// *************************************************************************** *
// *                                                                           *
// * Description:         CANDB File                                           *
// * Generated at:        2023-04-23 21:52                                     *
// * System:              SDB22400                                             *
// * Variant:             KX11_A2_ADCU2_VCU2_PCM                               *
// * Network:             ChassisCAN1                                          *
// *                                                                           *
// *************************************************************************** *
VERSION "ChassisCAN1"

NS_ :

BS_ :

BU_ :  ASDM BBM ECM ETC PSCM1 SAS TCM VDDM

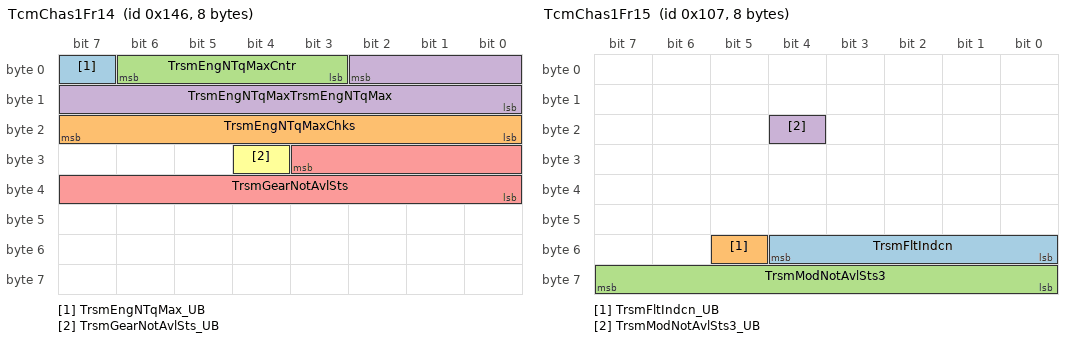
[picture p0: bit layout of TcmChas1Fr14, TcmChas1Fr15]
BO_ 326 TcmChas1Fr14 : 8 TCM
 SG_ TrsmEngNTqMax_UB : 7|1@0+ (1,0) [0|1] "" ECM
 SG_ TrsmEngNTqMaxChks : 23|8@0+ (1.0,0.0) [0.0|255.0] "Unitless" ECM
 SG_ TrsmEngNTqMaxCntr : 6|4@0+ (1.0,0.0) [0.0|15.0] "Unitless" ECM
 SG_ TrsmEngNTqMaxTrsmEngNTqMax : 2|11@0+ (1.0,-1024.0) [-1024.0|1023.0] "NewtonMeter" ECM
 SG_ TrsmGearNotAvlSts : 27|12@0+ (1.0,0.0) [0.0|4095.0] "Unitless" ECM
 SG_ TrsmGearNotAvlSts_UB : 28|1@0+ (1,0) [0|1] "" ECM

BO_ 263 TcmChas1Fr15 : 8 TCM
 SG_ TrsmFltIndcn : 52|5@0+ (1,0) [0|31] "" ECM,VDDM
 SG_ TrsmFltIndcn_UB : 53|1@0+ (1,0) [0|1] "" ECM,VDDM
 SG_ TrsmModNotAvlSts3 : 63|8@0+ (1.0,0.0) [0.0|255.0] "Unitless" ECM
 SG_ TrsmModNotAvlSts3_UB : 20|1@0+ (1,0) [0|1] "" ECM

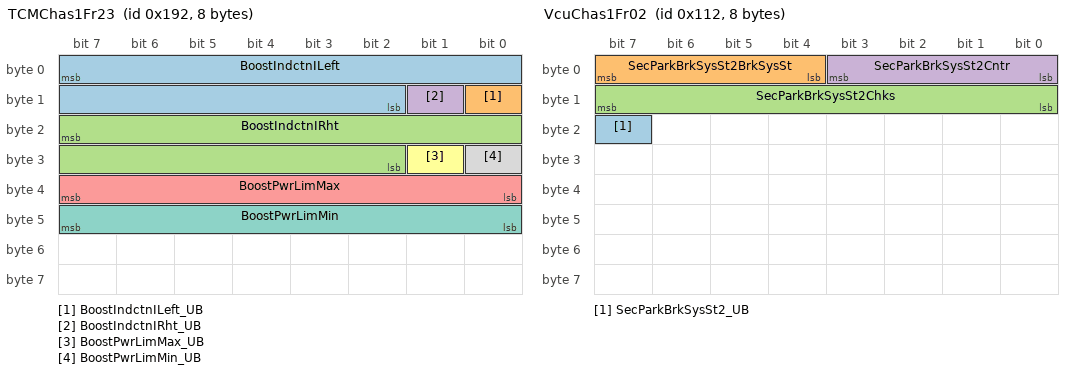
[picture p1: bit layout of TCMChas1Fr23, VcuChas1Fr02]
BO_ 402 TCMChas1Fr23 : 8 TCM
 SG_ BoostIndctnILeft : 7|14@0+ (0.1,-818.8) [-818.8|819.2] "A" ECM
 SG_ BoostIndctnILeft_UB : 8|1@0+ (1,0) [0|1] "" ECM
 SG_ BoostIndctnIRht : 23|14@0+ (0.1,-818.8) [-818.8|819.2] "A" ECM
 SG_ BoostIndctnIRht_UB : 9|1@0+ (1,0) [0|1] "" ECM
 SG_ BoostPwrLimMax : 39|8@0+ (1.0,0.0) [0.0|255.0] "kW" ECM
 SG_ BoostPwrLimMax_UB : 25|1@0+ (1,0) [0|1] "" ECM
 SG_ BoostPwrLimMin : 47|8@0+ (1.0,-255.0) [-255.0|0.0] "kW" ECM
 SG_ BoostPwrLimMin_UB : 24|1@0+ (1,0) [0|1] "" ECM

BO_ 1328 TcmChas1NMFr : 8 TCM
 SG_ PNC16_TCM : 16|1@0+ (1,0) [0|0] "" SAS
 SG_ PNC17_TCM : 17|1@0+ (1,0) [0|0] "" SAS
 SG_ PNC18_TCM : 18|1@0+ (1,0) [0|0] "" SAS
 SG_ PNC19_TCM : 19|1@0+ (1,0) [0|0] "" SAS
 SG_ PNC20_TCM : 20|1@0+ (1,0) [0|0] "" SAS
 SG_ PNC21_TCM : 21|1@0+ (1,0) [0|0] "" SAS
 SG_ PNC22_TCM : 22|1@0+ (1,0) [0|0] "" SAS
 SG_ PNC23_TCM : 23|1@0+ (1,0) [0|0] "" SAS
 SG_ PNC24_TCM : 24|1@0+ (1,0) [0|0] "" SAS
 SG_ PNC25_TCM : 25|1@0+ (1,0) [0|0] "" SAS
 SG_ PNC26_TCM : 26|1@0+ (1,0) [0|0] "" SAS
 SG_ PNC27_TCM : 27|1@0+ (1,0) [0|0] "" SAS
 SG_ PNC28_TCM : 28|1@0+ (1,0) [0|0] "" SAS
 SG_ PNC29_TCM : 29|1@0+ (1,0) [0|0] "" SAS
 SG_ PNC30_TCM : 30|1@0+ (1,0) [0|0] "" SAS
 SG_ PNC31_TCM : 31|1@0+ (1,0) [0|0] "" SAS
 SG_ PNC32_TCM : 32|1@0+ (1,0) [0|0] "" SAS
 SG_ PNC33_TCM : 33|1@0+ (1,0) [0|0] "" SAS
 SG_ PNC34_TCM : 34|1@0+ (1,0) [0|0] "" SAS
 SG_ PNC35_TCM : 35|1@0+ (1,0) [0|0] "" SAS
 SG_ PNC36_TCM : 36|1@0+ (1,0) [0|0] "" SAS
 SG_ PNC37_TCM : 37|1@0+ (1,0) [0|0] "" SAS
 SG_ PNC38_TCM : 38|1@0+ (1,0) [0|0] "" SAS
 SG_ PNC39_TCM : 39|1@0+ (1,0) [0|0] "" SAS
 SG_ PNC40_TCM : 40|1@0+ (1,0) [0|0] "" SAS
 SG_ PNC41_TCM : 41|1@0+ (1,0) [0|0] "" SAS
 SG_ PNC42_TCM : 42|1@0+ (1,0) [0|0] "" SAS
 SG_ NM_PNI_TCM : 14|1@0+ (1,0) [0|0] "" SAS
 SG_ NM_AW_TCM : 12|1@0+ (1,0) [0|0] "" SAS
 SG_ NM_CS_TCM : 11|1@0+ (1,0) [0|0] "" SAS
 SG_ NM_RMR_TCM : 8|1@0+ (1,0) [0|0] "" SAS
 SG_ NM_NodeID_TCM : 7|8@0+ (1,0) [0|0] "" SAS

BO_ 756 TCMChas1VfcFr19 : 8 TCM
 SG_ VFCVectorPCMBlockID : 1|2@0+ (1.0,0.0) [0.0|3.0] "Unitless" ETC
 SG_ VFCVectorPCMVFCid0 : 2|1@0+ (1,0) [0|1] "" ETC
 SG_ VFCVectorPCMVFCid1 : 3|1@0+ (1,0) [0|1] "" ETC
 SG_ VFCVectorPCMVFCid10 : 12|1@0+ (1,0) [0|1] "" ETC
 SG_ VFCVectorPCMVFCid11 : 13|1@0+ (1,0) [0|1] "" ETC
 SG_ VFCVectorPCMVFCid12 : 14|1@0+ (1,0) [0|1] "" ETC
 SG_ VFCVectorPCMVFCid13 : 15|1@0+ (1,0) [0|1] "" ETC
 SG_ VFCVectorPCMVFCid14 : 16|1@0+ (1,0) [0|1] "" ETC
 SG_ VFCVectorPCMVFCid15 : 17|1@0+ (1,0) [0|1] "" ETC
 SG_ VFCVectorPCMVFCid16 : 18|1@0+ (1,0) [0|1] "" ETC
 SG_ VFCVectorPCMVFCid17 : 19|1@0+ (1,0) [0|1] "" ETC
 SG_ VFCVectorPCMVFCid18 : 20|1@0+ (1,0) [0|1] "" ETC
 SG_ VFCVectorPCMVFCid19 : 21|1@0+ (1,0) [0|1] "" ETC
 SG_ VFCVectorPCMVFCid2 : 4|1@0+ (1,0) [0|1] "" ETC
 SG_ VFCVectorPCMVFCid20 : 22|1@0+ (1,0) [0|1] "" ETC
 SG_ VFCVectorPCMVFCid21 : 23|1@0+ (1,0) [0|1] "" ETC
 SG_ VFCVectorPCMVFCid22 : 24|1@0+ (1,0) [0|1] "" ETC
 SG_ VFCVectorPCMVFCid23 : 25|1@0+ (1,0) [0|1] "" ETC
 SG_ VFCVectorPCMVFCid24 : 26|1@0+ (1,0) [0|1] "" ETC
 SG_ VFCVectorPCMVFCid25 : 27|1@0+ (1,0) [0|1] "" ETC
 SG_ VFCVectorPCMVFCid26 : 28|1@0+ (1,0) [0|1] "" ETC
 SG_ VFCVectorPCMVFCid27 : 29|1@0+ (1,0) [0|1] "" ETC
 SG_ VFCVectorPCMVFCid28 : 30|1@0+ (1,0) [0|1] "" ETC
 SG_ VFCVectorPCMVFCid29 : 31|1@0+ (1,0) [0|1] "" ETC
 SG_ VFCVectorPCMVFCid3 : 5|1@0+ (1,0) [0|1] "" ETC
 SG_ VFCVectorPCMVFCid30 : 32|1@0+ (1,0) [0|1] "" ETC
 SG_ VFCVectorPCMVFCid31 : 33|1@0+ (1,0) [0|1] "" ETC
 SG_ VFCVectorPCMVFCid32 : 34|1@0+ (1,0) [0|1] "" ETC
 SG_ VFCVectorPCMVFCid33 : 35|1@0+ (1,0) [0|1] "" ETC
 SG_ VFCVectorPCMVFCid34 : 36|1@0+ (1,0) [0|1] "" ETC
 SG_ VFCVectorPCMVFCid35 : 37|1@0+ (1,0) [0|1] "" ETC
 SG_ VFCVectorPCMVFCid36 : 38|1@0+ (1,0) [0|1] "" ETC
 SG_ VFCVectorPCMVFCid37 : 39|1@0+ (1,0) [0|1] "" ETC
 SG_ VFCVectorPCMVFCid38 : 40|1@0+ (1,0) [0|1] "" ETC
 SG_ VFCVectorPCMVFCid39 : 41|1@0+ (1,0) [0|1] "" ETC
 SG_ VFCVectorPCMVFCid4 : 6|1@0+ (1,0) [0|1] "" ETC
 SG_ VFCVectorPCMVFCid40 : 42|1@0+ (1,0) [0|1] "" ETC
 SG_ VFCVectorPCMVFCid41 : 43|1@0+ (1,0) [0|1] "" ETC
 SG_ VFCVectorPCMVFCid42 : 44|1@0+ (1,0) [0|1] "" ETC
 SG_ VFCVectorPCMVFCid43 : 45|1@0+ (1,0) [0|1] "" ETC
 SG_ VFCVectorPCMVFCid44 : 46|1@0+ (1,0) [0|1] "" ETC
 SG_ VFCVectorPCMVFCid45 : 47|1@0+ (1,0) [0|1] "" ETC
 SG_ VFCVectorPCMVFCid46 : 48|1@0+ (1,0) [0|1] "" ETC
 SG_ VFCVectorPCMVFCid47 : 49|1@0+ (1,0) [0|1] "" ETC
 SG_ VFCVectorPCMVFCid48 : 50|1@0+ (1,0) [0|1] "" ETC
 SG_ VFCVectorPCMVFCid49 : 51|1@0+ (1,0) [0|1] "" ETC
 SG_ VFCVectorPCMVFCid5 : 7|1@0+ (1,0) [0|1] "" ETC
 SG_ VFCVectorPCMVFCid50 : 52|1@0+ (1,0) [0|1] "" ETC
 SG_ VFCVectorPCMVFCid51 : 53|1@0+ (1,0) [0|1] "" ETC
 SG_ VFCVectorPCMVFCid52 : 54|1@0+ (1,0) [0|1] "" ETC
 SG_ VFCVectorPCMVFCid53 : 55|1@0+ (1,0) [0|1] "" ETC
 SG_ VFCVectorPCMVFCid54 : 56|1@0+ (1,0) [0|1] "" ETC
 SG_ VFCVectorPCMVFCid55 : 57|1@0+ (1,0) [0|1] "" ETC
 SG_ VFCVectorPCMVFCid56 : 58|1@0+ (1,0) [0|1] "" ETC
 SG_ VFCVectorPCMVFCid57 : 59|1@0+ (1,0) [0|1] "" ETC
 SG_ VFCVectorPCMVFCid58 : 60|1@0+ (1,0) [0|1] "" ETC
 SG_ VFCVectorPCMVFCid59 : 61|1@0+ (1,0) [0|1] "" ETC
 SG_ VFCVectorPCMVFCid6 : 8|1@0+ (1,0) [0|1] "" ETC
 SG_ VFCVectorPCMVFCid60 : 62|1@0+ (1,0) [0|1] "" ETC
 SG_ VFCVectorPCMVFCid61 : 63|1@0+ (1,0) [0|1] "" ETC
 SG_ VFCVectorPCMVFCid7 : 9|1@0+ (1,0) [0|1] "" ETC
 SG_ VFCVectorPCMVFCid8 : 10|1@0+ (1,0) [0|1] "" ETC
 SG_ VFCVectorPCMVFCid9 : 11|1@0+ (1,0) [0|1] "" ETC

BO_ 274 VcuChas1Fr02 : 8 VDDM
 SG_ SecParkBrkSysSt2_UB : 23|1@0+ (1,0) [0|1] "" BBM
 SG_ SecParkBrkSysSt2BrkSysSt : 7|4@0+ (1,0) [0|15] "" BBM
 SG_ SecParkBrkSysSt2Chks : 15|8@0+ (1.0,0.0) [0.0|255.0] "Unitless" BBM
 SG_ SecParkBrkSysSt2Cntr : 3|4@0+ (1.0,0.0) [0.0|15.0] "Unitless" BBM

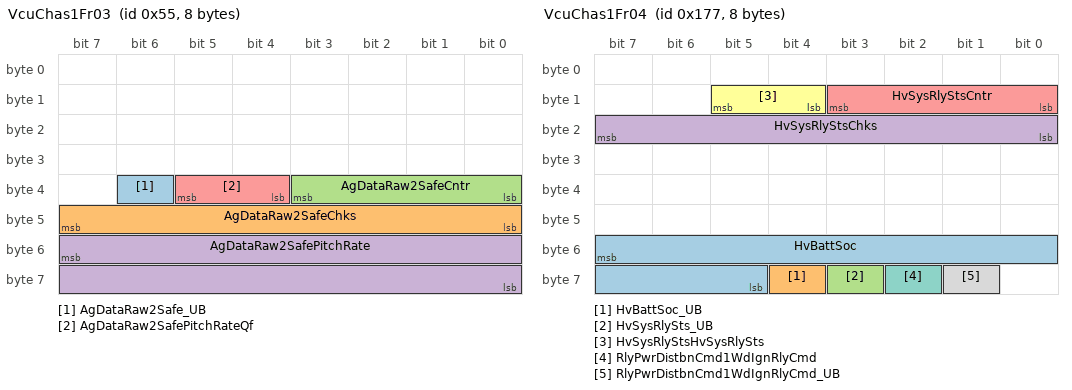
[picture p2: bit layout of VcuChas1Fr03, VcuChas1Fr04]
BO_ 85 VcuChas1Fr03 : 8 VDDM
 SG_ AgDataRaw2Safe_UB : 38|1@0+ (1,0) [0|1] "" Vector__XXX
 SG_ AgDataRaw2SafeChks : 47|8@0+ (1.0,0.0) [0.0|255.0] "Unitless" Vector__XXX
 SG_ AgDataRaw2SafeCntr : 35|4@0+ (1.0,0.0) [0.0|15.0] "Unitless" Vector__XXX
 SG_ AgDataRaw2SafePitchRate : 55|16@0- (0.000244140625,0.0) [-6.0|6.0] "rad/s" Vector__XXX
 SG_ AgDataRaw2SafePitchRateQf : 37|2@0+ (1,0) [0|3] "" Vector__XXX

BO_ 375 VcuChas1Fr04 : 8 VDDM
 SG_ HvBattSoc : 55|11@0+ (0.05,0.0) [0.0|100.0] "%" Vector__XXX
 SG_ HvBattSoc_UB : 60|1@0+ (1,0) [0|1] "" Vector__XXX
 SG_ HvSysRlySts_UB : 59|1@0+ (1,0) [0|1] "" Vector__XXX
 SG_ HvSysRlyStsChks : 23|8@0+ (1.0,0.0) [0.0|255.0] "Unitless" Vector__XXX
 SG_ HvSysRlyStsCntr : 11|4@0+ (1.0,0.0) [0.0|15.0] "Unitless" Vector__XXX
 SG_ HvSysRlyStsHvSysRlySts : 13|2@0+ (1,0) [0|3] "" Vector__XXX
 SG_ RlyPwrDistbnCmd1WdIgnRlyCmd : 58|1@0+ (1,0) [0|1] "" Vector__XXX
 SG_ RlyPwrDistbnCmd1WdIgnRlyCmd_UB : 57|1@0+ (1,0) [0|1] "" Vector__XXX

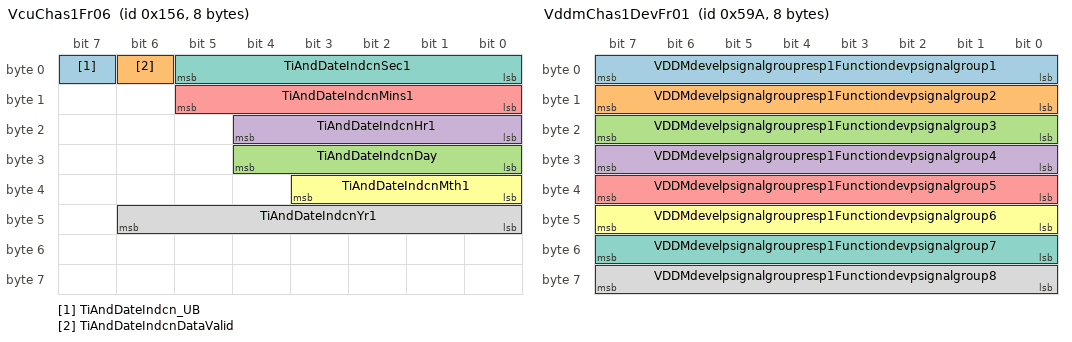
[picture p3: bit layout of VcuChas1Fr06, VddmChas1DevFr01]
BO_ 342 VcuChas1Fr06 : 8 VDDM
 SG_ TiAndDateIndcn_UB : 7|1@0+ (1,0) [0|1] "" Vector__XXX
 SG_ TiAndDateIndcnDataValid : 6|1@0+ (1,0) [0|1] "" Vector__XXX
 SG_ TiAndDateIndcnDay : 28|5@0+ (1.0,0.0) [1.0|31.0] "Days" Vector__XXX
 SG_ TiAndDateIndcnHr1 : 20|5@0+ (1.0,0.0) [0.0|23.0] "hours" Vector__XXX
 SG_ TiAndDateIndcnMins1 : 13|6@0+ (1.0,0.0) [0.0|59.0] "Mins" Vector__XXX
 SG_ TiAndDateIndcnMth1 : 35|4@0+ (1.0,0.0) [1.0|12.0] "Month" Vector__XXX
 SG_ TiAndDateIndcnSec1 : 5|6@0+ (1.0,0.0) [0.0|59.0] "s" Vector__XXX
 SG_ TiAndDateIndcnYr1 : 46|7@0+ (1.0,0.0) [0.0|99.0] "Year" Vector__XXX

BO_ 1365 VcuChas1VFCVectorFr : 8 VDDM
 SG_ VFCVectorVCUBlockID : 1|2@0+ (1.0,0.0) [0.0|3.0] "Unitless" ETC
 SG_ VFCVectorVCUVFCid0 : 2|1@0+ (1,0) [0|1] "" ETC
 SG_ VFCVectorVCUVFCid1 : 3|1@0+ (1,0) [0|1] "" ETC
 SG_ VFCVectorVCUVFCid10 : 12|1@0+ (1,0) [0|1] "" ETC
 SG_ VFCVectorVCUVFCid11 : 13|1@0+ (1,0) [0|1] "" ETC
 SG_ VFCVectorVCUVFCid12 : 14|1@0+ (1,0) [0|1] "" ETC
 SG_ VFCVectorVCUVFCid13 : 15|1@0+ (1,0) [0|1] "" ETC
 SG_ VFCVectorVCUVFCid14 : 16|1@0+ (1,0) [0|1] "" ETC
 SG_ VFCVectorVCUVFCid15 : 17|1@0+ (1,0) [0|1] "" ETC
 SG_ VFCVectorVCUVFCid16 : 18|1@0+ (1,0) [0|1] "" ETC
 SG_ VFCVectorVCUVFCid17 : 19|1@0+ (1,0) [0|1] "" ETC
 SG_ VFCVectorVCUVFCid18 : 20|1@0+ (1,0) [0|1] "" ETC
 SG_ VFCVectorVCUVFCid19 : 21|1@0+ (1,0) [0|1] "" ETC
 SG_ VFCVectorVCUVFCid2 : 4|1@0+ (1,0) [0|1] "" ETC
 SG_ VFCVectorVCUVFCid20 : 22|1@0+ (1,0) [0|1] "" ETC
 SG_ VFCVectorVCUVFCid21 : 23|1@0+ (1,0) [0|1] "" ETC
 SG_ VFCVectorVCUVFCid22 : 24|1@0+ (1,0) [0|1] "" ETC
 SG_ VFCVectorVCUVFCid23 : 25|1@0+ (1,0) [0|1] "" ETC
 SG_ VFCVectorVCUVFCid24 : 26|1@0+ (1,0) [0|1] "" ETC
 SG_ VFCVectorVCUVFCid25 : 27|1@0+ (1,0) [0|1] "" ETC
 SG_ VFCVectorVCUVFCid26 : 28|1@0+ (1,0) [0|1] "" ETC
 SG_ VFCVectorVCUVFCid27 : 29|1@0+ (1,0) [0|1] "" ETC
 SG_ VFCVectorVCUVFCid28 : 30|1@0+ (1,0) [0|1] "" ETC
 SG_ VFCVectorVCUVFCid29 : 31|1@0+ (1,0) [0|1] "" ETC
 SG_ VFCVectorVCUVFCid3 : 5|1@0+ (1,0) [0|1] "" ETC
 SG_ VFCVectorVCUVFCid30 : 32|1@0+ (1,0) [0|1] "" ETC
 SG_ VFCVectorVCUVFCid31 : 33|1@0+ (1,0) [0|1] "" ETC
 SG_ VFCVectorVCUVFCid32 : 34|1@0+ (1,0) [0|1] "" ETC
 SG_ VFCVectorVCUVFCid33 : 35|1@0+ (1,0) [0|1] "" ETC
 SG_ VFCVectorVCUVFCid34 : 36|1@0+ (1,0) [0|1] "" ETC
 SG_ VFCVectorVCUVFCid35 : 37|1@0+ (1,0) [0|1] "" ETC
 SG_ VFCVectorVCUVFCid36 : 38|1@0+ (1,0) [0|1] "" ETC
 SG_ VFCVectorVCUVFCid37 : 39|1@0+ (1,0) [0|1] "" ETC
 SG_ VFCVectorVCUVFCid38 : 40|1@0+ (1,0) [0|1] "" ETC
 SG_ VFCVectorVCUVFCid39 : 41|1@0+ (1,0) [0|1] "" ETC
 SG_ VFCVectorVCUVFCid4 : 6|1@0+ (1,0) [0|1] "" ETC
 SG_ VFCVectorVCUVFCid40 : 42|1@0+ (1,0) [0|1] "" ETC
 SG_ VFCVectorVCUVFCid41 : 43|1@0+ (1,0) [0|1] "" ETC
 SG_ VFCVectorVCUVFCid42 : 44|1@0+ (1,0) [0|1] "" ETC
 SG_ VFCVectorVCUVFCid43 : 45|1@0+ (1,0) [0|1] "" ETC
 SG_ VFCVectorVCUVFCid44 : 46|1@0+ (1,0) [0|1] "" ETC
 SG_ VFCVectorVCUVFCid45 : 47|1@0+ (1,0) [0|1] "" ETC
 SG_ VFCVectorVCUVFCid46 : 48|1@0+ (1,0) [0|1] "" ETC
 SG_ VFCVectorVCUVFCid47 : 49|1@0+ (1,0) [0|1] "" ETC
 SG_ VFCVectorVCUVFCid48 : 50|1@0+ (1,0) [0|1] "" ETC
 SG_ VFCVectorVCUVFCid49 : 51|1@0+ (1,0) [0|1] "" ETC
 SG_ VFCVectorVCUVFCid5 : 7|1@0+ (1,0) [0|1] "" ETC
 SG_ VFCVectorVCUVFCid50 : 52|1@0+ (1,0) [0|1] "" ETC
 SG_ VFCVectorVCUVFCid51 : 53|1@0+ (1,0) [0|1] "" ETC
 SG_ VFCVectorVCUVFCid52 : 54|1@0+ (1,0) [0|1] "" ETC
 SG_ VFCVectorVCUVFCid53 : 55|1@0+ (1,0) [0|1] "" ETC
 SG_ VFCVectorVCUVFCid54 : 56|1@0+ (1,0) [0|1] "" ETC
 SG_ VFCVectorVCUVFCid55 : 57|1@0+ (1,0) [0|1] "" ETC
 SG_ VFCVectorVCUVFCid56 : 58|1@0+ (1,0) [0|1] "" ETC
 SG_ VFCVectorVCUVFCid57 : 59|1@0+ (1,0) [0|1] "" ETC
 SG_ VFCVectorVCUVFCid58 : 60|1@0+ (1,0) [0|1] "" ETC
 SG_ VFCVectorVCUVFCid59 : 61|1@0+ (1,0) [0|1] "" ETC
 SG_ VFCVectorVCUVFCid6 : 8|1@0+ (1,0) [0|1] "" ETC
 SG_ VFCVectorVCUVFCid60 : 62|1@0+ (1,0) [0|1] "" ETC
 SG_ VFCVectorVCUVFCid61 : 63|1@0+ (1,0) [0|1] "" ETC
 SG_ VFCVectorVCUVFCid7 : 9|1@0+ (1,0) [0|1] "" ETC
 SG_ VFCVectorVCUVFCid8 : 10|1@0+ (1,0) [0|1] "" ETC
 SG_ VFCVectorVCUVFCid9 : 11|1@0+ (1,0) [0|1] "" ETC

BO_ 1434 VddmChas1DevFr01 : 8 BBM
 SG_ VDDMdevelpsignalgroupresp1Functiondevpsignalgroup1 : 7|8@0+ (1.0,0.0) [0.0|255.0] "Unitless" ETC
 SG_ VDDMdevelpsignalgroupresp1Functiondevpsignalgroup2 : 15|8@0+ (1.0,0.0) [0.0|255.0] "Unitless" ETC
 SG_ VDDMdevelpsignalgroupresp1Functiondevpsignalgroup3 : 23|8@0+ (1.0,0.0) [0.0|255.0] "Unitless" ETC
 SG_ VDDMdevelpsignalgroupresp1Functiondevpsignalgroup4 : 31|8@0+ (1.0,0.0) [0.0|255.0] "Unitless" ETC
 SG_ VDDMdevelpsignalgroupresp1Functiondevpsignalgroup5 : 39|8@0+ (1.0,0.0) [0.0|255.0] "Unitless" ETC
 SG_ VDDMdevelpsignalgroupresp1Functiondevpsignalgroup6 : 47|8@0+ (1.0,0.0) [0.0|255.0] "Unitless" ETC
 SG_ VDDMdevelpsignalgroupresp1Functiondevpsignalgroup7 : 55|8@0+ (1.0,0.0) [0.0|255.0] "Unitless" ETC
 SG_ VDDMdevelpsignalgroupresp1Functiondevpsignalgroup8 : 63|8@0+ (1.0,0.0) [0.0|255.0] "Unitless" ETC

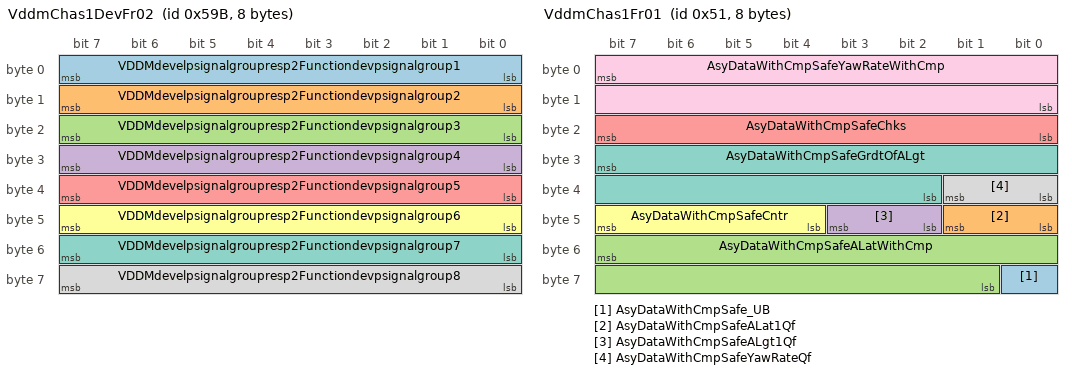
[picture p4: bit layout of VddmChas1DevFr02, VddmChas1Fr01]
BO_ 1435 VddmChas1DevFr02 : 8 BBM
 SG_ VDDMdevelpsignalgroupresp2Functiondevpsignalgroup1 : 7|8@0+ (1.0,0.0) [0.0|255.0] "Unitless" ETC
 SG_ VDDMdevelpsignalgroupresp2Functiondevpsignalgroup2 : 15|8@0+ (1.0,0.0) [0.0|255.0] "Unitless" ETC
 SG_ VDDMdevelpsignalgroupresp2Functiondevpsignalgroup3 : 23|8@0+ (1.0,0.0) [0.0|255.0] "Unitless" ETC
 SG_ VDDMdevelpsignalgroupresp2Functiondevpsignalgroup4 : 31|8@0+ (1.0,0.0) [0.0|255.0] "Unitless" ETC
 SG_ VDDMdevelpsignalgroupresp2Functiondevpsignalgroup5 : 39|8@0+ (1.0,0.0) [0.0|255.0] "Unitless" ETC
 SG_ VDDMdevelpsignalgroupresp2Functiondevpsignalgroup6 : 47|8@0+ (1.0,0.0) [0.0|255.0] "Unitless" ETC
 SG_ VDDMdevelpsignalgroupresp2Functiondevpsignalgroup7 : 55|8@0+ (1.0,0.0) [0.0|255.0] "Unitless" ETC
 SG_ VDDMdevelpsignalgroupresp2Functiondevpsignalgroup8 : 63|8@0+ (1.0,0.0) [0.0|255.0] "Unitless" ETC

BO_ 81 VddmChas1Fr01 : 8 VDDM
 SG_ AsyDataWithCmpSafe_UB : 56|1@0+ (1,0) [0|1] "" PSCM1
 SG_ AsyDataWithCmpSafeALat1Qf : 41|2@0+ (1,0) [0|3] "" PSCM1
 SG_ AsyDataWithCmpSafeALatWithCmp : 55|15@0- (0.0085,0.0) [-138.99200000000002|139.00050000000002] "m/s^2" PSCM1
 SG_ AsyDataWithCmpSafeALgt1Qf : 43|2@0+ (1,0) [0|3] "" PSCM1
 SG_ AsyDataWithCmpSafeChks : 23|8@0+ (1.0,0.0) [0.0|255.0] "Unitless" PSCM1
 SG_ AsyDataWithCmpSafeCntr : 47|4@0+ (1.0,0.0) [0.0|15.0] "Unitless" PSCM1
 SG_ AsyDataWithCmpSafeGrdtOfALgt : 31|14@0- (0.00390625,0.0) [-30.0|30.0] "m/s^3" PSCM1
 SG_ AsyDataWithCmpSafeYawRateQf : 33|2@0+ (1,0) [0|3] "" PSCM1
 SG_ AsyDataWithCmpSafeYawRateWithCmp : 7|16@0- (0.000244140625,0.0) [-6.0|6.0] "rad/s" PSCM1

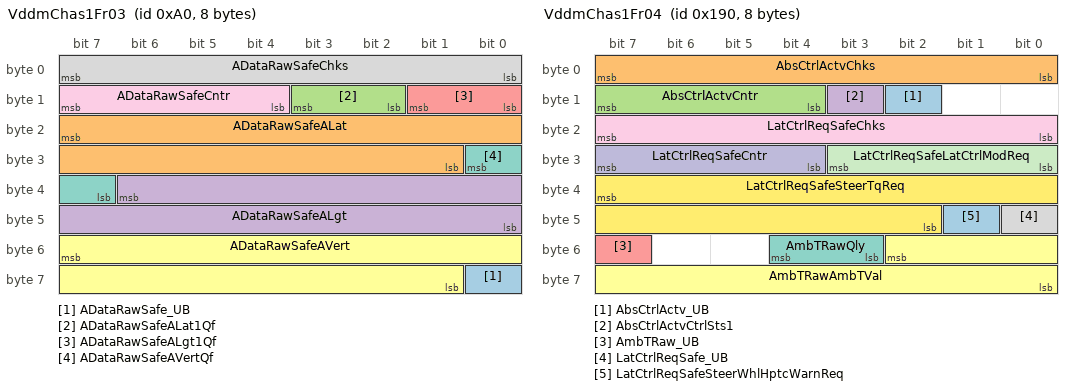
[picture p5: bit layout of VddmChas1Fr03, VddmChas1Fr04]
BO_ 160 VddmChas1Fr03 : 8 VDDM
 SG_ ADataRawSafe_UB : 56|1@0+ (1,0) [0|1] "" PSCM1
 SG_ ADataRawSafeALat : 23|15@0- (0.0085,0.0) [-138.99200000000002|139.00050000000002] "m/s^2" PSCM1
 SG_ ADataRawSafeALat1Qf : 11|2@0+ (1,0) [0|3] "" PSCM1
 SG_ ADataRawSafeALgt : 38|15@0- (0.0085,0.0) [-138.99200000000002|139.00050000000002] "m/s^2" PSCM1
 SG_ ADataRawSafeALgt1Qf : 9|2@0+ (1,0) [0|3] "" PSCM1
 SG_ ADataRawSafeAVert : 55|15@0- (0.0085,0.0) [-138.99200000000002|139.00050000000002] "m/s^2" PSCM1
 SG_ ADataRawSafeAVertQf : 24|2@0+ (1,0) [0|3] "" PSCM1
 SG_ ADataRawSafeChks : 7|8@0+ (1.0,0.0) [0.0|255.0] "Unitless" PSCM1
 SG_ ADataRawSafeCntr : 15|4@0+ (1.0,0.0) [0.0|15.0] "Unitless" PSCM1

BO_ 400 VddmChas1Fr04 : 8 BBM
 SG_ AbsCtrlActv_UB : 10|1@0+ (1,0) [0|1] "" ECM,PSCM1
 SG_ AbsCtrlActvChks : 7|8@0+ (1.0,0.0) [0.0|255.0] "Unitless" ECM,PSCM1
 SG_ AbsCtrlActvCntr : 15|4@0+ (1.0,0.0) [0.0|15.0] "Unitless" ECM,PSCM1
 SG_ AbsCtrlActvCtrlSts1 : 11|1@0+ (1,0) [0|1] "" ECM,PSCM1
 SG_ AmbTRaw_UB : 55|1@0+ (1,0) [0|1] "" PSCM1
 SG_ AmbTRawAmbTVal : 50|11@0+ (0.1,-70.0) [-70.0|134.70000000000002] "degC" PSCM1
 SG_ AmbTRawQly : 52|2@0+ (1,0) [0|3] "" PSCM1
 SG_ LatCtrlReqSafe_UB : 40|1@0+ (1,0) [0|1] "" PSCM1
 SG_ LatCtrlReqSafeChks : 23|8@0+ (1.0,0.0) [0.0|255.0] "Unitless" PSCM1
 SG_ LatCtrlReqSafeCntr : 31|4@0+ (1.0,0.0) [0.0|15.0] "Unitless" PSCM1
 SG_ LatCtrlReqSafeLatCtrlModReq : 27|4@0+ (1,0) [0|15] "" PSCM1
 SG_ LatCtrlReqSafeSteerTqReq : 39|14@0- (0.00390625,0.0) [-30.0|30.0] "NewtonMeter" PSCM1
 SG_ LatCtrlReqSafeSteerWhlHptcWarnReq : 41|1@0+ (1,0) [0|1] "" PSCM1

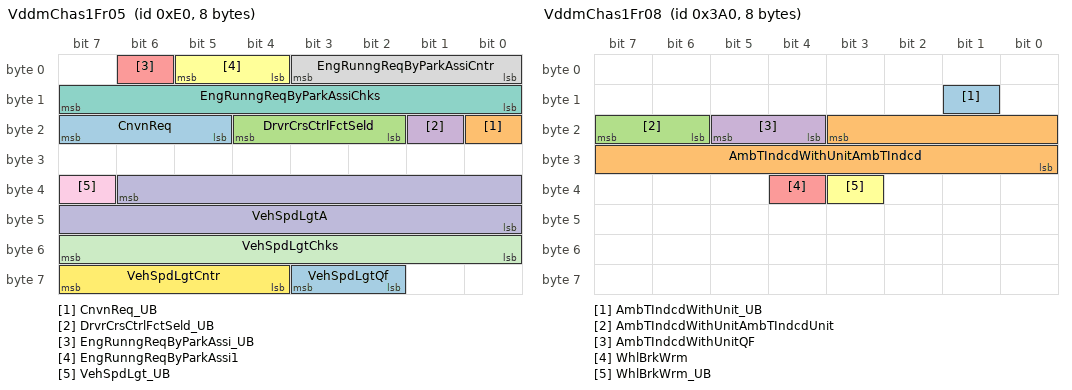
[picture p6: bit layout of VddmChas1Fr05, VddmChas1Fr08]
BO_ 224 VddmChas1Fr05 : 8 BBM
 SG_ CnvnReq : 23|3@0+ (1,0) [0|7] "" ECM
 SG_ CnvnReq_UB : 16|1@0+ (1,0) [0|1] "" ECM
 SG_ DrvrCrsCtrlFctSeld : 20|3@0+ (1,0) [0|7] "" ECM
 SG_ DrvrCrsCtrlFctSeld_UB : 17|1@0+ (1,0) [0|1] "" ECM
 SG_ EngRunngReqByParkAssi_UB : 6|1@0+ (1,0) [0|1] "" ECM
 SG_ EngRunngReqByParkAssi1 : 5|2@0+ (1,0) [0|3] "" ECM
 SG_ EngRunngReqByParkAssiChks : 15|8@0+ (1.0,0.0) [0.0|255.0] "Unitless" ECM
 SG_ EngRunngReqByParkAssiCntr : 3|4@0+ (1.0,0.0) [0.0|15.0] "Unitless" ECM
 SG_ VehSpdLgt_UB : 39|1@0+ (1,0) [0|1] "" PSCM1,SAS
 SG_ VehSpdLgtA : 38|15@0+ (0.00391,0.0) [0.0|125.0027] "m/s" PSCM1,SAS
 SG_ VehSpdLgtChks : 55|8@0+ (1.0,0.0) [0.0|255.0] "Unitless" PSCM1,SAS
 SG_ VehSpdLgtCntr : 63|4@0+ (1.0,0.0) [0.0|15.0] "Unitless" PSCM1,SAS
 SG_ VehSpdLgtQf : 59|2@0+ (1,0) [0|3] "" PSCM1,SAS

BO_ 928 VddmChas1Fr08 : 8 BBM
 SG_ AmbTIndcdWithUnit_UB : 9|1@0+ (1,0) [0|1] "" SAS
 SG_ AmbTIndcdWithUnitAmbTIndcd : 19|12@0+ (0.1,-100.0) [-100.0|309.5] "Unitless" SAS
 SG_ AmbTIndcdWithUnitAmbTIndcdUnit : 23|2@0+ (1,0) [0|3] "" SAS
 SG_ AmbTIndcdWithUnitQF : 21|2@0+ (1,0) [0|3] "" SAS
 SG_ WhlBrkWrm : 36|1@0+ (1,0) [0|1] "" Vector__XXX
 SG_ WhlBrkWrm_UB : 35|1@0+ (1,0) [0|1] "" Vector__XXX

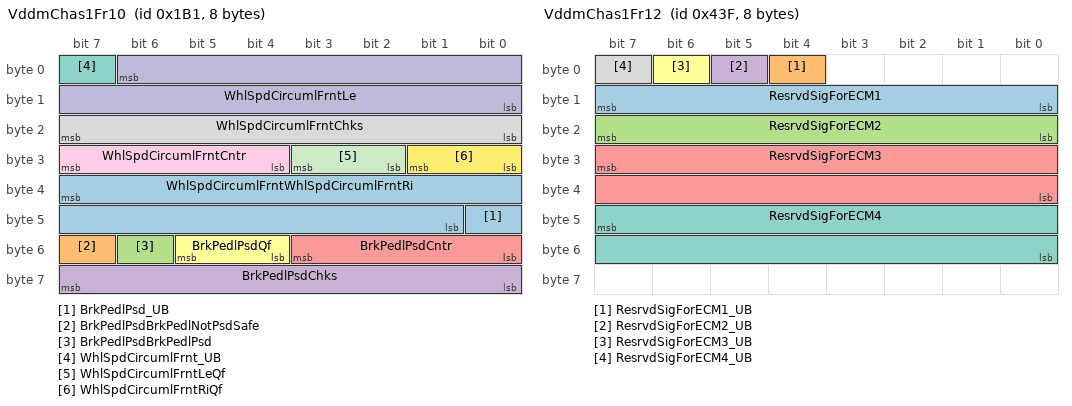
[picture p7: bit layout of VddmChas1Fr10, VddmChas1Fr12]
BO_ 433 VddmChas1Fr10 : 8 BBM
 SG_ BrkPedlPsd_UB : 40|1@0+ (1,0) [0|1] "" PSCM1
 SG_ BrkPedlPsdBrkPedlNotPsdSafe : 55|1@0+ (1,0) [0|1] "" PSCM1
 SG_ BrkPedlPsdBrkPedlPsd : 54|1@0+ (1,0) [0|1] "" PSCM1
 SG_ BrkPedlPsdChks : 63|8@0+ (1.0,0.0) [0.0|255.0] "Unitless" PSCM1
 SG_ BrkPedlPsdCntr : 51|4@0+ (1.0,0.0) [0.0|15.0] "Unitless" PSCM1
 SG_ BrkPedlPsdQf : 53|2@0+ (1,0) [0|3] "" PSCM1
 SG_ WhlSpdCircumlFrnt_UB : 7|1@0+ (1,0) [0|1] "" ECM,PSCM1
 SG_ WhlSpdCircumlFrntChks : 23|8@0+ (1.0,0.0) [0.0|255.0] "Unitless" ECM,PSCM1
 SG_ WhlSpdCircumlFrntCntr : 31|4@0+ (1.0,0.0) [0.0|15.0] "Unitless" ECM,PSCM1
 SG_ WhlSpdCircumlFrntLe : 6|15@0+ (0.00391,0.0) [0.0|125.0027] "m/s" ECM,PSCM1
 SG_ WhlSpdCircumlFrntLeQf : 27|2@0+ (1,0) [0|3] "" ECM,PSCM1
 SG_ WhlSpdCircumlFrntRiQf : 25|2@0+ (1,0) [0|3] "" ECM,PSCM1
 SG_ WhlSpdCircumlFrntWhlSpdCircumlFrntRi : 39|15@0+ (0.00391,0.0) [0.0|125.0027] "m/s" ECM,PSCM1

BO_ 1087 VddmChas1Fr12 : 8 VDDM
 SG_ ResrvdSigForECM1 : 15|8@0+ (1.0,0.0) [0.0|255.0] "Unitless" Vector__XXX
 SG_ ResrvdSigForECM1_UB : 4|1@0+ (1,0) [0|1] "" Vector__XXX
 SG_ ResrvdSigForECM2 : 23|8@0+ (1.0,0.0) [0.0|255.0] "Unitless" Vector__XXX
 SG_ ResrvdSigForECM2_UB : 5|1@0+ (1,0) [0|1] "" Vector__XXX
 SG_ ResrvdSigForECM3 : 31|16@0+ (1.0,0.0) [0.0|65535.0] "Unitless" Vector__XXX
 SG_ ResrvdSigForECM3_UB : 6|1@0+ (1,0) [0|1] "" Vector__XXX
 SG_ ResrvdSigForECM4 : 47|16@0+ (1.0,0.0) [0.0|65535.0] "Unitless" Vector__XXX
 SG_ ResrvdSigForECM4_UB : 7|1@0+ (1,0) [0|1] "" Vector__XXX

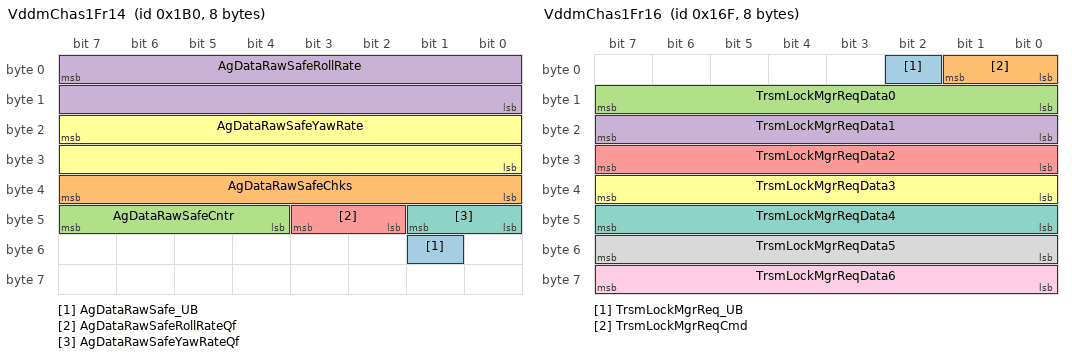
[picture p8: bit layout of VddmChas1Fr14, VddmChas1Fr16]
BO_ 432 VddmChas1Fr14 : 8 VDDM
 SG_ AgDataRawSafe_UB : 49|1@0+ (1,0) [0|1] "" PSCM1
 SG_ AgDataRawSafeChks : 39|8@0+ (1.0,0.0) [0.0|255.0] "Unitless" PSCM1
 SG_ AgDataRawSafeCntr : 47|4@0+ (1.0,0.0) [0.0|15.0] "Unitless" PSCM1
 SG_ AgDataRawSafeRollRate : 7|16@0- (0.000244140625,0.0) [-6.0|6.0] "rad/s" PSCM1
 SG_ AgDataRawSafeRollRateQf : 43|2@0+ (1,0) [0|3] "" PSCM1
 SG_ AgDataRawSafeYawRate : 23|16@0- (0.000244140625,0.0) [-6.0|6.0] "rad/s" PSCM1
 SG_ AgDataRawSafeYawRateQf : 41|2@0+ (1,0) [0|3] "" PSCM1

BO_ 367 VddmChas1Fr16 : 8 VDDM
 SG_ TrsmLockMgrReq_UB : 2|1@0+ (1,0) [0|1] "" Vector__XXX
 SG_ TrsmLockMgrReqCmd : 1|2@0+ (1,0) [0|3] "" Vector__XXX
 SG_ TrsmLockMgrReqData0 : 15|8@0+ (1.0,0.0) [0.0|255.0] "Unitless" Vector__XXX
 SG_ TrsmLockMgrReqData1 : 23|8@0+ (1.0,0.0) [0.0|255.0] "Unitless" Vector__XXX
 SG_ TrsmLockMgrReqData2 : 31|8@0+ (1.0,0.0) [0.0|255.0] "Unitless" Vector__XXX
 SG_ TrsmLockMgrReqData3 : 39|8@0+ (1.0,0.0) [0.0|255.0] "Unitless" Vector__XXX
 SG_ TrsmLockMgrReqData4 : 47|8@0+ (1.0,0.0) [0.0|255.0] "Unitless" Vector__XXX
 SG_ TrsmLockMgrReqData5 : 55|8@0+ (1.0,0.0) [0.0|255.0] "Unitless" Vector__XXX
 SG_ TrsmLockMgrReqData6 : 63|8@0+ (1.0,0.0) [0.0|255.0] "Unitless" Vector__XXX

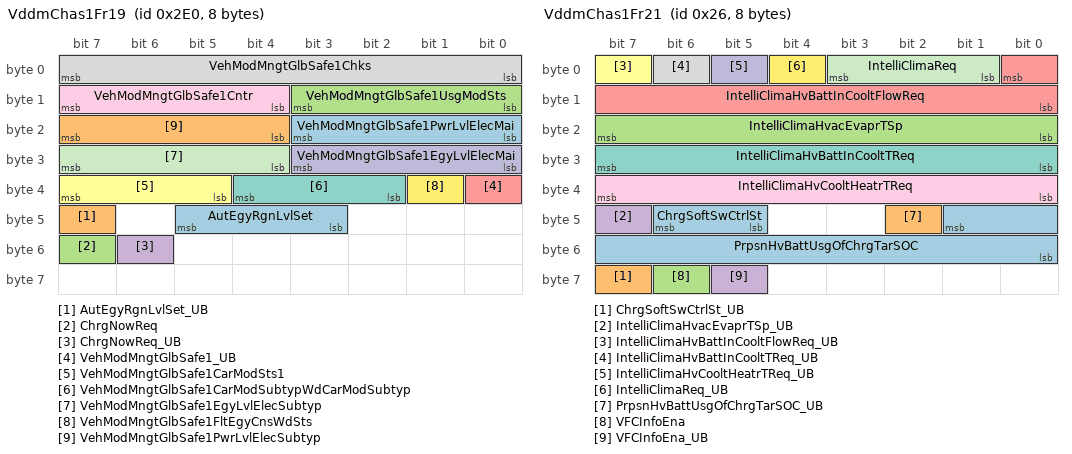
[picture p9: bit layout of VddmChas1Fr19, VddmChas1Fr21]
BO_ 736 VddmChas1Fr19 : 8 VDDM
 SG_ AutEgyRgnLvlSet : 45|3@0+ (1,0) [0|7] "" ECM
 SG_ AutEgyRgnLvlSet_UB : 47|1@0+ (1,0) [0|1] "" ECM
 SG_ ChrgNowReq : 55|1@0+ (1,0) [0|1] "" ECM
 SG_ ChrgNowReq_UB : 54|1@0+ (1,0) [0|1] "" ECM
 SG_ VehModMngtGlbSafe1_UB : 32|1@0+ (1,0) [0|1] "" PSCM1,SAS
 SG_ VehModMngtGlbSafe1CarModSts1 : 39|3@0+ (1,0) [0|7] "" PSCM1,SAS
 SG_ VehModMngtGlbSafe1CarModSubtypWdCarModSubtyp : 36|3@0+ (1.0,0.0) [0.0|7.0] "Unitless" PSCM1,SAS
 SG_ VehModMngtGlbSafe1Chks : 7|8@0+ (1.0,0.0) [0.0|255.0] "Unitless" PSCM1,SAS
 SG_ VehModMngtGlbSafe1Cntr : 15|4@0+ (1.0,0.0) [0.0|15.0] "Unitless" PSCM1,SAS
 SG_ VehModMngtGlbSafe1EgyLvlElecMai : 27|4@0+ (1.0,0.0) [0.0|15.0] "Unitless" PSCM1,SAS
 SG_ VehModMngtGlbSafe1EgyLvlElecSubtyp : 31|4@0+ (1.0,0.0) [0.0|15.0] "Unitless" PSCM1,SAS
 SG_ VehModMngtGlbSafe1FltEgyCnsWdSts : 33|1@0+ (1,0) [0|1] "" PSCM1,SAS
 SG_ VehModMngtGlbSafe1PwrLvlElecMai : 19|4@0+ (1.0,0.0) [0.0|15.0] "Unitless" PSCM1,SAS
 SG_ VehModMngtGlbSafe1PwrLvlElecSubtyp : 23|4@0+ (1.0,0.0) [0.0|15.0] "Unitless" PSCM1,SAS
 SG_ VehModMngtGlbSafe1UsgModSts : 11|4@0+ (1,0) [0|15] "" PSCM1,SAS

BO_ 38 VddmChas1Fr21 : 8 VDDM
 SG_ ChrgSoftSwCtrlSt : 46|2@0+ (1,0) [0|3] "" ECM
 SG_ ChrgSoftSwCtrlSt_UB : 63|1@0+ (1,0) [0|1] "" ECM
 SG_ IntelliClimaHvacEvaprTSp : 23|8@0+ (0.1,-5.0) [-5.0|20.0] "Unitless" Vector__XXX
 SG_ IntelliClimaHvacEvaprTSp_UB : 47|1@0+ (1,0) [0|1] "" Vector__XXX
 SG_ IntelliClimaHvBattInCooltFlowReq : 0|9@0+ (0.1,0.0) [0.0|51.1] "L / min" Vector__XXX
 SG_ IntelliClimaHvBattInCooltFlowReq_UB : 7|1@0+ (1,0) [0|1] "" Vector__XXX
 SG_ IntelliClimaHvBattInCooltTReq : 31|8@0+ (1.0,-50.0) [-50.0|200.0] "degC" Vector__XXX
 SG_ IntelliClimaHvBattInCooltTReq_UB : 6|1@0+ (1,0) [0|1] "" Vector__XXX
 SG_ IntelliClimaHvCooltHeatrTReq : 39|8@0+ (1.0,-40.0) [-40.0|215.0] "degC" Vector__XXX
 SG_ IntelliClimaHvCooltHeatrTReq_UB : 5|1@0+ (1,0) [0|1] "" Vector__XXX
 SG_ IntelliClimaReq : 3|3@0+ (1,0) [0|7] "" Vector__XXX
 SG_ IntelliClimaReq_UB : 4|1@0+ (1,0) [0|1] "" Vector__XXX
 SG_ PrpsnHvBattUsgOfChrgTarSOC : 41|10@0+ (0.1,0.0) [0.0|100.0] "%" ECM
 SG_ PrpsnHvBattUsgOfChrgTarSOC_UB : 42|1@0+ (1,0) [0|1] "" ECM
 SG_ VFCInfoEna : 62|1@0+ (1,0) [0|1] "" ECM,TCM
 SG_ VFCInfoEna_UB : 61|1@0+ (1,0) [0|1] "" ECM,TCM

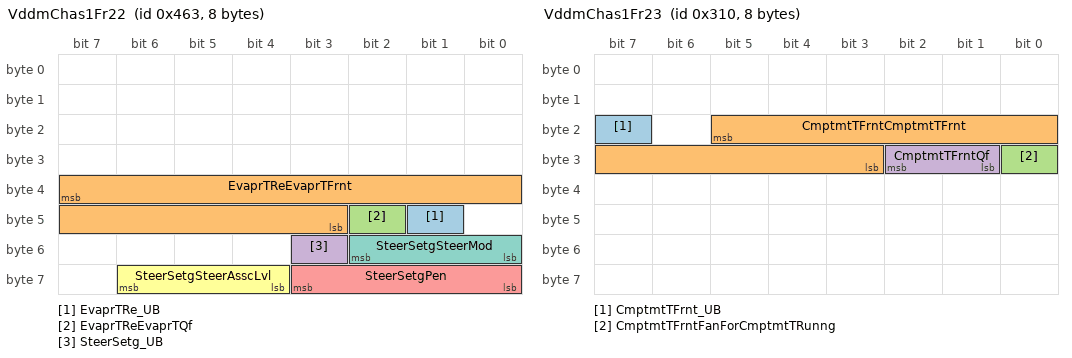
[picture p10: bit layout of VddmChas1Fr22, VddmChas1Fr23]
BO_ 1123 VddmChas1Fr22 : 8 VDDM
 SG_ EvaprTRe_UB : 41|1@0+ (1,0) [0|1] "" ECM
 SG_ EvaprTReEvaprTFrnt : 39|13@0- (0.1,0.0) [-256.0|255.9] "degC" ECM
 SG_ EvaprTReEvaprTQf : 42|1@0+ (1,0) [0|1] "" ECM
 SG_ SteerSetg_UB : 51|1@0+ (1,0) [0|1] "" PSCM1
 SG_ SteerSetgPen : 59|4@0+ (1,0) [0|15] "" PSCM1
 SG_ SteerSetgSteerAsscLvl : 62|3@0+ (1,0) [0|7] "" PSCM1
 SG_ SteerSetgSteerMod : 50|3@0+ (1,0) [0|7] "" PSCM1

BO_ 784 VddmChas1Fr23 : 8 VDDM
 SG_ CmptmtTFrnt_UB : 23|1@0+ (1,0) [0|1] "" SAS
 SG_ CmptmtTFrntCmptmtTFrnt : 21|11@0+ (0.1,-60.0) [-60.0|125.0] "degC" SAS
 SG_ CmptmtTFrntFanForCmptmtTRunng : 24|1@0+ (1,0) [0|1] "" SAS
 SG_ CmptmtTFrntQf : 26|2@0+ (1,0) [0|3] "" SAS

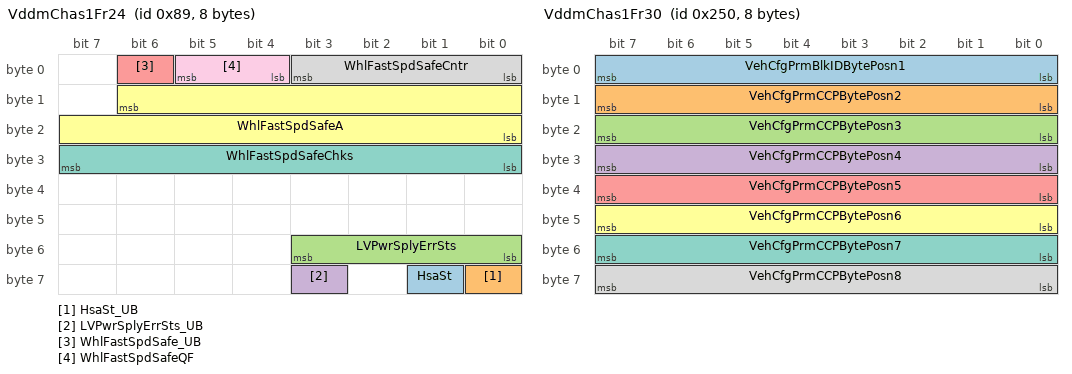
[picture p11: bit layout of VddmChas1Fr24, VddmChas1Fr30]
BO_ 137 VddmChas1Fr24 : 8 BBM
 SG_ HsaSt : 57|1@0+ (1,0) [0|1] "" TCM
 SG_ HsaSt_UB : 56|1@0+ (1,0) [0|1] "" TCM
 SG_ LVPwrSplyErrSts : 51|4@0+ (1,0) [0|15] "" ECM
 SG_ LVPwrSplyErrSts_UB : 59|1@0+ (1,0) [0|1] "" ECM
 SG_ WhlFastSpdSafe_UB : 6|1@0+ (1,0) [0|1] "" PSCM1
 SG_ WhlFastSpdSafeA : 14|15@0+ (0.00391,0.0) [0.0|125.0027] "m/s" PSCM1
 SG_ WhlFastSpdSafeChks : 31|8@0+ (1.0,0.0) [0.0|255.0] "Unitless" PSCM1
 SG_ WhlFastSpdSafeCntr : 3|4@0+ (1.0,0.0) [0.0|15.0] "Unitless" PSCM1
 SG_ WhlFastSpdSafeQF : 5|2@0+ (1,0) [0|3] "" PSCM1

BO_ 592 VddmChas1Fr30 : 8 VDDM
 SG_ VehCfgPrmBlkIDBytePosn1 : 7|8@0+ (1.0,0.0) [0.0|255.0] "Unitless" PSCM1,SAS
 SG_ VehCfgPrmCCPBytePosn2 : 15|8@0+ (1.0,0.0) [0.0|255.0] "Unitless" PSCM1,SAS
 SG_ VehCfgPrmCCPBytePosn3 : 23|8@0+ (1.0,0.0) [0.0|255.0] "Unitless" PSCM1,SAS
 SG_ VehCfgPrmCCPBytePosn4 : 31|8@0+ (1.0,0.0) [0.0|255.0] "Unitless" PSCM1,SAS
 SG_ VehCfgPrmCCPBytePosn5 : 39|8@0+ (1.0,0.0) [0.0|255.0] "Unitless" PSCM1,SAS
 SG_ VehCfgPrmCCPBytePosn6 : 47|8@0+ (1.0,0.0) [0.0|255.0] "Unitless" PSCM1,SAS
 SG_ VehCfgPrmCCPBytePosn7 : 55|8@0+ (1.0,0.0) [0.0|255.0] "Unitless" PSCM1,SAS
 SG_ VehCfgPrmCCPBytePosn8 : 63|8@0+ (1.0,0.0) [0.0|255.0] "Unitless" PSCM1,SAS

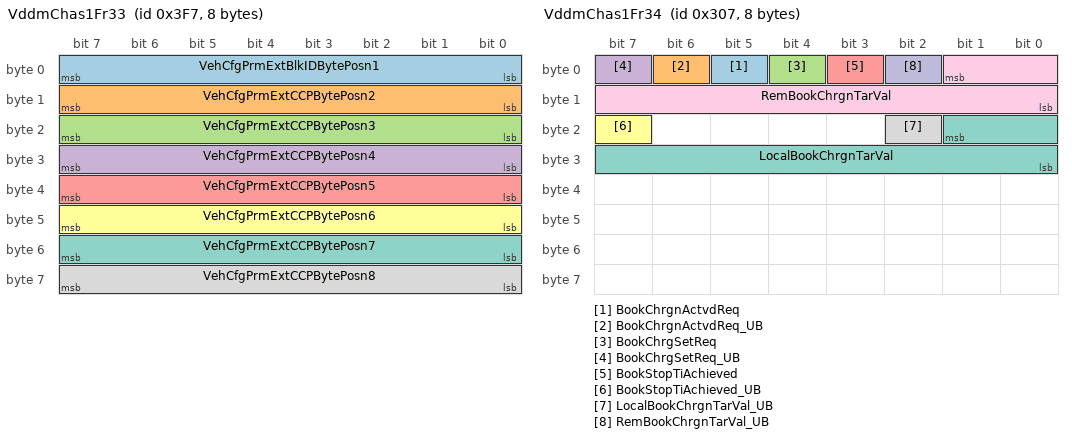
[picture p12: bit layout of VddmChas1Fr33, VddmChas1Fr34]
BO_ 1015 VddmChas1Fr33 : 8 VDDM
 SG_ VehCfgPrmExtBlkIDBytePosn1 : 7|8@0+ (1.0,0.0) [0.0|255.0] "Unitless" ECM,PSCM1
 SG_ VehCfgPrmExtCCPBytePosn2 : 15|8@0+ (1.0,0.0) [0.0|255.0] "Unitless" ECM,PSCM1
 SG_ VehCfgPrmExtCCPBytePosn3 : 23|8@0+ (1.0,0.0) [0.0|255.0] "Unitless" ECM,PSCM1
 SG_ VehCfgPrmExtCCPBytePosn4 : 31|8@0+ (1.0,0.0) [0.0|255.0] "Unitless" ECM,PSCM1
 SG_ VehCfgPrmExtCCPBytePosn5 : 39|8@0+ (1.0,0.0) [0.0|255.0] "Unitless" ECM,PSCM1
 SG_ VehCfgPrmExtCCPBytePosn6 : 47|8@0+ (1.0,0.0) [0.0|255.0] "Unitless" ECM,PSCM1
 SG_ VehCfgPrmExtCCPBytePosn7 : 55|8@0+ (1.0,0.0) [0.0|255.0] "Unitless" ECM,PSCM1
 SG_ VehCfgPrmExtCCPBytePosn8 : 63|8@0+ (1.0,0.0) [0.0|255.0] "Unitless" ECM,PSCM1

BO_ 775 VddmChas1Fr34 : 8 VDDM
 SG_ BookChrgnActvdReq : 5|1@0+ (1,0) [0|1] "" ECM
 SG_ BookChrgnActvdReq_UB : 6|1@0+ (1,0) [0|1] "" ECM
 SG_ BookChrgSetReq : 4|1@0+ (1,0) [0|1] "" ECM
 SG_ BookChrgSetReq_UB : 7|1@0+ (1,0) [0|1] "" ECM
 SG_ BookStopTiAchieved : 3|1@0+ (1,0) [0|1] "" ECM
 SG_ BookStopTiAchieved_UB : 23|1@0+ (1,0) [0|1] "" ECM
 SG_ LocalBookChrgnTarVal : 17|10@0+ (0.1,0.0) [0.0|100.0] "%" ECM
 SG_ LocalBookChrgnTarVal_UB : 18|1@0+ (1,0) [0|1] "" ECM
 SG_ RemBookChrgnTarVal : 1|10@0+ (0.1,0.0) [0.0|100.0] "%" ECM
 SG_ RemBookChrgnTarVal_UB : 2|1@0+ (1,0) [0|1] "" ECM

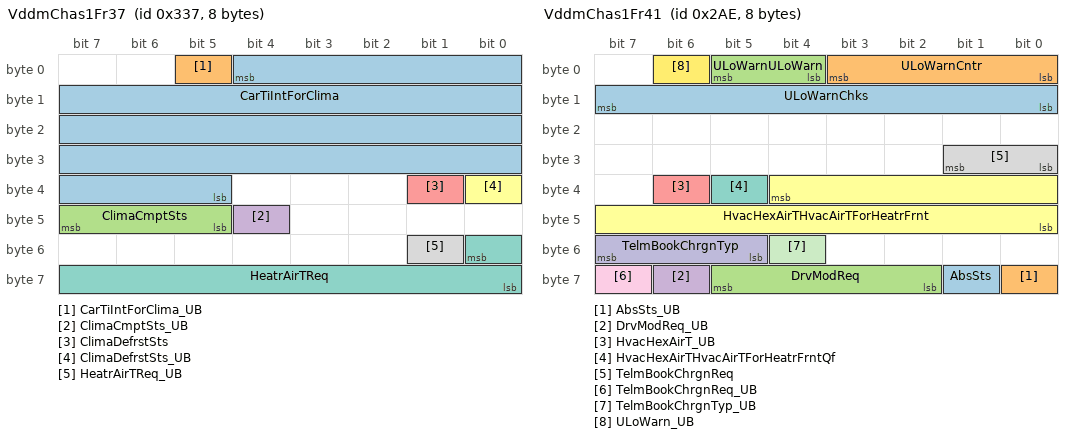
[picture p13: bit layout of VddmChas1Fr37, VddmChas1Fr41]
BO_ 823 VddmChas1Fr37 : 8 VDDM
 SG_ CarTiIntForClima : 4|32@0+ (0.1,0.0) [0.0|429496729.5] "s" ECM
 SG_ CarTiIntForClima_UB : 5|1@0+ (1,0) [0|1] "" ECM
 SG_ ClimaCmptSts : 47|3@0+ (1,0) [0|7] "" ECM
 SG_ ClimaCmptSts_UB : 44|1@0+ (1,0) [0|1] "" ECM
 SG_ ClimaDefrstSts : 33|1@0+ (1,0) [0|1] "" ECM
 SG_ ClimaDefrstSts_UB : 32|1@0+ (1,0) [0|1] "" ECM
 SG_ HeatrAirTReq : 48|9@0+ (0.5,-60.0) [-60.0|195.5] "Unitless" ECM
 SG_ HeatrAirTReq_UB : 49|1@0+ (1,0) [0|1] "" ECM

BO_ 686 VddmChas1Fr41 : 8 BBM
 SG_ AbsSts : 57|1@0+ (1,0) [0|1] "" TCM
 SG_ AbsSts_UB : 56|1@0+ (1,0) [0|1] "" TCM
 SG_ DrvModReq : 61|4@0+ (1,0) [0|15] "" PSCM1
 SG_ DrvModReq_UB : 62|1@0+ (1,0) [0|1] "" PSCM1
 SG_ HvacHexAirT_UB : 38|1@0+ (1,0) [0|1] "" ECM
 SG_ HvacHexAirTHvacAirTForHeatrFrnt : 36|13@0- (0.1,0.0) [-256.0|255.9] "degC" ECM
 SG_ HvacHexAirTHvacAirTForHeatrFrntQf : 37|1@0+ (1,0) [0|1] "" ECM
 SG_ TelmBookChrgnReq : 25|2@0+ (1,0) [0|3] "" ECM
 SG_ TelmBookChrgnReq_UB : 63|1@0+ (1,0) [0|1] "" ECM
 SG_ TelmBookChrgnTyp : 55|3@0+ (1,0) [0|7] "" ECM
 SG_ TelmBookChrgnTyp_UB : 52|1@0+ (1,0) [0|1] "" ECM
 SG_ ULoWarn_UB : 6|1@0+ (1,0) [0|1] "" PSCM1
 SG_ ULoWarnChks : 15|8@0+ (1.0,0.0) [0.0|255.0] "Unitless" PSCM1
 SG_ ULoWarnCntr : 3|4@0+ (1.0,0.0) [0.0|15.0] "Unitless" PSCM1
 SG_ ULoWarnULoWarn : 5|2@0+ (1,0) [0|3] "" PSCM1

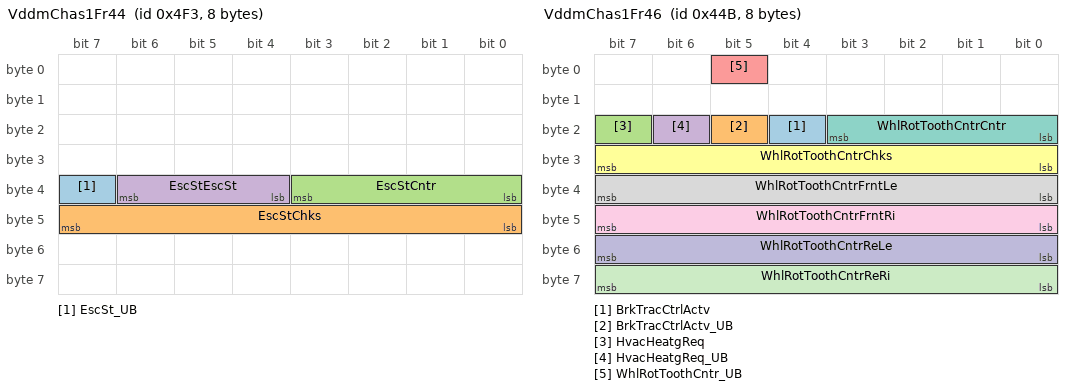
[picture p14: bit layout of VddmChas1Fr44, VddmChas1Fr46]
BO_ 1267 VddmChas1Fr44 : 8 BBM
 SG_ EscSt_UB : 39|1@0+ (1,0) [0|1] "" PSCM1,TCM
 SG_ EscStChks : 47|8@0+ (1.0,0.0) [0.0|255.0] "Unitless" PSCM1,TCM
 SG_ EscStCntr : 35|4@0+ (1.0,0.0) [0.0|15.0] "Unitless" PSCM1,TCM
 SG_ EscStEscSt : 38|3@0+ (1,0) [0|7] "" PSCM1,TCM

BO_ 1099 VddmChas1Fr46 : 8 BBM
 SG_ BrkTracCtrlActv : 20|1@0+ (1,0) [0|1] "" PSCM1
 SG_ BrkTracCtrlActv_UB : 21|1@0+ (1,0) [0|1] "" PSCM1
 SG_ HvacHeatgReq : 23|1@0+ (1,0) [0|1] "" ECM
 SG_ HvacHeatgReq_UB : 22|1@0+ (1,0) [0|1] "" ECM
 SG_ WhlRotToothCntr_UB : 5|1@0+ (1,0) [0|1] "" PSCM1
 SG_ WhlRotToothCntrChks : 31|8@0+ (1.0,0.0) [0.0|255.0] "Unitless" PSCM1
 SG_ WhlRotToothCntrCntr : 19|4@0+ (1.0,0.0) [0.0|15.0] "Unitless" PSCM1
 SG_ WhlRotToothCntrFrntLe : 39|8@0+ (1.0,0.0) [0.0|255.0] "Unitless" PSCM1
 SG_ WhlRotToothCntrFrntRi : 47|8@0+ (1.0,0.0) [0.0|255.0] "Unitless" PSCM1
 SG_ WhlRotToothCntrReLe : 55|8@0+ (1.0,0.0) [0.0|255.0] "Unitless" PSCM1
 SG_ WhlRotToothCntrReRi : 63|8@0+ (1.0,0.0) [0.0|255.0] "Unitless" PSCM1

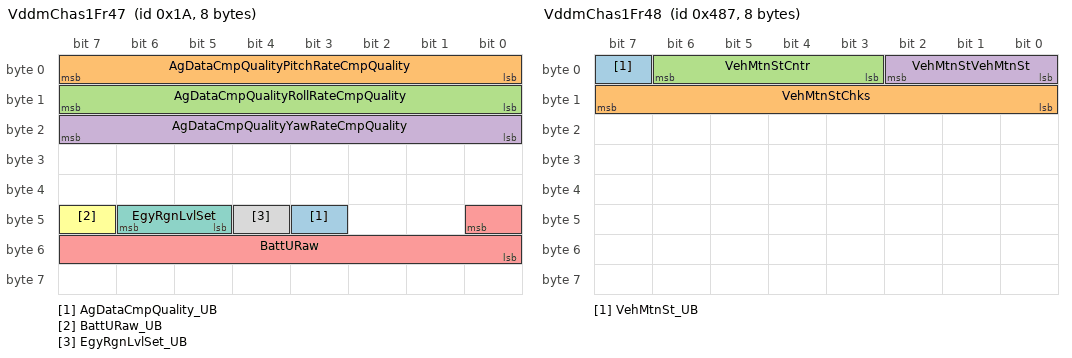
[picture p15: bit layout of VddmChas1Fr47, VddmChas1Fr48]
BO_ 26 VddmChas1Fr47 : 8 VDDM
 SG_ AgDataCmpQuality_UB : 43|1@0+ (1,0) [0|1] "" PSCM1
 SG_ AgDataCmpQualityPitchRateCmpQuality : 7|8@0+ (1.0,0.0) [0.0|255.0] "Unitless" PSCM1
 SG_ AgDataCmpQualityRollRateCmpQuality : 15|8@0+ (1.0,0.0) [0.0|255.0] "Unitless" PSCM1
 SG_ AgDataCmpQualityYawRateCmpQuality : 23|8@0+ (1.0,0.0) [0.0|255.0] "Unitless" PSCM1
 SG_ BattURaw : 40|9@0+ (0.025,5.0) [5.0|17.775] "Volt" ECM
 SG_ BattURaw_UB : 47|1@0+ (1,0) [0|1] "" ECM
 SG_ EgyRgnLvlSet : 46|2@0+ (1,0) [0|3] "" ECM
 SG_ EgyRgnLvlSet_UB : 44|1@0+ (1,0) [0|1] "" ECM

BO_ 1159 VddmChas1Fr48 : 8 BBM
 SG_ VehMtnSt_UB : 7|1@0+ (1,0) [0|1] "" PSCM1
 SG_ VehMtnStChks : 15|8@0+ (1.0,0.0) [0.0|255.0] "Unitless" PSCM1
 SG_ VehMtnStCntr : 6|4@0+ (1.0,0.0) [0.0|15.0] "Unitless" PSCM1
 SG_ VehMtnStVehMtnSt : 2|3@0+ (1,0) [0|7] "" PSCM1

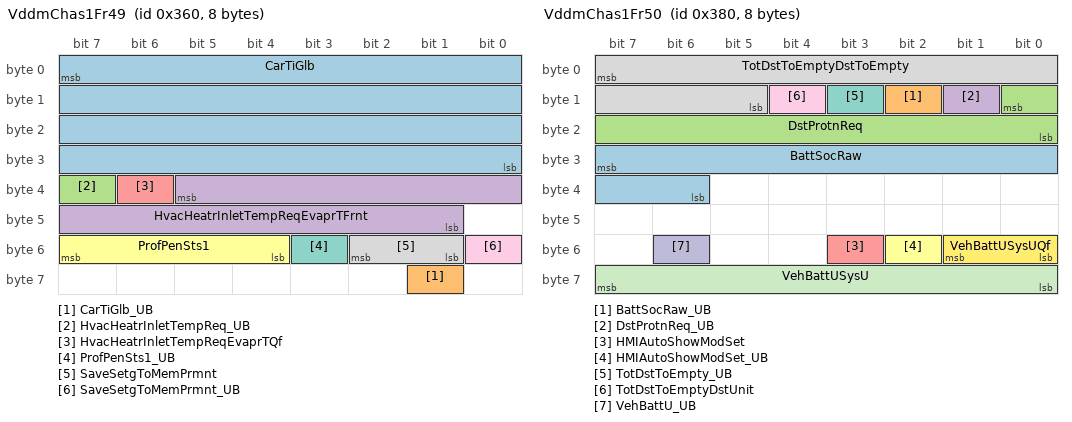
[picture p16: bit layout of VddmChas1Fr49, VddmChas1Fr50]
BO_ 864 VddmChas1Fr49 : 8 VDDM
 SG_ CarTiGlb : 7|32@0+ (0.1,0.0) [0.0|429496729.5] "s" PSCM1,SAS
 SG_ CarTiGlb_UB : 57|1@0+ (1,0) [0|1] "" PSCM1,SAS
 SG_ HvacHeatrInletTempReq_UB : 39|1@0+ (1,0) [0|1] "" ECM
 SG_ HvacHeatrInletTempReqEvaprTFrnt : 37|13@0- (0.1,0.0) [-256.0|255.9] "degC" ECM
 SG_ HvacHeatrInletTempReqEvaprTQf : 38|1@0+ (1,0) [0|1] "" ECM
 SG_ ProfPenSts1 : 55|4@0+ (1,0) [0|15] "" PSCM1
 SG_ ProfPenSts1_UB : 51|1@0+ (1,0) [0|1] "" PSCM1
 SG_ SaveSetgToMemPrmnt : 50|2@0+ (1,0) [0|3] "" PSCM1
 SG_ SaveSetgToMemPrmnt_UB : 48|1@0+ (1,0) [0|1] "" PSCM1

BO_ 896 VddmChas1Fr50 : 8 VDDM
 SG_ BattSocRaw : 31|10@0+ (0.1,0.0) [0.0|100.0] "%" Vector__XXX
 SG_ BattSocRaw_UB : 10|1@0+ (1,0) [0|1] "" Vector__XXX
 SG_ DstProtnReq : 8|9@0+ (1.0,0.0) [0.0|511.0] "Unitless" ECM
 SG_ DstProtnReq_UB : 9|1@0+ (1,0) [0|1] "" ECM
 SG_ HMIAutoShowModSet : 51|1@0+ (1,0) [0|1] "" ECM
 SG_ HMIAutoShowModSet_UB : 50|1@0+ (1,0) [0|1] "" ECM
 SG_ TotDstToEmpty_UB : 11|1@0+ (1,0) [0|1] "" ECM
 SG_ TotDstToEmptyDstToEmpty : 7|11@0+ (1.0,0.0) [0.0|2000.0] "Unitless" ECM
 SG_ TotDstToEmptyDstUnit : 12|1@0+ (1,0) [0|1] "" ECM
 SG_ VehBattU_UB : 54|1@0+ (1,0) [0|1] "" PSCM1,SAS
 SG_ VehBattUSysU : 63|8@0+ (0.1,0.0) [0.0|25.0] "Volt" PSCM1,SAS
 SG_ VehBattUSysUQf : 49|2@0+ (1,0) [0|3] "" PSCM1,SAS

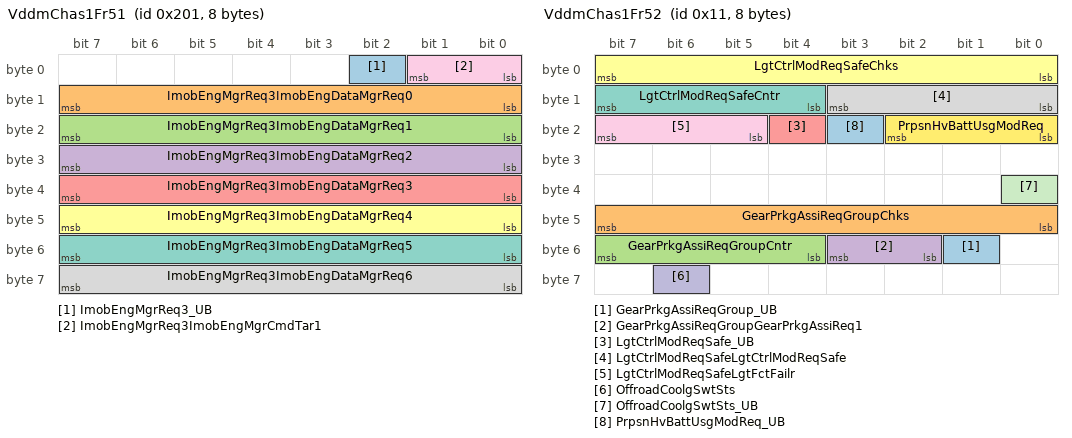
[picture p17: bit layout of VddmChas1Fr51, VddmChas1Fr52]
BO_ 513 VddmChas1Fr51 : 8 VDDM
 SG_ ImobEngMgrReq3_UB : 2|1@0+ (1,0) [0|1] "" TCM
 SG_ ImobEngMgrReq3ImobEngDataMgrReq0 : 15|8@0+ (1.0,0.0) [0.0|255.0] "Unitless" TCM
 SG_ ImobEngMgrReq3ImobEngDataMgrReq1 : 23|8@0+ (1.0,0.0) [0.0|255.0] "Unitless" TCM
 SG_ ImobEngMgrReq3ImobEngDataMgrReq2 : 31|8@0+ (1.0,0.0) [0.0|255.0] "Unitless" TCM
 SG_ ImobEngMgrReq3ImobEngDataMgrReq3 : 39|8@0+ (1.0,0.0) [0.0|255.0] "Unitless" TCM
 SG_ ImobEngMgrReq3ImobEngDataMgrReq4 : 47|8@0+ (1.0,0.0) [0.0|255.0] "Unitless" TCM
 SG_ ImobEngMgrReq3ImobEngDataMgrReq5 : 55|8@0+ (1.0,0.0) [0.0|255.0] "Unitless" TCM
 SG_ ImobEngMgrReq3ImobEngDataMgrReq6 : 63|8@0+ (1.0,0.0) [0.0|255.0] "Unitless" TCM
 SG_ ImobEngMgrReq3ImobEngMgrCmdTar1 : 1|2@0+ (1,0) [0|3] "" TCM

BO_ 17 VddmChas1Fr52 : 8 VDDM
 SG_ GearPrkgAssiReqGroup_UB : 49|1@0+ (1,0) [0|1] "" ECM
 SG_ GearPrkgAssiReqGroupChks : 47|8@0+ (1.0,0.0) [0.0|255.0] "Unitless" ECM
 SG_ GearPrkgAssiReqGroupCntr : 55|4@0+ (1.0,0.0) [0.0|15.0] "Unitless" ECM
 SG_ GearPrkgAssiReqGroupGearPrkgAssiReq1 : 51|2@0+ (1,0) [0|3] "" ECM
 SG_ LgtCtrlModReqSafe_UB : 20|1@0+ (1,0) [0|1] "" ECM
 SG_ LgtCtrlModReqSafeChks : 7|8@0+ (1.0,0.0) [0.0|255.0] "Unitless" ECM
 SG_ LgtCtrlModReqSafeCntr : 15|4@0+ (1.0,0.0) [0.0|15.0] "Unitless" ECM
 SG_ LgtCtrlModReqSafeLgtCtrlModReqSafe : 11|4@0+ (1,0) [0|15] "" ECM
 SG_ LgtCtrlModReqSafeLgtFctFailr : 23|3@0+ (1,0) [0|7] "" ECM
 SG_ OffroadCoolgSwtSts : 62|1@0+ (1,0) [0|1] "" Vector__XXX
 SG_ OffroadCoolgSwtSts_UB : 32|1@0+ (1,0) [0|1] "" Vector__XXX
 SG_ PrpsnHvBattUsgModReq : 18|3@0+ (1,0) [0|7] "" ECM
 SG_ PrpsnHvBattUsgModReq_UB : 19|1@0+ (1,0) [0|1] "" ECM

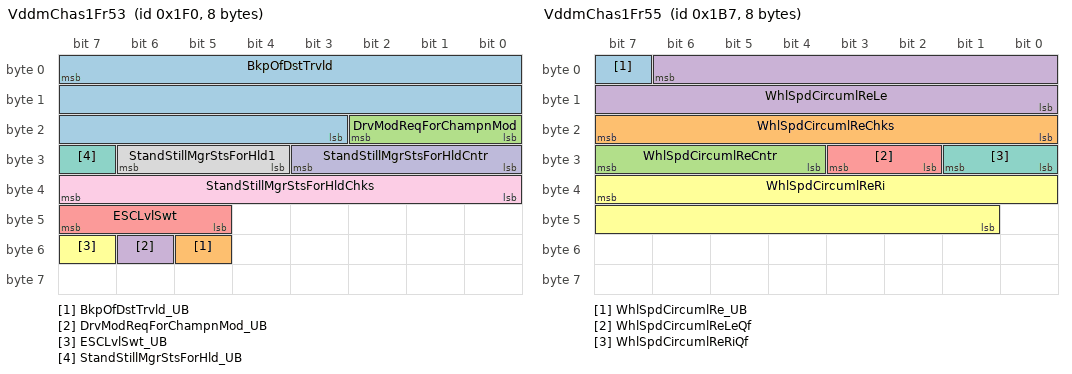
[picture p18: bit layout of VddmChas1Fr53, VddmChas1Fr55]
BO_ 496 VddmChas1Fr53 : 8 VDDM
 SG_ BkpOfDstTrvld : 7|21@0+ (1.0,0.0) [0.0|2000000.0] "km" PSCM1,SAS
 SG_ BkpOfDstTrvld_UB : 53|1@0+ (1,0) [0|1] "" PSCM1,SAS
 SG_ DrvModReqForChampnMod : 18|3@0+ (1,0) [0|7] "" PSCM1
 SG_ DrvModReqForChampnMod_UB : 54|1@0+ (1,0) [0|1] "" PSCM1
 SG_ ESCLvlSwt : 47|3@0+ (1,0) [0|7] "" Vector__XXX
 SG_ ESCLvlSwt_UB : 55|1@0+ (1,0) [0|1] "" Vector__XXX
 SG_ StandStillMgrStsForHld_UB : 31|1@0+ (1,0) [0|1] "" ECM
 SG_ StandStillMgrStsForHld1 : 30|3@0+ (1,0) [0|7] "" ECM
 SG_ StandStillMgrStsForHldChks : 39|8@0+ (1.0,0.0) [0.0|255.0] "Unitless" ECM
 SG_ StandStillMgrStsForHldCntr : 27|4@0+ (1.0,0.0) [0.0|15.0] "Unitless" ECM

BO_ 580 VddmChas1Fr54 : 8 VDDM
 SG_ IDcDcActLoSide_UB : 4|1@0+ (1,0) [0|1] "" PSCM1
 SG_ IDcDcActLoSideChks : 15|8@0+ (1.0,0.0) [0.0|255.0] "Unitless" PSCM1
 SG_ IDcDcActLoSideCntr : 3|4@0+ (1.0,0.0) [0.0|15.0] "Unitless" PSCM1
 SG_ IDcDcActLoSideIDcDcActLoSide : 23|12@0+ (0.1,0.0) [0.0|409.5] "A" PSCM1

BO_ 439 VddmChas1Fr55 : 8 BBM
 SG_ WhlSpdCircumlRe_UB : 7|1@0+ (1,0) [0|1] "" ECM,PSCM1
 SG_ WhlSpdCircumlReChks : 23|8@0+ (1.0,0.0) [0.0|255.0] "Unitless" ECM,PSCM1
 SG_ WhlSpdCircumlReCntr : 31|4@0+ (1.0,0.0) [0.0|15.0] "Unitless" ECM,PSCM1
 SG_ WhlSpdCircumlReLe : 6|15@0+ (0.00391,0.0) [0.0|125.0027] "m/s" ECM,PSCM1
 SG_ WhlSpdCircumlReLeQf : 27|2@0+ (1,0) [0|3] "" ECM,PSCM1
 SG_ WhlSpdCircumlReRi : 39|15@0+ (0.00391,0.0) [0.0|125.0027] "m/s" ECM,PSCM1
 SG_ WhlSpdCircumlReRiQf : 25|2@0+ (1,0) [0|3] "" ECM,PSCM1

BO_ 52 VddmChas1Fr56 : 8 VDDM
 SG_ CrashStsSafe_UB : 5|1@0+ (1,0) [0|1] "" Vector__XXX
 SG_ CrashStsSafeChks : 15|8@0+ (1.0,0.0) [0.0|255.0] "Unitless" Vector__XXX
 SG_ CrashStsSafeCntr : 3|4@0+ (1.0,0.0) [0.0|15.0] "Unitless" Vector__XXX
 SG_ CrashStsSafeSts : 4|1@0+ (1,0) [0|1] "" Vector__XXX

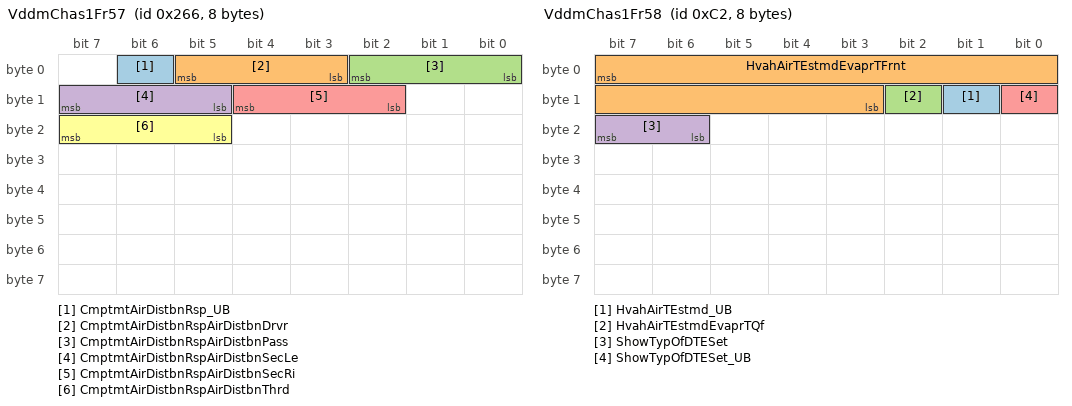
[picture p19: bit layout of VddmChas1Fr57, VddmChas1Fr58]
BO_ 614 VddmChas1Fr57 : 8 VDDM
 SG_ CmptmtAirDistbnRsp_UB : 6|1@0+ (1,0) [0|1] "" Vector__XXX
 SG_ CmptmtAirDistbnRspAirDistbnDrvr : 5|3@0+ (1,0) [0|7] "" Vector__XXX
 SG_ CmptmtAirDistbnRspAirDistbnPass : 2|3@0+ (1,0) [0|7] "" Vector__XXX
 SG_ CmptmtAirDistbnRspAirDistbnSecLe : 15|3@0+ (1,0) [0|7] "" Vector__XXX
 SG_ CmptmtAirDistbnRspAirDistbnSecRi : 12|3@0+ (1,0) [0|7] "" Vector__XXX
 SG_ CmptmtAirDistbnRspAirDistbnThrd : 23|3@0+ (1,0) [0|7] "" Vector__XXX

BO_ 194 VddmChas1Fr58 : 8 VDDM
 SG_ HvahAirTEstmd_UB : 9|1@0+ (1,0) [0|1] "" Vector__XXX
 SG_ HvahAirTEstmdEvaprTFrnt : 7|13@0- (0.1,0.0) [-256.0|255.9] "degC" Vector__XXX
 SG_ HvahAirTEstmdEvaprTQf : 10|1@0+ (1,0) [0|1] "" Vector__XXX
 SG_ ShowTypOfDTESet : 23|2@0+ (1,0) [0|3] "" ECM
 SG_ ShowTypOfDTESet_UB : 8|1@0+ (1,0) [0|1] "" ECM

BO_ 1313 VddmChas1NMFr : 8 VDDM
 SG_ PNC16_VDDM : 16|1@0+ (1,0) [0|0] "" TCM
 SG_ PNC17_VDDM : 17|1@0+ (1,0) [0|0] "" TCM
 SG_ PNC18_VDDM : 18|1@0+ (1,0) [0|0] "" TCM
 SG_ PNC19_VDDM : 19|1@0+ (1,0) [0|0] "" TCM
 SG_ PNC20_VDDM : 20|1@0+ (1,0) [0|0] "" TCM
 SG_ PNC21_VDDM : 21|1@0+ (1,0) [0|0] "" TCM
 SG_ PNC22_VDDM : 22|1@0+ (1,0) [0|0] "" TCM
 SG_ PNC23_VDDM : 23|1@0+ (1,0) [0|0] "" TCM
 SG_ PNC24_VDDM : 24|1@0+ (1,0) [0|0] "" TCM
 SG_ PNC25_VDDM : 25|1@0+ (1,0) [0|0] "" TCM
 SG_ PNC26_VDDM : 26|1@0+ (1,0) [0|0] "" TCM
 SG_ PNC27_VDDM : 27|1@0+ (1,0) [0|0] "" TCM
 SG_ PNC28_VDDM : 28|1@0+ (1,0) [0|0] "" TCM
 SG_ PNC29_VDDM : 29|1@0+ (1,0) [0|0] "" TCM
 SG_ PNC30_VDDM : 30|1@0+ (1,0) [0|0] "" TCM
 SG_ PNC31_VDDM : 31|1@0+ (1,0) [0|0] "" TCM
 SG_ PNC32_VDDM : 32|1@0+ (1,0) [0|0] "" TCM
 SG_ PNC33_VDDM : 33|1@0+ (1,0) [0|0] "" TCM
 SG_ PNC34_VDDM : 34|1@0+ (1,0) [0|0] "" TCM
 SG_ PNC35_VDDM : 35|1@0+ (1,0) [0|0] "" TCM
 SG_ PNC36_VDDM : 36|1@0+ (1,0) [0|0] "" TCM
 SG_ PNC37_VDDM : 37|1@0+ (1,0) [0|0] "" TCM
 SG_ PNC38_VDDM : 38|1@0+ (1,0) [0|0] "" TCM
 SG_ PNC39_VDDM : 39|1@0+ (1,0) [0|0] "" TCM
 SG_ PNC40_VDDM : 40|1@0+ (1,0) [0|0] "" TCM
 SG_ PNC41_VDDM : 41|1@0+ (1,0) [0|0] "" TCM
 SG_ PNC42_VDDM : 42|1@0+ (1,0) [0|0] "" TCM
 SG_ NM_PNI_VDDM : 14|1@0+ (1,0) [0|0] "" TCM
 SG_ NM_AW_VDDM : 12|1@0+ (1,0) [0|0] "" TCM
 SG_ NM_CS_VDDM : 11|1@0+ (1,0) [0|0] "" TCM
 SG_ NM_RMR_VDDM : 8|1@0+ (1,0) [0|0] "" TCM
 SG_ NM_NodeID_VDDM : 7|8@0+ (1,0) [0|0] "" TCM

BO_ 2047 VddmToAllFuncChas1DiagReqFrame : 8 VDDM
 SG_ VddmToAllFuncChas1DiagReqNpdu : 7|64@0+ (1,0) [0|0] "" PSCM1, SAS

BO_ 1908 VddmToPscm100FITbChas1DiagReqFrame : 8 VDDM
 SG_ VddmToPscm100FITbChas1DiagReqNpdu : 7|64@0+ (1,0) [0|0] "" Vector__XXX

BO_ 1904 VddmToPscmChas1DiagReqFrame : 8 VDDM
 SG_ VddmToPscmChas1DiagReqNpdu : 7|64@0+ (1,0) [0|0] "" PSCM1

BO_ 1905 VddmToRasmChas1DiagReqFrame : 8 VDDM
 SG_ VddmToRasmChas1DiagReqNpdu : 7|64@0+ (1,0) [0|0] "" Vector__XXX

BO_ 1909 VddmToRbcmChas1DiagReqFrame : 8 VDDM
 SG_ VddmToRbcmChas1DiagReqNpdu : 7|64@0+ (1,0) [0|0] "" Vector__XXX

BO_ 1906 VddmToSasChas1DiagReqFrame : 8 VDDM
 SG_ VddmToSasChas1DiagReqNpdu : 7|64@0+ (1,0) [0|0] "" SAS

BO_ 1911 VddmToShvcChas1DiagReqFrame : 8 VDDM
 SG_ VddmToShvcChas1DiagReqNpdu : 7|64@0+ (1,0) [0|0] "" Vector__XXX

CM_ SG_ 326 TrsmEngNTqMaxChks "TCM uses signal Transmission Engine N Torque Maximum Safe to inform ECM of the maximum allowed torque to reach the desired engine RPM. Signal is secured with a checksum calculation. Checksum";
CM_ SG_ 326 TrsmEngNTqMaxCntr "TCM uses signal Transmission Engine N Torque Maximum Safe to inform ECM of the maximum allowed torque to reach the desired engine RPM. Signal is secured with a checksum calculation. Counter";
CM_ SG_ 326 TrsmEngNTqMaxTrsmEngNTqMax "TCM uses signal Transmission Engine N Torque Maximum Safe to inform ECM of the maximum allowed torque to reach the desired engine RPM. Signal is secured with a checksum calculation. Maximum allowed torque to reach EngN req";
CM_ SG_ 326 TrsmGearNotAvlSts "TCM use signal Trsm Gear Not Available Status to inform ECM which gears is unavailable for gear shifting.Signal is used during failsafe operation Availability mode.Default 0-no gears unavailable.Bit 0-First gear EB not available.Bit 1-First gear not available.Bit X-Xth gear not available";
CM_ SG_ 263 TrsmFltIndcn "TCM uses signal Transmission Fault Indication to request text message ilumination to driver. Signal is transmitted to both ECM and DIM.Signal consits of 32 slots. One slot is one unique text message. Default value is 0 (No request)";
CM_ SG_ 263 TrsmModNotAvlSts3 "TCM uses signal Transmissions Mode Not Available Status to inform ECM which modes are unavailable";
CM_ SG_ 402 BoostIndctnILeft "inductor current left";
CM_ SG_ 402 BoostIndctnIRht "inductor current right";
CM_ SG_ 402 BoostPwrLimMax "maximum boost power (battery discharge)";
CM_ SG_ 402 BoostPwrLimMin "minimum boost power (battery charge)";
CM_ SG_ 756 VFCVectorPCMBlockID "BlockID";
CM_ SG_ 756 VFCVectorPCMVFCid0 "SettingsComfort";
CM_ SG_ 756 VFCVectorPCMVFCid1 "ParkingDrivingClimatization";
CM_ SG_ 756 VFCVectorPCMVFCid10 "ExteriorLighting";
CM_ SG_ 756 VFCVectorPCMVFCid11 "VFCid11";
CM_ SG_ 756 VFCVectorPCMVFCid12 "Alarm";
CM_ SG_ 756 VFCVectorPCMVFCid13 "VFCid13";
CM_ SG_ 756 VFCVectorPCMVFCid14 "InteriorLighting";
CM_ SG_ 756 VFCVectorPCMVFCid15 "VFCid15";
CM_ SG_ 756 VFCVectorPCMVFCid16 "Locking";
CM_ SG_ 756 VFCVectorPCMVFCid17 "RemoteKeyFunctionality";
CM_ SG_ 756 VFCVectorPCMVFCid18 "PropulsionStart";
CM_ SG_ 756 VFCVectorPCMVFCid19 "VFCid19";
CM_ SG_ 756 VFCVectorPCMVFCid2 "PostClimatisation";
CM_ SG_ 756 VFCVectorPCMVFCid20 "VFCid20";
CM_ SG_ 756 VFCVectorPCMVFCid21 "PowerClosures";
CM_ SG_ 756 VFCVectorPCMVFCid22 "VehicleDriving";
CM_ SG_ 756 VFCVectorPCMVFCid23 "VFCid23";
CM_ SG_ 756 VFCVectorPCMVFCid24 "SettingsProfile";
CM_ SG_ 756 VFCVectorPCMVFCid25 "SeatComfortFunctions";
CM_ SG_ 756 VFCVectorPCMVFCid26 "Brake";
CM_ SG_ 756 VFCVectorPCMVFCid27 "InfotainmentPoll";
CM_ SG_ 756 VFCVectorPCMVFCid28 "HVEnergyStorage";
CM_ SG_ 756 VFCVectorPCMVFCid29 "VFCid29";
CM_ SG_ 756 VFCVectorPCMVFCid3 "PowertrainParkingClimatization";
CM_ SG_ 756 VFCVectorPCMVFCid30 "TelematicsConnectivity";
CM_ SG_ 756 VFCVectorPCMVFCid31 "VFCid31";
CM_ SG_ 756 VFCVectorPCMVFCid32 "VFCid32";
CM_ SG_ 756 VFCVectorPCMVFCid33 "Diagnostics";
CM_ SG_ 756 VFCVectorPCMVFCid34 "VehicleModeManagement";
CM_ SG_ 756 VFCVectorPCMVFCid35 "TrailerCaravanFunctions";
CM_ SG_ 756 VFCVectorPCMVFCid36 "Immobilizer";
CM_ SG_ 756 VFCVectorPCMVFCid37 "Windows";
CM_ SG_ 756 VFCVectorPCMVFCid38 "Visibility";
CM_ SG_ 756 VFCVectorPCMVFCid39 "VFCid39";
CM_ SG_ 756 VFCVectorPCMVFCid4 "VFCid4";
CM_ SG_ 756 VFCVectorPCMVFCid40 "VFCid40";
CM_ SG_ 756 VFCVectorPCMVFCid41 "InfotainmentPush";
CM_ SG_ 756 VFCVectorPCMVFCid42 "ChargingHV";
CM_ SG_ 756 VFCVectorPCMVFCid43 "BodyPreClimatisation";
CM_ SG_ 756 VFCVectorPCMVFCid44 "Crash";
CM_ SG_ 756 VFCVectorPCMVFCid45 "GlobalShortDuration";
CM_ SG_ 756 VFCVectorPCMVFCid46 "ExteriorLightsHazard";
CM_ SG_ 756 VFCVectorPCMVFCid47 "VFCid47";
CM_ SG_ 756 VFCVectorPCMVFCid48 "DoorOpenWarning";
CM_ SG_ 756 VFCVectorPCMVFCid49 "ChargingLVInit";
CM_ SG_ 756 VFCVectorPCMVFCid5 "VFCid5";
CM_ SG_ 756 VFCVectorPCMVFCid50 "VFCid50";
CM_ SG_ 756 VFCVectorPCMVFCid51 "VFCid51";
CM_ SG_ 756 VFCVectorPCMVFCid52 "HVBatteryThermalEventWarning";
CM_ SG_ 756 VFCVectorPCMVFCid53 "VisualAssist";
CM_ SG_ 756 VFCVectorPCMVFCid54 "VFCid54";
CM_ SG_ 756 VFCVectorPCMVFCid55 "VFCid55";
CM_ SG_ 756 VFCVectorPCMVFCid56 "VFCid56";
CM_ SG_ 756 VFCVectorPCMVFCid57 "VFCid57";
CM_ SG_ 756 VFCVectorPCMVFCid58 "VFCid58";
CM_ SG_ 756 VFCVectorPCMVFCid59 "VFCid59";
CM_ SG_ 756 VFCVectorPCMVFCid6 "SettingsVehicle";
CM_ SG_ 756 VFCVectorPCMVFCid60 "VFCid60";
CM_ SG_ 756 VFCVectorPCMVFCid61 "VFCid61";
CM_ SG_ 756 VFCVectorPCMVFCid7 "VFCid7";
CM_ SG_ 756 VFCVectorPCMVFCid8 "VFCid8";
CM_ SG_ 756 VFCVectorPCMVFCid9 "IPWakeup";
CM_ SG_ 274 SecParkBrkSysSt2BrkSysSt "second parking brake system status2";
CM_ SG_ 274 SecParkBrkSysSt2Chks "checksum";
CM_ SG_ 274 SecParkBrkSysSt2Cntr "counter";
CM_ SG_ 85 AgDataRaw2SafeChks "IMU pitch rate data. Check sum";
CM_ SG_ 85 AgDataRaw2SafeCntr "IMU pitch rate data. Counter";
CM_ SG_ 85 AgDataRaw2SafePitchRate "IMU pitch rate data. Pitch Rate";
CM_ SG_ 85 AgDataRaw2SafePitchRateQf "IMU pitch rate data. Quality factor for Pitch Rate";
CM_ SG_ 375 HvBattSoc "Actual state of charge of the Hv Battery.";
CM_ SG_ 375 HvSysRlyStsChks "Checksum for E2E";
CM_ SG_ 375 HvSysRlyStsCntr "Counter for E2E";
CM_ SG_ 375 HvSysRlyStsHvSysRlySts "Actual state of the main contactors.";
CM_ SG_ 375 RlyPwrDistbnCmd1WdIgnRlyCmd "Ignition relay status";
CM_ SG_ 342 TiAndDateIndcnDataValid "Current time (Hr, Min and Sec) and date (Year, Months and days) data for indication. See requirement for more information about the signals. Signal qualifier, No means values should be ignored.";
CM_ SG_ 342 TiAndDateIndcnDay "Current time (Hr, Min and Sec) and date (Year, Months and days) data for indication. See requirement for more information about the signals. Day";
CM_ SG_ 342 TiAndDateIndcnHr1 "Current time (Hr, Min and Sec) and date (Year, Months and days) data for indication. See requirement for more information about the signals. Hour";
CM_ SG_ 342 TiAndDateIndcnMins1 "Current time (Hr, Min and Sec) and date (Year, Months and days) data for indication. See requirement for more information about the signals. Minutes";
CM_ SG_ 342 TiAndDateIndcnMth1 "Current time (Hr, Min and Sec) and date (Year, Months and days) data for indication. See requirement for more information about the signals. Month, 1-12";
CM_ SG_ 342 TiAndDateIndcnSec1 "Current time (Hr, Min and Sec) and date (Year, Months and days) data for indication. See requirement for more information about the signals. Seconds";
CM_ SG_ 342 TiAndDateIndcnYr1 "Current time (Hr, Min and Sec) and date (Year, Months and days) data for indication. See requirement for more information about the signals. Year, 0-99";
CM_ SG_ 1365 VFCVectorVCUBlockID "BlockID";
CM_ SG_ 1365 VFCVectorVCUVFCid0 "SettingsComfort";
CM_ SG_ 1365 VFCVectorVCUVFCid1 "ParkingDrivingClimatization";
CM_ SG_ 1365 VFCVectorVCUVFCid10 "ExteriorLighting";
CM_ SG_ 1365 VFCVectorVCUVFCid11 "VFCid11";
CM_ SG_ 1365 VFCVectorVCUVFCid12 "Alarm";
CM_ SG_ 1365 VFCVectorVCUVFCid13 "VFCid13";
CM_ SG_ 1365 VFCVectorVCUVFCid14 "InteriorLighting";
CM_ SG_ 1365 VFCVectorVCUVFCid15 "VFCid15";
CM_ SG_ 1365 VFCVectorVCUVFCid16 "Locking";
CM_ SG_ 1365 VFCVectorVCUVFCid17 "RemoteKeyFunctionality";
CM_ SG_ 1365 VFCVectorVCUVFCid18 "PropulsionStart";
CM_ SG_ 1365 VFCVectorVCUVFCid19 "VFCid19";
CM_ SG_ 1365 VFCVectorVCUVFCid2 "PostClimatisation";
CM_ SG_ 1365 VFCVectorVCUVFCid20 "VFCid20";
CM_ SG_ 1365 VFCVectorVCUVFCid21 "PowerClosures";
CM_ SG_ 1365 VFCVectorVCUVFCid22 "VehicleDriving";
CM_ SG_ 1365 VFCVectorVCUVFCid23 "VFCid23";
CM_ SG_ 1365 VFCVectorVCUVFCid24 "SettingsProfile";
CM_ SG_ 1365 VFCVectorVCUVFCid25 "SeatComfortFunctions";
CM_ SG_ 1365 VFCVectorVCUVFCid26 "Brake";
CM_ SG_ 1365 VFCVectorVCUVFCid27 "InfotainmentPoll";
CM_ SG_ 1365 VFCVectorVCUVFCid28 "HVEnergyStorage";
CM_ SG_ 1365 VFCVectorVCUVFCid29 "VFCid29";
CM_ SG_ 1365 VFCVectorVCUVFCid3 "PowertrainParkingClimatization";
CM_ SG_ 1365 VFCVectorVCUVFCid30 "TelematicsConnectivity";
CM_ SG_ 1365 VFCVectorVCUVFCid31 "VFCid31";
CM_ SG_ 1365 VFCVectorVCUVFCid32 "VFCid32";
CM_ SG_ 1365 VFCVectorVCUVFCid33 "Diagnostics";
CM_ SG_ 1365 VFCVectorVCUVFCid34 "VehicleModeManagement";
CM_ SG_ 1365 VFCVectorVCUVFCid35 "TrailerCaravanFunctions";
CM_ SG_ 1365 VFCVectorVCUVFCid36 "Immobilizer";
CM_ SG_ 1365 VFCVectorVCUVFCid37 "Windows";
CM_ SG_ 1365 VFCVectorVCUVFCid38 "Visibility";
CM_ SG_ 1365 VFCVectorVCUVFCid39 "VFCid39";
CM_ SG_ 1365 VFCVectorVCUVFCid4 "VFCid4";
CM_ SG_ 1365 VFCVectorVCUVFCid40 "VFCid40";
CM_ SG_ 1365 VFCVectorVCUVFCid41 "InfotainmentPush";
CM_ SG_ 1365 VFCVectorVCUVFCid42 "ChargingHV";
CM_ SG_ 1365 VFCVectorVCUVFCid43 "BodyPreClimatisation";
CM_ SG_ 1365 VFCVectorVCUVFCid44 "Crash";
CM_ SG_ 1365 VFCVectorVCUVFCid45 "GlobalShortDuration";
CM_ SG_ 1365 VFCVectorVCUVFCid46 "ExteriorLightsHazard";
CM_ SG_ 1365 VFCVectorVCUVFCid47 "VFCid47";
CM_ SG_ 1365 VFCVectorVCUVFCid48 "DoorOpenWarning";
CM_ SG_ 1365 VFCVectorVCUVFCid49 "ChargingLVInit";
CM_ SG_ 1365 VFCVectorVCUVFCid5 "VFCid5";
CM_ SG_ 1365 VFCVectorVCUVFCid50 "VFCid50";
CM_ SG_ 1365 VFCVectorVCUVFCid51 "VFCid51";
CM_ SG_ 1365 VFCVectorVCUVFCid52 "HVBatteryThermalEventWarning";
CM_ SG_ 1365 VFCVectorVCUVFCid53 "VisualAssist";
CM_ SG_ 1365 VFCVectorVCUVFCid54 "VFCid54";
CM_ SG_ 1365 VFCVectorVCUVFCid55 "VFCid55";
CM_ SG_ 1365 VFCVectorVCUVFCid56 "VFCid56";
CM_ SG_ 1365 VFCVectorVCUVFCid57 "VFCid57";
CM_ SG_ 1365 VFCVectorVCUVFCid58 "VFCid58";
CM_ SG_ 1365 VFCVectorVCUVFCid59 "VFCid59";
CM_ SG_ 1365 VFCVectorVCUVFCid6 "SettingsVehicle";
CM_ SG_ 1365 VFCVectorVCUVFCid60 "VFCid60";
CM_ SG_ 1365 VFCVectorVCUVFCid61 "VFCid61";
CM_ SG_ 1365 VFCVectorVCUVFCid7 "VFCid7";
CM_ SG_ 1365 VFCVectorVCUVFCid8 "VFCid8";
CM_ SG_ 1365 VFCVectorVCUVFCid9 "IPWakeup";
CM_ SG_ 1434 VDDMdevelpsignalgroupresp1Functiondevpsignalgroup1 "develop signal group response";
CM_ SG_ 1434 VDDMdevelpsignalgroupresp1Functiondevpsignalgroup2 "develop signal group response";
CM_ SG_ 1434 VDDMdevelpsignalgroupresp1Functiondevpsignalgroup3 "develop signal group response";
CM_ SG_ 1434 VDDMdevelpsignalgroupresp1Functiondevpsignalgroup4 "develop signal group response";
CM_ SG_ 1434 VDDMdevelpsignalgroupresp1Functiondevpsignalgroup5 "develop signal group response";
CM_ SG_ 1434 VDDMdevelpsignalgroupresp1Functiondevpsignalgroup6 "develop signal group response";
CM_ SG_ 1434 VDDMdevelpsignalgroupresp1Functiondevpsignalgroup7 "develop signal group response";
CM_ SG_ 1434 VDDMdevelpsignalgroupresp1Functiondevpsignalgroup8 "develop signal group response";
CM_ SG_ 1435 VDDMdevelpsignalgroupresp2Functiondevpsignalgroup1 "develop signal group response";
CM_ SG_ 1435 VDDMdevelpsignalgroupresp2Functiondevpsignalgroup2 "develop signal group response";
CM_ SG_ 1435 VDDMdevelpsignalgroupresp2Functiondevpsignalgroup3 "develop signal group response";
CM_ SG_ 1435 VDDMdevelpsignalgroupresp2Functiondevpsignalgroup4 "develop signal group response";
CM_ SG_ 1435 VDDMdevelpsignalgroupresp2Functiondevpsignalgroup5 "develop signal group response";
CM_ SG_ 1435 VDDMdevelpsignalgroupresp2Functiondevpsignalgroup6 "develop signal group response";
CM_ SG_ 1435 VDDMdevelpsignalgroupresp2Functiondevpsignalgroup7 "develop signal group response";
CM_ SG_ 1435 VDDMdevelpsignalgroupresp2Functiondevpsignalgroup8 "develop signal group response";
CM_ SG_ 81 AsyDataWithCmpSafeALat1Qf "IMU processed special data. Quality factor for Lateral acceleration signal";
CM_ SG_ 81 AsyDataWithCmpSafeALatWithCmp "IMU processed special data.  Compensated Lateral acceleration";
CM_ SG_ 81 AsyDataWithCmpSafeALgt1Qf "IMU processed special data. Quality factor for Longitudinal acceleration";
CM_ SG_ 81 AsyDataWithCmpSafeChks "IMU processed special data. Check sum";
CM_ SG_ 81 AsyDataWithCmpSafeCntr "IMU processed special data. Counter";
CM_ SG_ 81 AsyDataWithCmpSafeGrdtOfALgt "IMU processed special data. Derivative of Longitudinal acceleration";
CM_ SG_ 81 AsyDataWithCmpSafeYawRateQf "IMU processed special data. Quality Factor for Yaw Rate";
CM_ SG_ 81 AsyDataWithCmpSafeYawRateWithCmp "IMU processed special data. Compensated Yaw rate";
CM_ SG_ 160 ADataRawSafeALat "IMU acceleration data Lateral acceleration";
CM_ SG_ 160 ADataRawSafeALat1Qf "IMU acceleration data Quality factor for Lateral acceleration signal";
CM_ SG_ 160 ADataRawSafeALgt "IMU acceleration data Longitudinal acceleration";
CM_ SG_ 160 ADataRawSafeALgt1Qf "IMU acceleration data Quality factor for Longitudinal acceleration";
CM_ SG_ 160 ADataRawSafeAVert "IMU acceleration data Vertical acceleration";
CM_ SG_ 160 ADataRawSafeAVertQf "IMU acceleration data Quality factor for Vertical acceleration";
CM_ SG_ 160 ADataRawSafeChks "IMU acceleration data Check sum";
CM_ SG_ 160 ADataRawSafeCntr "IMU acceleration data Counter";
CM_ SG_ 400 AbsCtrlActvChks "checksum";
CM_ SG_ 400 AbsCtrlActvCntr "counter";
CM_ SG_ 400 AbsCtrlActvCtrlSts1 "Anti Blocking Systems (ABS) control is active (at least one wheel)
0 = No wheel is in Anti Blocking Systems (ABS) control
1 = At least one wheel is in Anti Blocking Systems (ABS) control";
CM_ SG_ 400 AmbTRawAmbTVal "Unfiltered ambient temp raw data in deg C. Ambient temp value";
CM_ SG_ 400 AmbTRawQly "Unfiltered ambient temp raw data in deg C. Quality Factor of the ambient temp";
CM_ SG_ 400 LatCtrlReqSafeChks "Requests for lateral control by steering actuator. Checksum";
CM_ SG_ 400 LatCtrlReqSafeCntr "Requests for lateral control by steering actuator. Counter";
CM_ SG_ 400 LatCtrlReqSafeLatCtrlModReq "Request";
CM_ SG_ 400 LatCtrlReqSafeSteerTqReq "Requests for lateral control by steering actuator. Steering wheel torque request.";
CM_ SG_ 400 LatCtrlReqSafeSteerWhlHptcWarnReq "Enable steering wheel haptic warning";
CM_ SG_ 224 CnvnReq "Intelligent charge request";
CM_ SG_ 224 DrvrCrsCtrlFctSeld "select ACC function or CC function.";
CM_ SG_ 224 EngRunngReqByParkAssi1 "Request to keep engine running during a Semi automatic parking manoeuvre.";
CM_ SG_ 224 EngRunngReqByParkAssiChks "counter,For E2E Protection";
CM_ SG_ 224 EngRunngReqByParkAssiCntr "CRC,to check the signal,For E2E Protection";
CM_ SG_ 224 VehSpdLgtA "Vehicle speed longitudinal based on wheel speed sensors and longitudinal acceleration.";
CM_ SG_ 224 VehSpdLgtChks "Checksum";
CM_ SG_ 224 VehSpdLgtCntr "Counter";
CM_ SG_ 224 VehSpdLgtQf "Quality factor for vehicle speed as measured by wheel speed sensors and longitudinal acceleration.";
CM_ SG_ 928 AmbTIndcdWithUnitAmbTIndcd "Indicated ambient temperature";
CM_ SG_ 928 AmbTIndcdWithUnitAmbTIndcdUnit "Unit of the indicated temperature";
CM_ SG_ 928 AmbTIndcdWithUnitQF "QF";
CM_ SG_ 928 WhlBrkWrm " Indication of warm wheel brakes";
CM_ SG_ 433 BrkPedlPsdBrkPedlNotPsdSafe "Set to 1 if brake pedal is not pressed, otherwise 0";
CM_ SG_ 433 BrkPedlPsdBrkPedlPsd "Set to 1 if brake pedal is pressed, otherwise 0";
CM_ SG_ 433 BrkPedlPsdChks "Checksum";
CM_ SG_ 433 BrkPedlPsdCntr "Counter";
CM_ SG_ 433 BrkPedlPsdQf "Quality factor";
CM_ SG_ 433 WhlSpdCircumlFrntChks "Individual wheel speed from front wheel speed sensors. Checksum";
CM_ SG_ 433 WhlSpdCircumlFrntCntr "Individual wheel speed from front wheel speed sensors. Counter";
CM_ SG_ 433 WhlSpdCircumlFrntLe "Individual wheel speed from front wheel speed sensors. Wheel speed from front left wheel speed sensor using nominal value of wheel radius.";
CM_ SG_ 433 WhlSpdCircumlFrntLeQf "Individual wheel speed from front wheel speed sensors. Qf for wheel speed sensor";
CM_ SG_ 433 WhlSpdCircumlFrntRiQf "Individual wheel speed from front wheel speed sensors. Qf for wheel speed sensor";
CM_ SG_ 433 WhlSpdCircumlFrntWhlSpdCircumlFrntRi "Individual wheel speed from front wheel speed sensors. Wheel speed from front right wheel speed sensor using nominal value of wheel radius";
CM_ SG_ 1087 ResrvdSigForECM1 "Reserved signal 1 for ECM.";
CM_ SG_ 1087 ResrvdSigForECM2 "Reserved signal 2 for ECM.";
CM_ SG_ 1087 ResrvdSigForECM3 "Reserved signal 3 for ECM.";
CM_ SG_ 1087 ResrvdSigForECM4 "Reserved signal 4 for ECM.";
CM_ SG_ 432 AgDataRawSafeChks "IMU angular rate data. Check summa";
CM_ SG_ 432 AgDataRawSafeCntr "IMU angular rate data. Counter";
CM_ SG_ 432 AgDataRawSafeRollRate "IMU angular rate data. Roll Rate";
CM_ SG_ 432 AgDataRawSafeRollRateQf "IMU angular rate data. Quality factor for Roll Rate";
CM_ SG_ 432 AgDataRawSafeYawRate "IMU angular rate data. Yaw Rate";
CM_ SG_ 432 AgDataRawSafeYawRateQf "IMU angular rate data. Quality Factor for Yaw Rate";
CM_ SG_ 367 TrsmLockMgrReqCmd " Command to unlock or lock the transmission lock";
CM_ SG_ 367 TrsmLockMgrReqData0 " Response data";
CM_ SG_ 367 TrsmLockMgrReqData1 " Response data";
CM_ SG_ 367 TrsmLockMgrReqData2 " Response data";
CM_ SG_ 367 TrsmLockMgrReqData3 " Response data";
CM_ SG_ 367 TrsmLockMgrReqData4 " Response data";
CM_ SG_ 367 TrsmLockMgrReqData5 " Response data";
CM_ SG_ 367 TrsmLockMgrReqData6 " Response data";
CM_ SG_ 736 AutEgyRgnLvlSet "This signal represents the setting of the energy regeneration level which car with auto level.";
CM_ SG_ 736 ChrgNowReq "Charge immediately button reqest";
CM_ SG_ 736 VehModMngtGlbSafe1CarModSts1 "CarMode Status";
CM_ SG_ 736 VehModMngtGlbSafe1CarModSubtypWdCarModSubtyp "CarMode substate status";
CM_ SG_ 736 VehModMngtGlbSafe1Chks "Checksum";
CM_ SG_ 736 VehModMngtGlbSafe1Cntr "Counter";
CM_ SG_ 736 VehModMngtGlbSafe1EgyLvlElecMai "Main energy level in the vehicle.";
CM_ SG_ 736 VehModMngtGlbSafe1EgyLvlElecSubtyp "Substate of the energy level in the vehicle.";
CM_ SG_ 736 VehModMngtGlbSafe1FltEgyCnsWdSts "High quiescent current detected by CEM via BMS.";
CM_ SG_ 736 VehModMngtGlbSafe1PwrLvlElecMai "Main Power level in the vehicle.";
CM_ SG_ 736 VehModMngtGlbSafe1PwrLvlElecSubtyp "Substate of the power level in the vehicle.";
CM_ SG_ 736 VehModMngtGlbSafe1UsgModSts "UsageMode Status";
CM_ SG_ 38 ChrgSoftSwCtrlSt "sofware control state";
CM_ SG_ 38 IntelliClimaHvacEvaprTSp "Intelligent climate target evaporator temperature";
CM_ SG_ 38 IntelliClimaHvBattInCooltFlowReq "Intelligent climate HV battery target inlet coolant flow";
CM_ SG_ 38 IntelliClimaHvBattInCooltTReq "Intelligent climate HV battery target inlet coolant temperature";
CM_ SG_ 38 IntelliClimaHvCooltHeatrTReq "Intelligent climate HV coolant heater temperature request";
CM_ SG_ 38 IntelliClimaReq "Intelligent climate request";
CM_ SG_ 38 PrpsnHvBattUsgOfChrgTarSOC "the target SOC of Battery usage mode charge to the propulsion";
CM_ SG_ 38 VFCInfoEna "VFCVectorFrame enable and disable setting";
CM_ SG_ 1123 EvaprTReEvaprTFrnt "Actual air temperature after rear evaporator.";
CM_ SG_ 1123 EvaprTReEvaprTQf "Actual air temperature quality flag after rear evaporator.";
CM_ SG_ 1123 SteerSetgPen "IdPen";
CM_ SG_ 1123 SteerSetgSteerAsscLvl "Steer Assistance Level";
CM_ SG_ 1123 SteerSetgSteerMod "Steer Mode";
CM_ SG_ 784 CmptmtTFrntCmptmtTFrnt "Measured temperature in compartment. ";
CM_ SG_ 784 CmptmtTFrntFanForCmptmtTRunng "Fan for component temperature requirement.";
CM_ SG_ 784 CmptmtTFrntQf "Component temperature sensor signal quality.";
CM_ SG_ 137 HsaSt "HSA function status";
CM_ SG_ 137 LVPwrSplyErrSts "Low voltage power supply error status";
CM_ SG_ 137 WhlFastSpdSafeA "Vehicle speed longitudinal based on wheel speed sensors and longitudinal acceleration.";
CM_ SG_ 137 WhlFastSpdSafeChks "checksum";
CM_ SG_ 137 WhlFastSpdSafeCntr "counter";
CM_ SG_ 137 WhlFastSpdSafeQF "Quality factor for vehicle speed as measured by wheel speed sensors and longitudinal acceleration.";
CM_ SG_ 592 VehCfgPrmBlkIDBytePosn1 "signal block counter.";
CM_ SG_ 592 VehCfgPrmCCPBytePosn2 " (BlockID-1)*7 + 1. ";
CM_ SG_ 592 VehCfgPrmCCPBytePosn3 " (BlockID-1)*7 + 2. ";
CM_ SG_ 592 VehCfgPrmCCPBytePosn4 " (BlockID-1)*7 + 3. ";
CM_ SG_ 592 VehCfgPrmCCPBytePosn5 " (BlockID-1)*7 + 4. ";
CM_ SG_ 592 VehCfgPrmCCPBytePosn6 " (BlockID-1)*7 + 5. ";
CM_ SG_ 592 VehCfgPrmCCPBytePosn7 " (BlockID-1)*7 + 6. ";
CM_ SG_ 592 VehCfgPrmCCPBytePosn8 " (BlockID-1)*7 + 7. ";
CM_ SG_ 1015 VehCfgPrmExtBlkIDBytePosn1 "CarConfigExtended BlockID";
CM_ SG_ 1015 VehCfgPrmExtCCPBytePosn2 "CarConfigExtended BytePos2";
CM_ SG_ 1015 VehCfgPrmExtCCPBytePosn3 "CarConfigExtended BytePos3";
CM_ SG_ 1015 VehCfgPrmExtCCPBytePosn4 "CarConfigExtended BytePos4";
CM_ SG_ 1015 VehCfgPrmExtCCPBytePosn5 "CarConfigExtended BytePos5";
CM_ SG_ 1015 VehCfgPrmExtCCPBytePosn6 "CarConfigExtended BytePos6";
CM_ SG_ 1015 VehCfgPrmExtCCPBytePosn7 "CarConfigExtended BytePos7";
CM_ SG_ 1015 VehCfgPrmExtCCPBytePosn8 "CarConfigExtended BytePos8";
CM_ SG_ 775 BookChrgnActvdReq "Book Charging ACtivted Request";
CM_ SG_ 775 BookChrgSetReq "Book charging Setting Request";
CM_ SG_ 775 BookStopTiAchieved "Stop charging time Achieved";
CM_ SG_ 775 LocalBookChrgnTarVal "Battery SOC Value";
CM_ SG_ 775 RemBookChrgnTarVal "Remote Book Charging Target Value";
CM_ SG_ 823 CarTiIntForClima "CCM internal mirror of CarTiGlb. Keeps counting when the bus signal is not available.";
CM_ SG_ 823 ClimaCmptSts "Compartment climate status.";
CM_ SG_ 823 ClimaDefrstSts "Defrost status.";
CM_ SG_ 823 HeatrAirTReq "Heater air temperature request.";
CM_ SG_ 686 AbsSts "Indicates if the ABS function is temporarily or permantly disabled due to a failure.";
CM_ SG_ 686 DrvModReq "drive mode";
CM_ SG_ 686 HvacHexAirTHvacAirTForHeatrFrnt "Temperature";
CM_ SG_ 686 HvacHexAirTHvacAirTForHeatrFrntQf "Interpretation: 
SnsrDataNotOk - The accuracy of the data is undefinable
SnrsDataOk - The data is calculated with the specified accuracy";
CM_ SG_ 686 TelmBookChrgnReq "Telm Book Chrgn Request form APP";
CM_ SG_ 686 TelmBookChrgnTyp "Telm Book Chrgn Type from HIM or APP";
CM_ SG_ 686 ULoWarnChks "Checksum";
CM_ SG_ 686 ULoWarnCntr "Counter";
CM_ SG_ 686 ULoWarnULoWarn "Low voltage warning at LVEEM system";
CM_ SG_ 1267 EscStChks "Information on activation/ deactivation of Electronic Stability Control (ESC) Checksum for Esc state";
CM_ SG_ 1267 EscStCntr "Information on activation/ deactivation of Electronic Stability Control (ESC) Counter for Esc state";
CM_ SG_ 1267 EscStEscSt "Information on activation/ deactivation of Electronic Stability Control (ESC) Esc state information for Esc ON, Esc OFF or Esc Sport";
CM_ SG_ 1099 BrkTracCtrlActv "Indicates InCtrl if brake traction control (TC) is active on at least one wheel.";
CM_ SG_ 1099 HvacHeatgReq "Hvac heating request";
CM_ SG_ 1099 WhlRotToothCntrChks "check sum";
CM_ SG_ 1099 WhlRotToothCntrCntr "counter";
CM_ SG_ 1099 WhlRotToothCntrFrntLe "Wheel rotation ticks for each individual wheel. Wheel rotation impuls counter front left. For one complete wheel revolution the counter will increase by 96 (with 48 magnetic pole-pairs).";
CM_ SG_ 1099 WhlRotToothCntrFrntRi "Wheel rotation ticks for each individual wheel. Wheel rotation impuls counter front right. For one complete wheel revolution the counter will increase by 96 (with 48 magnetic pole-pairs).";
CM_ SG_ 1099 WhlRotToothCntrReLe "Wheel rotation ticks for each individual wheel. Wheel rotation impuls counter rear left. For one complete wheel revolution the counter will increase by 96 (with 48 magnetic pole-pairs).";
CM_ SG_ 1099 WhlRotToothCntrReRi "Wheel rotation ticks for each individual wheel. Wheel rotation impuls counter rear right. For one complete wheel revolution the counter will increase by 96 (with 48 magnetic pole-pairs).";
CM_ SG_ 26 AgDataCmpQualityPitchRateCmpQuality "Quality of offset compensation for pitchrate";
CM_ SG_ 26 AgDataCmpQualityRollRateCmpQuality "Quality of offset compensation for rollrate";
CM_ SG_ 26 AgDataCmpQualityYawRateCmpQuality "Quality of offset compensation for yawrate";
CM_ SG_ 26 BattURaw "Battery Voltage From BMS";
CM_ SG_ 26 EgyRgnLvlSet "This signal represents the setting of the energy regeneration level.
0x0: level1
0x1: level2
0x2: level3
0x3: level4";
CM_ SG_ 1159 VehMtnStChks "Vehicle motion state information based on wheel speed sensors. Provides information about vehicle stand still and vehicle rolling direction. Checksum for vehicle motion state";
CM_ SG_ 1159 VehMtnStCntr "Vehicle motion state information based on wheel speed sensors. Provides information about vehicle stand still and vehicle rolling direction. Counter for vehicle motion state";
CM_ SG_ 1159 VehMtnStVehMtnSt "Vehicle motion state information based on wheel speed sensors. Provides information about vehicle stand still and vehicle rolling direction. Vehicle motion state";
CM_ SG_ 864 CarTiGlb "Presents a tiime value that shall be used by all ECUs to time-stamp diagnsotic trouble codes (DTC) according to the requirements for Global DTC snapshot data.";
CM_ SG_ 864 HvacHeatrInletTempReqEvaprTFrnt "Front evaporator temperature.";
CM_ SG_ 864 HvacHeatrInletTempReqEvaprTQf "Front evaporator signal quality.";
CM_ SG_ 864 ProfPenSts1 "Signal communicates which profile that is active in the car
(Personal settings).";
CM_ SG_ 864 SaveSetgToMemPrmnt "Signal for personal settings saving concept
0: Profile locked, no saving to be performed
1: On the event (toggle 0 to 1) settings shall be saved (manually saving)
2: Automatic saving";
CM_ SG_ 896 BattSocRaw "Battery State of charge from BMS";
CM_ SG_ 896 DstProtnReq "Distance protection setting.";
CM_ SG_ 896 HMIAutoShowModSet "HMI Auto Show Mode Set";
CM_ SG_ 896 TotDstToEmptyDstToEmpty "Indicated Tot distance to Empty  with indicated unit Tot Distance To Empty";
CM_ SG_ 896 TotDstToEmptyDstUnit "Indicated Tot distance to Empty  with indicated unit Tot Distance To Empty";
CM_ SG_ 896 VehBattUSysU "Vehicle System Voltage At 12V side";
CM_ SG_ 896 VehBattUSysUQf "Present vehicle voltage measured by CEM with QF";
CM_ SG_ 513 ImobEngMgrReq3ImobEngDataMgrReq0 "Command from CEM to IGM with desired immo status and 7 bytes of response Byte 0";
CM_ SG_ 513 ImobEngMgrReq3ImobEngDataMgrReq1 "Command from CEM to IGM with desired immo status and 7 bytes of response Byte 1";
CM_ SG_ 513 ImobEngMgrReq3ImobEngDataMgrReq2 "Command from CEM to IGM with desired immo status and 7 bytes of response Byte 2";
CM_ SG_ 513 ImobEngMgrReq3ImobEngDataMgrReq3 "Command from CEM to IGM with desired immo status and 7 bytes of response Byte 3";
CM_ SG_ 513 ImobEngMgrReq3ImobEngDataMgrReq4 "Command from CEM to IGM with desired immo status and 7 bytes of response Byte 4";
CM_ SG_ 513 ImobEngMgrReq3ImobEngDataMgrReq5 "Command from CEM to IGM with desired immo status and 7 bytes of response Byte 5";
CM_ SG_ 513 ImobEngMgrReq3ImobEngDataMgrReq6 "Command from CEM to IGM with desired immo status and 7 bytes of response Byte 6";
CM_ SG_ 513 ImobEngMgrReq3ImobEngMgrCmdTar1 "Command from CEM to IGM with desired immo status and 7 bytes of response Command from CEM";
CM_ SG_ 17 GearPrkgAssiReqGroupChks "checksum";
CM_ SG_ 17 GearPrkgAssiReqGroupCntr "counter";
CM_ SG_ 17 GearPrkgAssiReqGroupGearPrkgAssiReq1 "The target gear request";
CM_ SG_ 17 LgtCtrlModReqSafeChks "checksum";
CM_ SG_ 17 LgtCtrlModReqSafeCntr "counter";
CM_ SG_ 17 LgtCtrlModReqSafeLgtCtrlModReqSafe "Ctrl mode";
CM_ SG_ 17 LgtCtrlModReqSafeLgtFctFailr "Failure mode";
CM_ SG_ 17 OffroadCoolgSwtSts "Soft switch stauts for Off-road cooling function.";
CM_ SG_ 17 PrpsnHvBattUsgModReq "hight voltage power mode request";
CM_ SG_ 496 BkpOfDstTrvld "total traveled distance.";
CM_ SG_ 496 DrvModReqForChampnMod "Drive Mode for champion mode";
CM_ SG_ 496 ESCLvlSwt "ESC level switch";
CM_ SG_ 496 StandStillMgrStsForHld1 "Brake systen hold status";
CM_ SG_ 496 StandStillMgrStsForHldChks "chks";
CM_ SG_ 496 StandStillMgrStsForHldCntr "cntr";
CM_ SG_ 580 IDcDcActLoSideChks "Actul current output checksum";
CM_ SG_ 580 IDcDcActLoSideCntr "Actul current output counter";
CM_ SG_ 580 IDcDcActLoSideIDcDcActLoSide "Actul current output";
CM_ SG_ 439 WhlSpdCircumlReChks "Individual wheel speed from rear wheel speed sensors. Checksum";
CM_ SG_ 439 WhlSpdCircumlReCntr "Individual wheel speed from rear wheel speed sensors. Counter";
CM_ SG_ 439 WhlSpdCircumlReLe "Individual wheel speed from rear wheel speed sensors. Wheel speed from rear left wheel speed sensor using nominal value of wheel radius.";
CM_ SG_ 439 WhlSpdCircumlReLeQf "Individual wheel speed from rear wheel speed sensors. Qf for wheel speed sensor";
CM_ SG_ 439 WhlSpdCircumlReRi "Individual wheel speed from rear wheel speed sensors. Wheel speed from rear right wheel speed sensor using nominal value of wheel radius.";
CM_ SG_ 439 WhlSpdCircumlReRiQf "Individual wheel speed from rear wheel speed sensors. Qf for wheel speed sensor";
CM_ SG_ 52 CrashStsSafeChks "Checksum for E2E";
CM_ SG_ 52 CrashStsSafeCntr "Counter for E2E";
CM_ SG_ 52 CrashStsSafeSts "Information if a crash has been detected by SRS.";
CM_ SG_ 614 CmptmtAirDistbnRspAirDistbnDrvr "Air Distribution for driver";
CM_ SG_ 614 CmptmtAirDistbnRspAirDistbnPass "Air Distribution for passenger";
CM_ SG_ 614 CmptmtAirDistbnRspAirDistbnSecLe "Air Distribution for second left";
CM_ SG_ 614 CmptmtAirDistbnRspAirDistbnSecRi "Air Distribution for second right";
CM_ SG_ 614 CmptmtAirDistbnRspAirDistbnThrd "Air Distribution for third floor";
CM_ SG_ 194 HvahAirTEstmdEvaprTFrnt "Actual air temperature after rear evaporator.";
CM_ SG_ 194 HvahAirTEstmdEvaprTQf "Actual air temperature quality flag after rear evaporator.";
CM_ SG_ 194 ShowTypOfDTESet "selected status of DTE show type set";
BA_DEF_ BO_ "GenMsgCycleTime" INT 0 65536; // [ms]
BA_DEF_ BO_ "GenMsgDelayTime" INT 0 65536; // [ms]
BA_DEF_ BO_ "GenMsgSendType" ENUM "cyclic", "spontaneous", "not-used", "not-used", "not-used", "cyclicAndSpontaneous", "not-used", "cyclicIfActive", "NoMsgSendType"; // [us]
BA_DEF_ BO_ "GenMsgStartDelayTime" INT 0 65536; // [ms]
BA_DEF_ SG_ "GenSigSendType" ENUM "Cyclic","OnWrite","OnWriteWithRepetition","OnChange","OnChangeWithRepetition","IfActive","IfActiveWithRepetition","NoSigSendType";
BA_DEF_ SG_ "GenSigStartValue" HEX 0 80000000;
BA_DEF_ BO_ "GenMsgILSupport" ENUM "No","Yes";
BA_DEF_ BO_ "NmAsrMessage" ENUM "No","Yes";
BA_DEF_ SG_ "GenSigFuncType" ENUM "NoFunction","n/a","n/a","n/a","n/a","n/a","n/a","n/a","n/a","n/a","n/a","n/a","n/a","n/a","n/a","CHK","CNTR","n/a","n/a","n/a","CNTR_AR_01","CRC_AR_01_BOTH","CRC_AR_01_ALT","CRC_AR_01_LOW","CRC_AR_01_NIBBLE","CNTR_AR_04","CRC_AR_04A","CNTR_AR_05","CRC_AR_05";
BA_DEF_ SG_ "GenSigDataID" STRING;
BA_DEF_DEF_ "GenSigStartValue" 0;
BA_DEF_DEF_ "GenSigSendType" "NoSigSendType";
BA_DEF_DEF_ "GenMsgCycleTime" 0;
BA_DEF_DEF_ "GenMsgDelayTime" 0;
BA_DEF_DEF_ "GenMsgStartDelayTime" 0;
BA_DEF_DEF_ "GenMsgSendType" "NoMsgSendType";
BA_DEF_DEF_ "GenMsgILSupport" "Yes";
BA_DEF_DEF_ "NmAsrMessage" "No";
BA_DEF_DEF_ "GenSigFuncType" "NoFunction";
BA_DEF_DEF_ "GenSigDataID" "";
// Frame: TCMChas1Fr23
BA_ "GenMsgCycleTime" BO_ 402 60.000;
BA_ "GenMsgSendType" BO_ 402 0;
// Frame: TCMChas1VfcFr19
BA_ "GenMsgDelayTime" BO_ 756 495.000;
BA_ "GenMsgSendType" BO_ 756 1;
// Frame: TcmChas1Fr14
BA_ "GenMsgCycleTime" BO_ 326 20.000;
BA_ "GenMsgSendType" BO_ 326 0;
// Frame: TcmChas1Fr15
BA_ "GenMsgCycleTime" BO_ 263 15.000;
BA_ "GenMsgSendType" BO_ 263 0;
// Frame: TcmChas1NMFr
BA_ "GenMsgDelayTime" BO_ 1328 20.000;
BA_ "GenMsgSendType" BO_ 1328 1;
// Frame: VcuChas1Fr02
BA_ "GenMsgCycleTime" BO_ 274 20.000;
BA_ "GenMsgSendType" BO_ 274 0;
// Frame: VcuChas1Fr03
BA_ "GenMsgCycleTime" BO_ 85 10.000;
BA_ "GenMsgSendType" BO_ 85 0;
// Frame: VcuChas1Fr04
BA_ "GenMsgCycleTime" BO_ 375 50.000;
BA_ "GenMsgSendType" BO_ 375 0;
// Frame: VcuChas1Fr06
BA_ "GenMsgCycleTime" BO_ 342 30.000;
BA_ "GenMsgSendType" BO_ 342 0;
// Frame: VcuChas1VFCVectorFr
BA_ "GenMsgDelayTime" BO_ 1365 495.000;
BA_ "GenMsgSendType" BO_ 1365 1;
// Frame: VddmChas1DevFr01
BA_ "GenMsgDelayTime" BO_ 1434 95.000;
BA_ "GenMsgSendType" BO_ 1434 1;
// Frame: VddmChas1DevFr02
BA_ "GenMsgDelayTime" BO_ 1435 95.000;
BA_ "GenMsgSendType" BO_ 1435 1;
// Frame: VddmChas1Fr01
BA_ "GenMsgCycleTime" BO_ 81 10.000;
BA_ "GenMsgSendType" BO_ 81 0;
// Frame: VddmChas1Fr03
BA_ "GenMsgCycleTime" BO_ 160 15.000;
BA_ "GenMsgSendType" BO_ 160 0;
// Frame: VddmChas1Fr04
BA_ "GenMsgCycleTime" BO_ 400 20.000;
BA_ "GenMsgSendType" BO_ 400 0;
// Frame: VddmChas1Fr05
BA_ "GenMsgCycleTime" BO_ 224 20.000;
BA_ "GenMsgSendType" BO_ 224 0;
// Frame: VddmChas1Fr08
BA_ "GenMsgCycleTime" BO_ 928 320.000;
BA_ "GenMsgSendType" BO_ 928 0;
// Frame: VddmChas1Fr10
BA_ "GenMsgCycleTime" BO_ 433 30.000;
BA_ "GenMsgSendType" BO_ 433 0;
// Frame: VddmChas1Fr12
BA_ "GenMsgCycleTime" BO_ 1087 350.000;
BA_ "GenMsgSendType" BO_ 1087 0;
// Frame: VddmChas1Fr14
BA_ "GenMsgCycleTime" BO_ 432 30.000;
BA_ "GenMsgSendType" BO_ 432 0;
// Frame: VddmChas1Fr16
BA_ "GenMsgCycleTime" BO_ 367 20.000;
BA_ "GenMsgSendType" BO_ 367 0;
// Frame: VddmChas1Fr19
BA_ "GenMsgCycleTime" BO_ 736 70.000;
BA_ "GenMsgSendType" BO_ 736 0;
// Frame: VddmChas1Fr21
BA_ "GenMsgDelayTime" BO_ 38 300.000;
BA_ "GenMsgSendType" BO_ 38 1;
// Frame: VddmChas1Fr22
BA_ "GenMsgCycleTime" BO_ 1123 170.000;
BA_ "GenMsgSendType" BO_ 1123 0;
// Frame: VddmChas1Fr23
BA_ "GenMsgCycleTime" BO_ 784 170.000;
BA_ "GenMsgSendType" BO_ 784 0;
// Frame: VddmChas1Fr24
BA_ "GenMsgCycleTime" BO_ 137 20.000;
BA_ "GenMsgSendType" BO_ 137 0;
// Frame: VddmChas1Fr30
BA_ "GenMsgDelayTime" BO_ 592 80.000;
BA_ "GenMsgSendType" BO_ 592 1;
// Frame: VddmChas1Fr33
BA_ "GenMsgDelayTime" BO_ 1015 80.000;
BA_ "GenMsgSendType" BO_ 1015 1;
// Frame: VddmChas1Fr34
BA_ "GenMsgDelayTime" BO_ 775 150.000;
BA_ "GenMsgSendType" BO_ 775 1;
// Frame: VddmChas1Fr37
BA_ "GenMsgCycleTime" BO_ 823 165.000;
BA_ "GenMsgSendType" BO_ 823 0;
// Frame: VddmChas1Fr41
BA_ "GenMsgCycleTime" BO_ 686 120.000;
BA_ "GenMsgSendType" BO_ 686 0;
// Frame: VddmChas1Fr44
BA_ "GenMsgCycleTime" BO_ 1267 170.000;
BA_ "GenMsgSendType" BO_ 1267 0;
// Frame: VddmChas1Fr46
BA_ "GenMsgCycleTime" BO_ 1099 170.000;
BA_ "GenMsgSendType" BO_ 1099 0;
// Frame: VddmChas1Fr47
BA_ "GenMsgCycleTime" BO_ 26 100.000;
BA_ "GenMsgSendType" BO_ 26 0;
// Frame: VddmChas1Fr48
BA_ "GenMsgCycleTime" BO_ 1159 700.000;
BA_ "GenMsgSendType" BO_ 1159 0;
// Frame: VddmChas1Fr49
BA_ "GenMsgCycleTime" BO_ 864 80.000;
BA_ "GenMsgSendType" BO_ 864 0;
// Frame: VddmChas1Fr50
BA_ "GenMsgCycleTime" BO_ 896 700.000;
BA_ "GenMsgSendType" BO_ 896 0;
// Frame: VddmChas1Fr51
BA_ "GenMsgCycleTime" BO_ 513 80.000;
BA_ "GenMsgSendType" BO_ 513 0;
// Frame: VddmChas1Fr52
BA_ "GenMsgCycleTime" BO_ 17 10.000;
BA_ "GenMsgSendType" BO_ 17 0;
// Frame: VddmChas1Fr53
BA_ "GenMsgCycleTime" BO_ 496 30.000;
BA_ "GenMsgSendType" BO_ 496 0;
// Frame: VddmChas1Fr54
BA_ "GenMsgCycleTime" BO_ 580 200.000;
BA_ "GenMsgSendType" BO_ 580 0;
// Frame: VddmChas1Fr55
BA_ "GenMsgCycleTime" BO_ 439 30.000;
BA_ "GenMsgSendType" BO_ 439 0;
// Frame: VddmChas1Fr56
BA_ "GenMsgCycleTime" BO_ 52 200.000;
BA_ "GenMsgDelayTime" BO_ 52 20.000;
BA_ "GenMsgSendType" BO_ 52 5;
// Frame: VddmChas1Fr57
BA_ "GenMsgCycleTime" BO_ 614 100.000;
BA_ "GenMsgSendType" BO_ 614 0;
// Frame: VddmChas1Fr58
BA_ "GenMsgCycleTime" BO_ 194 20.000;
BA_ "GenMsgSendType" BO_ 194 0;
// Frame: VddmChas1NMFr
BA_ "GenMsgDelayTime" BO_ 1313 20.000;
BA_ "GenMsgSendType" BO_ 1313 1;
// Frame: VddmToAllFuncChas1DiagReqFrame
BA_ "GenMsgDelayTime" BO_ 2047 5.000;
BA_ "GenMsgSendType" BO_ 2047 1;
// Frame: VddmToPscm100FITbChas1DiagReqFrame
BA_ "GenMsgDelayTime" BO_ 1908 5.000;
BA_ "GenMsgSendType" BO_ 1908 1;
// Frame: VddmToPscmChas1DiagReqFrame
BA_ "GenMsgDelayTime" BO_ 1904 5.000;
BA_ "GenMsgSendType" BO_ 1904 1;
// Frame: VddmToRasmChas1DiagReqFrame
BA_ "GenMsgDelayTime" BO_ 1905 5.000;
BA_ "GenMsgSendType" BO_ 1905 1;
// Frame: VddmToRbcmChas1DiagReqFrame
BA_ "GenMsgDelayTime" BO_ 1909 5.000;
BA_ "GenMsgSendType" BO_ 1909 1;
// Frame: VddmToSasChas1DiagReqFrame
BA_ "GenMsgDelayTime" BO_ 1906 5.000;
BA_ "GenMsgSendType" BO_ 1906 1;
// Frame: VddmToShvcChas1DiagReqFrame
BA_ "GenMsgDelayTime" BO_ 1911 5.000;
BA_ "GenMsgSendType" BO_ 1911 1;
BA_ "GenMsgILSupport" BO_ 1328 0;
BA_ "GenMsgILSupport" BO_ 1313 0;
BA_ "NmAsrMessage" BO_ 1328 1;
BA_ "NmAsrMessage" BO_ 1313 1;
BA_ "GenSigSendType" SG_ 160 ADataRawSafeALat 0;
BA_ "GenSigSendType" SG_ 160 ADataRawSafeALat1Qf 0;
BA_ "GenSigStartValue" SG_ 160 ADataRawSafeALat1Qf 1;
BA_ "GenSigSendType" SG_ 160 ADataRawSafeALgt 0;
BA_ "GenSigSendType" SG_ 160 ADataRawSafeALgt1Qf 0;
BA_ "GenSigStartValue" SG_ 160 ADataRawSafeALgt1Qf 1;
BA_ "GenSigSendType" SG_ 160 ADataRawSafeAVert 0;
BA_ "GenSigStartValue" SG_ 160 ADataRawSafeAVert 1155;
BA_ "GenSigSendType" SG_ 160 ADataRawSafeAVertQf 0;
BA_ "GenSigStartValue" SG_ 160 ADataRawSafeAVertQf 1;
BA_ "GenSigDataID" SG_ 160 ADataRawSafeChks "0x22";
BA_ "GenSigFuncType" SG_ 160 ADataRawSafeChks 15;
BA_ "GenSigSendType" SG_ 160 ADataRawSafeChks 0;
BA_ "GenSigStartValue" SG_ 160 ADataRawSafeChks 255;
BA_ "GenSigFuncType" SG_ 160 ADataRawSafeCntr 16;
BA_ "GenSigSendType" SG_ 160 ADataRawSafeCntr 0;
BA_ "GenSigDataID" SG_ 400 AbsCtrlActvChks "0xD06";
BA_ "GenSigFuncType" SG_ 400 AbsCtrlActvChks 15;
BA_ "GenSigSendType" SG_ 400 AbsCtrlActvChks 0;
BA_ "GenSigFuncType" SG_ 400 AbsCtrlActvCntr 16;
BA_ "GenSigSendType" SG_ 400 AbsCtrlActvCntr 0;
BA_ "GenSigSendType" SG_ 400 AbsCtrlActvCtrlSts1 0;
BA_ "GenSigSendType" SG_ 686 AbsSts 0;
BA_ "GenSigSendType" SG_ 26 AgDataCmpQualityPitchRateCmpQuality 0;
BA_ "GenSigSendType" SG_ 26 AgDataCmpQualityRollRateCmpQuality 0;
BA_ "GenSigSendType" SG_ 26 AgDataCmpQualityYawRateCmpQuality 0;
BA_ "GenSigDataID" SG_ 85 AgDataRaw2SafeChks "0x404";
BA_ "GenSigFuncType" SG_ 85 AgDataRaw2SafeChks 15;
BA_ "GenSigSendType" SG_ 85 AgDataRaw2SafeChks 0;
BA_ "GenSigStartValue" SG_ 85 AgDataRaw2SafeChks 255;
BA_ "GenSigFuncType" SG_ 85 AgDataRaw2SafeCntr 16;
BA_ "GenSigSendType" SG_ 85 AgDataRaw2SafeCntr 0;
BA_ "GenSigSendType" SG_ 85 AgDataRaw2SafePitchRate 0;
BA_ "GenSigSendType" SG_ 85 AgDataRaw2SafePitchRateQf 0;
BA_ "GenSigStartValue" SG_ 85 AgDataRaw2SafePitchRateQf 1;
BA_ "GenSigDataID" SG_ 432 AgDataRawSafeChks "0x23";
BA_ "GenSigFuncType" SG_ 432 AgDataRawSafeChks 15;
BA_ "GenSigSendType" SG_ 432 AgDataRawSafeChks 0;
BA_ "GenSigStartValue" SG_ 432 AgDataRawSafeChks 255;
BA_ "GenSigFuncType" SG_ 432 AgDataRawSafeCntr 16;
BA_ "GenSigSendType" SG_ 432 AgDataRawSafeCntr 0;
BA_ "GenSigSendType" SG_ 432 AgDataRawSafeRollRate 0;
BA_ "GenSigSendType" SG_ 432 AgDataRawSafeRollRateQf 0;
BA_ "GenSigStartValue" SG_ 432 AgDataRawSafeRollRateQf 1;
BA_ "GenSigSendType" SG_ 432 AgDataRawSafeYawRate 0;
BA_ "GenSigSendType" SG_ 432 AgDataRawSafeYawRateQf 0;
BA_ "GenSigStartValue" SG_ 432 AgDataRawSafeYawRateQf 1;
BA_ "GenSigSendType" SG_ 928 AmbTIndcdWithUnitAmbTIndcd 0;
BA_ "GenSigStartValue" SG_ 928 AmbTIndcdWithUnitAmbTIndcd 1000;
BA_ "GenSigSendType" SG_ 928 AmbTIndcdWithUnitAmbTIndcdUnit 0;
BA_ "GenSigSendType" SG_ 928 AmbTIndcdWithUnitQF 0;
BA_ "GenSigSendType" SG_ 400 AmbTRawAmbTVal 0;
BA_ "GenSigStartValue" SG_ 400 AmbTRawAmbTVal 700;
BA_ "GenSigSendType" SG_ 400 AmbTRawQly 0;
BA_ "GenSigSendType" SG_ 81 AsyDataWithCmpSafeALat1Qf 0;
BA_ "GenSigStartValue" SG_ 81 AsyDataWithCmpSafeALat1Qf 1;
BA_ "GenSigSendType" SG_ 81 AsyDataWithCmpSafeALatWithCmp 0;
BA_ "GenSigSendType" SG_ 81 AsyDataWithCmpSafeALgt1Qf 0;
BA_ "GenSigStartValue" SG_ 81 AsyDataWithCmpSafeALgt1Qf 1;
BA_ "GenSigDataID" SG_ 81 AsyDataWithCmpSafeChks "0x24";
BA_ "GenSigFuncType" SG_ 81 AsyDataWithCmpSafeChks 15;
BA_ "GenSigSendType" SG_ 81 AsyDataWithCmpSafeChks 0;
BA_ "GenSigStartValue" SG_ 81 AsyDataWithCmpSafeChks 255;
BA_ "GenSigFuncType" SG_ 81 AsyDataWithCmpSafeCntr 16;
BA_ "GenSigSendType" SG_ 81 AsyDataWithCmpSafeCntr 0;
BA_ "GenSigSendType" SG_ 81 AsyDataWithCmpSafeGrdtOfALgt 0;
BA_ "GenSigSendType" SG_ 81 AsyDataWithCmpSafeYawRateQf 0;
BA_ "GenSigStartValue" SG_ 81 AsyDataWithCmpSafeYawRateQf 1;
BA_ "GenSigSendType" SG_ 81 AsyDataWithCmpSafeYawRateWithCmp 0;
BA_ "GenSigSendType" SG_ 736 AutEgyRgnLvlSet 0;
BA_ "GenSigStartValue" SG_ 736 AutEgyRgnLvlSet 3;
BA_ "GenSigSendType" SG_ 896 BattSocRaw 0;
BA_ "GenSigSendType" SG_ 26 BattURaw 0;
BA_ "GenSigSendType" SG_ 496 BkpOfDstTrvld 0;
BA_ "GenSigSendType" SG_ 775 BookChrgSetReq 1;
BA_ "GenSigSendType" SG_ 775 BookChrgnActvdReq 1;
BA_ "GenSigSendType" SG_ 775 BookStopTiAchieved 1;
BA_ "GenSigSendType" SG_ 402 BoostIndctnILeft 0;
BA_ "GenSigStartValue" SG_ 402 BoostIndctnILeft 8188;
BA_ "GenSigSendType" SG_ 402 BoostIndctnIRht 0;
BA_ "GenSigStartValue" SG_ 402 BoostIndctnIRht 8188;
BA_ "GenSigSendType" SG_ 402 BoostPwrLimMax 0;
BA_ "GenSigSendType" SG_ 402 BoostPwrLimMin 0;
BA_ "GenSigStartValue" SG_ 402 BoostPwrLimMin 255;
BA_ "GenSigSendType" SG_ 433 BrkPedlPsdBrkPedlNotPsdSafe 0;
BA_ "GenSigSendType" SG_ 433 BrkPedlPsdBrkPedlPsd 0;
BA_ "GenSigDataID" SG_ 433 BrkPedlPsdChks "0x38";
BA_ "GenSigFuncType" SG_ 433 BrkPedlPsdChks 15;
BA_ "GenSigSendType" SG_ 433 BrkPedlPsdChks 0;
BA_ "GenSigFuncType" SG_ 433 BrkPedlPsdCntr 16;
BA_ "GenSigSendType" SG_ 433 BrkPedlPsdCntr 0;
BA_ "GenSigSendType" SG_ 433 BrkPedlPsdQf 0;
BA_ "GenSigSendType" SG_ 1099 BrkTracCtrlActv 0;
BA_ "GenSigSendType" SG_ 864 CarTiGlb 0;
BA_ "GenSigSendType" SG_ 823 CarTiIntForClima 0;
BA_ "GenSigSendType" SG_ 736 ChrgNowReq 1;
BA_ "GenSigSendType" SG_ 38 ChrgSoftSwCtrlSt 1;
BA_ "GenSigSendType" SG_ 823 ClimaCmptSts 0;
BA_ "GenSigSendType" SG_ 823 ClimaDefrstSts 0;
BA_ "GenSigSendType" SG_ 614 CmptmtAirDistbnRspAirDistbnDrvr 0;
BA_ "GenSigSendType" SG_ 614 CmptmtAirDistbnRspAirDistbnPass 0;
BA_ "GenSigSendType" SG_ 614 CmptmtAirDistbnRspAirDistbnSecLe 0;
BA_ "GenSigSendType" SG_ 614 CmptmtAirDistbnRspAirDistbnSecRi 0;
BA_ "GenSigSendType" SG_ 614 CmptmtAirDistbnRspAirDistbnThrd 0;
BA_ "GenSigSendType" SG_ 784 CmptmtTFrntCmptmtTFrnt 0;
BA_ "GenSigStartValue" SG_ 784 CmptmtTFrntCmptmtTFrnt 600;
BA_ "GenSigSendType" SG_ 784 CmptmtTFrntFanForCmptmtTRunng 0;
BA_ "GenSigSendType" SG_ 784 CmptmtTFrntQf 0;
BA_ "GenSigStartValue" SG_ 784 CmptmtTFrntQf 1;
BA_ "GenSigSendType" SG_ 224 CnvnReq 0;
BA_ "GenSigDataID" SG_ 52 CrashStsSafeChks "0x40B";
BA_ "GenSigFuncType" SG_ 52 CrashStsSafeChks 15;
BA_ "GenSigSendType" SG_ 52 CrashStsSafeChks 1;
BA_ "GenSigStartValue" SG_ 52 CrashStsSafeChks 255;
BA_ "GenSigFuncType" SG_ 52 CrashStsSafeCntr 16;
BA_ "GenSigSendType" SG_ 52 CrashStsSafeCntr 1;
BA_ "GenSigSendType" SG_ 52 CrashStsSafeSts 1;
BA_ "GenSigSendType" SG_ 686 DrvModReq 0;
BA_ "GenSigSendType" SG_ 496 DrvModReqForChampnMod 0;
BA_ "GenSigSendType" SG_ 224 DrvrCrsCtrlFctSeld 0;
BA_ "GenSigSendType" SG_ 896 DstProtnReq 0;
BA_ "GenSigStartValue" SG_ 896 DstProtnReq 150;
BA_ "GenSigSendType" SG_ 496 ESCLvlSwt 0;
BA_ "GenSigSendType" SG_ 26 EgyRgnLvlSet 0;
BA_ "GenSigSendType" SG_ 224 EngRunngReqByParkAssi1 0;
BA_ "GenSigDataID" SG_ 224 EngRunngReqByParkAssiChks "0x0F";
BA_ "GenSigFuncType" SG_ 224 EngRunngReqByParkAssiChks 15;
BA_ "GenSigSendType" SG_ 224 EngRunngReqByParkAssiChks 0;
BA_ "GenSigFuncType" SG_ 224 EngRunngReqByParkAssiCntr 16;
BA_ "GenSigSendType" SG_ 224 EngRunngReqByParkAssiCntr 0;
BA_ "GenSigDataID" SG_ 1267 EscStChks "0x7F";
BA_ "GenSigFuncType" SG_ 1267 EscStChks 15;
BA_ "GenSigSendType" SG_ 1267 EscStChks 0;
BA_ "GenSigFuncType" SG_ 1267 EscStCntr 16;
BA_ "GenSigSendType" SG_ 1267 EscStCntr 0;
BA_ "GenSigSendType" SG_ 1267 EscStEscSt 0;
BA_ "GenSigStartValue" SG_ 1267 EscStEscSt 1;
BA_ "GenSigSendType" SG_ 1123 EvaprTReEvaprTFrnt 0;
BA_ "GenSigSendType" SG_ 1123 EvaprTReEvaprTQf 0;
BA_ "GenSigStartValue" SG_ 1123 EvaprTReEvaprTQf 1;
BA_ "GenSigDataID" SG_ 17 GearPrkgAssiReqGroupChks "0x02";
BA_ "GenSigFuncType" SG_ 17 GearPrkgAssiReqGroupChks 15;
BA_ "GenSigSendType" SG_ 17 GearPrkgAssiReqGroupChks 0;
BA_ "GenSigFuncType" SG_ 17 GearPrkgAssiReqGroupCntr 16;
BA_ "GenSigSendType" SG_ 17 GearPrkgAssiReqGroupCntr 0;
BA_ "GenSigSendType" SG_ 17 GearPrkgAssiReqGroupGearPrkgAssiReq1 0;
BA_ "GenSigSendType" SG_ 896 HMIAutoShowModSet 0;
BA_ "GenSigSendType" SG_ 823 HeatrAirTReq 0;
BA_ "GenSigStartValue" SG_ 823 HeatrAirTReq 120;
BA_ "GenSigSendType" SG_ 137 HsaSt 0;
BA_ "GenSigStartValue" SG_ 137 HsaSt 1;
BA_ "GenSigSendType" SG_ 375 HvBattSoc 0;
BA_ "GenSigDataID" SG_ 375 HvSysRlyStsChks "0x15";
BA_ "GenSigFuncType" SG_ 375 HvSysRlyStsChks 15;
BA_ "GenSigSendType" SG_ 375 HvSysRlyStsChks 0;
BA_ "GenSigFuncType" SG_ 375 HvSysRlyStsCntr 16;
BA_ "GenSigSendType" SG_ 375 HvSysRlyStsCntr 0;
BA_ "GenSigSendType" SG_ 375 HvSysRlyStsHvSysRlySts 0;
BA_ "GenSigStartValue" SG_ 375 HvSysRlyStsHvSysRlySts 2;
BA_ "GenSigSendType" SG_ 1099 HvacHeatgReq 0;
BA_ "GenSigSendType" SG_ 864 HvacHeatrInletTempReqEvaprTFrnt 0;
BA_ "GenSigSendType" SG_ 864 HvacHeatrInletTempReqEvaprTQf 0;
BA_ "GenSigSendType" SG_ 686 HvacHexAirTHvacAirTForHeatrFrnt 0;
BA_ "GenSigSendType" SG_ 686 HvacHexAirTHvacAirTForHeatrFrntQf 0;
BA_ "GenSigStartValue" SG_ 686 HvacHexAirTHvacAirTForHeatrFrntQf 1;
BA_ "GenSigSendType" SG_ 194 HvahAirTEstmdEvaprTFrnt 0;
BA_ "GenSigSendType" SG_ 194 HvahAirTEstmdEvaprTQf 0;
BA_ "GenSigStartValue" SG_ 194 HvahAirTEstmdEvaprTQf 1;
BA_ "GenSigDataID" SG_ 580 IDcDcActLoSideChks "0x14";
BA_ "GenSigFuncType" SG_ 580 IDcDcActLoSideChks 15;
BA_ "GenSigSendType" SG_ 580 IDcDcActLoSideChks 0;
BA_ "GenSigFuncType" SG_ 580 IDcDcActLoSideCntr 16;
BA_ "GenSigSendType" SG_ 580 IDcDcActLoSideCntr 0;
BA_ "GenSigSendType" SG_ 580 IDcDcActLoSideIDcDcActLoSide 0;
BA_ "GenSigSendType" SG_ 513 ImobEngMgrReq3ImobEngDataMgrReq0 0;
BA_ "GenSigSendType" SG_ 513 ImobEngMgrReq3ImobEngDataMgrReq1 0;
BA_ "GenSigSendType" SG_ 513 ImobEngMgrReq3ImobEngDataMgrReq2 0;
BA_ "GenSigSendType" SG_ 513 ImobEngMgrReq3ImobEngDataMgrReq3 0;
BA_ "GenSigSendType" SG_ 513 ImobEngMgrReq3ImobEngDataMgrReq4 0;
BA_ "GenSigSendType" SG_ 513 ImobEngMgrReq3ImobEngDataMgrReq5 0;
BA_ "GenSigSendType" SG_ 513 ImobEngMgrReq3ImobEngDataMgrReq6 0;
BA_ "GenSigSendType" SG_ 513 ImobEngMgrReq3ImobEngMgrCmdTar1 0;
BA_ "GenSigSendType" SG_ 38 IntelliClimaHvBattInCooltFlowReq 1;
BA_ "GenSigSendType" SG_ 38 IntelliClimaHvBattInCooltTReq 1;
BA_ "GenSigStartValue" SG_ 38 IntelliClimaHvBattInCooltTReq 50;
BA_ "GenSigSendType" SG_ 38 IntelliClimaHvCooltHeatrTReq 1;
BA_ "GenSigStartValue" SG_ 38 IntelliClimaHvCooltHeatrTReq 40;
BA_ "GenSigSendType" SG_ 38 IntelliClimaHvacEvaprTSp 1;
BA_ "GenSigStartValue" SG_ 38 IntelliClimaHvacEvaprTSp 50;
BA_ "GenSigSendType" SG_ 38 IntelliClimaReq 1;
BA_ "GenSigSendType" SG_ 137 LVPwrSplyErrSts 0;
BA_ "GenSigDataID" SG_ 400 LatCtrlReqSafeChks "0x30";
BA_ "GenSigFuncType" SG_ 400 LatCtrlReqSafeChks 15;
BA_ "GenSigSendType" SG_ 400 LatCtrlReqSafeChks 0;
BA_ "GenSigFuncType" SG_ 400 LatCtrlReqSafeCntr 16;
BA_ "GenSigSendType" SG_ 400 LatCtrlReqSafeCntr 0;
BA_ "GenSigSendType" SG_ 400 LatCtrlReqSafeLatCtrlModReq 0;
BA_ "GenSigSendType" SG_ 400 LatCtrlReqSafeSteerTqReq 0;
BA_ "GenSigSendType" SG_ 400 LatCtrlReqSafeSteerWhlHptcWarnReq 0;
BA_ "GenSigDataID" SG_ 17 LgtCtrlModReqSafeChks "0x422";
BA_ "GenSigFuncType" SG_ 17 LgtCtrlModReqSafeChks 15;
BA_ "GenSigSendType" SG_ 17 LgtCtrlModReqSafeChks 0;
BA_ "GenSigFuncType" SG_ 17 LgtCtrlModReqSafeCntr 16;
BA_ "GenSigSendType" SG_ 17 LgtCtrlModReqSafeCntr 0;
BA_ "GenSigSendType" SG_ 17 LgtCtrlModReqSafeLgtCtrlModReqSafe 0;
BA_ "GenSigSendType" SG_ 17 LgtCtrlModReqSafeLgtFctFailr 0;
BA_ "GenSigSendType" SG_ 775 LocalBookChrgnTarVal 1;
BA_ "GenSigSendType" SG_ 17 OffroadCoolgSwtSts 0;
BA_ "GenSigSendType" SG_ 864 ProfPenSts1 0;
BA_ "GenSigSendType" SG_ 17 PrpsnHvBattUsgModReq 0;
BA_ "GenSigSendType" SG_ 38 PrpsnHvBattUsgOfChrgTarSOC 1;
BA_ "GenSigStartValue" SG_ 38 PrpsnHvBattUsgOfChrgTarSOC 1000;
BA_ "GenSigSendType" SG_ 775 RemBookChrgnTarVal 1;
BA_ "GenSigSendType" SG_ 1087 ResrvdSigForECM1 0;
BA_ "GenSigSendType" SG_ 1087 ResrvdSigForECM2 0;
BA_ "GenSigSendType" SG_ 1087 ResrvdSigForECM3 0;
BA_ "GenSigSendType" SG_ 1087 ResrvdSigForECM4 0;
BA_ "GenSigSendType" SG_ 375 RlyPwrDistbnCmd1WdIgnRlyCmd 0;
BA_ "GenSigSendType" SG_ 864 SaveSetgToMemPrmnt 0;
BA_ "GenSigSendType" SG_ 274 SecParkBrkSysSt2BrkSysSt 0;
BA_ "GenSigDataID" SG_ 274 SecParkBrkSysSt2Chks "0x1989";
BA_ "GenSigFuncType" SG_ 274 SecParkBrkSysSt2Chks 15;
BA_ "GenSigSendType" SG_ 274 SecParkBrkSysSt2Chks 0;
BA_ "GenSigFuncType" SG_ 274 SecParkBrkSysSt2Cntr 16;
BA_ "GenSigSendType" SG_ 274 SecParkBrkSysSt2Cntr 0;
BA_ "GenSigSendType" SG_ 194 ShowTypOfDTESet 1;
BA_ "GenSigSendType" SG_ 496 StandStillMgrStsForHld1 0;
BA_ "GenSigDataID" SG_ 496 StandStillMgrStsForHldChks "0x448";
BA_ "GenSigFuncType" SG_ 496 StandStillMgrStsForHldChks 15;
BA_ "GenSigSendType" SG_ 496 StandStillMgrStsForHldChks 0;
BA_ "GenSigFuncType" SG_ 496 StandStillMgrStsForHldCntr 16;
BA_ "GenSigSendType" SG_ 496 StandStillMgrStsForHldCntr 0;
BA_ "GenSigSendType" SG_ 1123 SteerSetgPen 0;
BA_ "GenSigSendType" SG_ 1123 SteerSetgSteerAsscLvl 0;
BA_ "GenSigSendType" SG_ 1123 SteerSetgSteerMod 0;
BA_ "GenSigSendType" SG_ 686 TelmBookChrgnReq 1;
BA_ "GenSigSendType" SG_ 686 TelmBookChrgnTyp 0;
BA_ "GenSigSendType" SG_ 342 TiAndDateIndcnDataValid 0;
BA_ "GenSigSendType" SG_ 342 TiAndDateIndcnDay 0;
BA_ "GenSigStartValue" SG_ 342 TiAndDateIndcnDay 1;
BA_ "GenSigSendType" SG_ 342 TiAndDateIndcnHr1 0;
BA_ "GenSigSendType" SG_ 342 TiAndDateIndcnMins1 0;
BA_ "GenSigSendType" SG_ 342 TiAndDateIndcnMth1 0;
BA_ "GenSigStartValue" SG_ 342 TiAndDateIndcnMth1 1;
BA_ "GenSigSendType" SG_ 342 TiAndDateIndcnSec1 0;
BA_ "GenSigSendType" SG_ 342 TiAndDateIndcnYr1 0;
BA_ "GenSigSendType" SG_ 896 TotDstToEmptyDstToEmpty 0;
BA_ "GenSigSendType" SG_ 896 TotDstToEmptyDstUnit 0;
BA_ "GenSigDataID" SG_ 326 TrsmEngNTqMaxChks "0x42";
BA_ "GenSigFuncType" SG_ 326 TrsmEngNTqMaxChks 15;
BA_ "GenSigSendType" SG_ 326 TrsmEngNTqMaxChks 0;
BA_ "GenSigFuncType" SG_ 326 TrsmEngNTqMaxCntr 16;
BA_ "GenSigSendType" SG_ 326 TrsmEngNTqMaxCntr 0;
BA_ "GenSigSendType" SG_ 326 TrsmEngNTqMaxTrsmEngNTqMax 0;
BA_ "GenSigStartValue" SG_ 326 TrsmEngNTqMaxTrsmEngNTqMax 1024;
BA_ "GenSigSendType" SG_ 263 TrsmFltIndcn 0;
BA_ "GenSigSendType" SG_ 326 TrsmGearNotAvlSts 0;
BA_ "GenSigSendType" SG_ 367 TrsmLockMgrReqCmd 0;
BA_ "GenSigSendType" SG_ 367 TrsmLockMgrReqData0 0;
BA_ "GenSigSendType" SG_ 367 TrsmLockMgrReqData1 0;
BA_ "GenSigSendType" SG_ 367 TrsmLockMgrReqData2 0;
BA_ "GenSigSendType" SG_ 367 TrsmLockMgrReqData3 0;
BA_ "GenSigSendType" SG_ 367 TrsmLockMgrReqData4 0;
BA_ "GenSigSendType" SG_ 367 TrsmLockMgrReqData5 0;
BA_ "GenSigSendType" SG_ 367 TrsmLockMgrReqData6 0;
BA_ "GenSigSendType" SG_ 263 TrsmModNotAvlSts3 0;
BA_ "GenSigDataID" SG_ 686 ULoWarnChks "0x43";
BA_ "GenSigFuncType" SG_ 686 ULoWarnChks 15;
BA_ "GenSigSendType" SG_ 686 ULoWarnChks 0;
BA_ "GenSigFuncType" SG_ 686 ULoWarnCntr 16;
BA_ "GenSigSendType" SG_ 686 ULoWarnCntr 0;
BA_ "GenSigSendType" SG_ 686 ULoWarnULoWarn 0;
BA_ "GenSigSendType" SG_ 1434 VDDMdevelpsignalgroupresp1Functiondevpsignalgroup1 1;
BA_ "GenSigSendType" SG_ 1434 VDDMdevelpsignalgroupresp1Functiondevpsignalgroup2 1;
BA_ "GenSigSendType" SG_ 1434 VDDMdevelpsignalgroupresp1Functiondevpsignalgroup3 1;
BA_ "GenSigSendType" SG_ 1434 VDDMdevelpsignalgroupresp1Functiondevpsignalgroup4 1;
BA_ "GenSigSendType" SG_ 1434 VDDMdevelpsignalgroupresp1Functiondevpsignalgroup5 1;
BA_ "GenSigSendType" SG_ 1434 VDDMdevelpsignalgroupresp1Functiondevpsignalgroup6 1;
BA_ "GenSigSendType" SG_ 1434 VDDMdevelpsignalgroupresp1Functiondevpsignalgroup7 1;
BA_ "GenSigSendType" SG_ 1434 VDDMdevelpsignalgroupresp1Functiondevpsignalgroup8 1;
BA_ "GenSigSendType" SG_ 1435 VDDMdevelpsignalgroupresp2Functiondevpsignalgroup1 1;
BA_ "GenSigSendType" SG_ 1435 VDDMdevelpsignalgroupresp2Functiondevpsignalgroup2 1;
BA_ "GenSigSendType" SG_ 1435 VDDMdevelpsignalgroupresp2Functiondevpsignalgroup3 1;
BA_ "GenSigSendType" SG_ 1435 VDDMdevelpsignalgroupresp2Functiondevpsignalgroup4 1;
BA_ "GenSigSendType" SG_ 1435 VDDMdevelpsignalgroupresp2Functiondevpsignalgroup5 1;
BA_ "GenSigSendType" SG_ 1435 VDDMdevelpsignalgroupresp2Functiondevpsignalgroup6 1;
BA_ "GenSigSendType" SG_ 1435 VDDMdevelpsignalgroupresp2Functiondevpsignalgroup7 1;
BA_ "GenSigSendType" SG_ 1435 VDDMdevelpsignalgroupresp2Functiondevpsignalgroup8 1;
BA_ "GenSigSendType" SG_ 38 VFCInfoEna 1;
BA_ "GenSigSendType" SG_ 756 VFCVectorPCMBlockID 1;
BA_ "GenSigSendType" SG_ 756 VFCVectorPCMVFCid0 1;
BA_ "GenSigSendType" SG_ 756 VFCVectorPCMVFCid1 1;
BA_ "GenSigSendType" SG_ 756 VFCVectorPCMVFCid10 1;
BA_ "GenSigSendType" SG_ 756 VFCVectorPCMVFCid11 1;
BA_ "GenSigSendType" SG_ 756 VFCVectorPCMVFCid12 1;
BA_ "GenSigSendType" SG_ 756 VFCVectorPCMVFCid13 1;
BA_ "GenSigSendType" SG_ 756 VFCVectorPCMVFCid14 1;
BA_ "GenSigSendType" SG_ 756 VFCVectorPCMVFCid15 1;
BA_ "GenSigSendType" SG_ 756 VFCVectorPCMVFCid16 1;
BA_ "GenSigSendType" SG_ 756 VFCVectorPCMVFCid17 1;
BA_ "GenSigSendType" SG_ 756 VFCVectorPCMVFCid18 1;
BA_ "GenSigSendType" SG_ 756 VFCVectorPCMVFCid19 1;
BA_ "GenSigSendType" SG_ 756 VFCVectorPCMVFCid2 1;
BA_ "GenSigSendType" SG_ 756 VFCVectorPCMVFCid20 1;
BA_ "GenSigSendType" SG_ 756 VFCVectorPCMVFCid21 1;
BA_ "GenSigSendType" SG_ 756 VFCVectorPCMVFCid22 1;
BA_ "GenSigSendType" SG_ 756 VFCVectorPCMVFCid23 1;
BA_ "GenSigSendType" SG_ 756 VFCVectorPCMVFCid24 1;
BA_ "GenSigSendType" SG_ 756 VFCVectorPCMVFCid25 1;
BA_ "GenSigSendType" SG_ 756 VFCVectorPCMVFCid26 1;
BA_ "GenSigSendType" SG_ 756 VFCVectorPCMVFCid27 1;
BA_ "GenSigSendType" SG_ 756 VFCVectorPCMVFCid28 1;
BA_ "GenSigSendType" SG_ 756 VFCVectorPCMVFCid29 1;
BA_ "GenSigSendType" SG_ 756 VFCVectorPCMVFCid3 1;
BA_ "GenSigSendType" SG_ 756 VFCVectorPCMVFCid30 1;
BA_ "GenSigSendType" SG_ 756 VFCVectorPCMVFCid31 1;
BA_ "GenSigSendType" SG_ 756 VFCVectorPCMVFCid32 1;
BA_ "GenSigSendType" SG_ 756 VFCVectorPCMVFCid33 1;
BA_ "GenSigSendType" SG_ 756 VFCVectorPCMVFCid34 1;
BA_ "GenSigSendType" SG_ 756 VFCVectorPCMVFCid35 1;
BA_ "GenSigSendType" SG_ 756 VFCVectorPCMVFCid36 1;
BA_ "GenSigSendType" SG_ 756 VFCVectorPCMVFCid37 1;
BA_ "GenSigSendType" SG_ 756 VFCVectorPCMVFCid38 1;
BA_ "GenSigSendType" SG_ 756 VFCVectorPCMVFCid39 1;
BA_ "GenSigSendType" SG_ 756 VFCVectorPCMVFCid4 1;
BA_ "GenSigSendType" SG_ 756 VFCVectorPCMVFCid40 1;
BA_ "GenSigSendType" SG_ 756 VFCVectorPCMVFCid41 1;
BA_ "GenSigSendType" SG_ 756 VFCVectorPCMVFCid42 1;
BA_ "GenSigSendType" SG_ 756 VFCVectorPCMVFCid43 1;
BA_ "GenSigSendType" SG_ 756 VFCVectorPCMVFCid44 1;
BA_ "GenSigSendType" SG_ 756 VFCVectorPCMVFCid45 1;
BA_ "GenSigSendType" SG_ 756 VFCVectorPCMVFCid46 1;
BA_ "GenSigSendType" SG_ 756 VFCVectorPCMVFCid47 1;
BA_ "GenSigSendType" SG_ 756 VFCVectorPCMVFCid48 1;
BA_ "GenSigSendType" SG_ 756 VFCVectorPCMVFCid49 1;
BA_ "GenSigSendType" SG_ 756 VFCVectorPCMVFCid5 1;
BA_ "GenSigSendType" SG_ 756 VFCVectorPCMVFCid50 1;
BA_ "GenSigSendType" SG_ 756 VFCVectorPCMVFCid51 1;
BA_ "GenSigSendType" SG_ 756 VFCVectorPCMVFCid52 1;
BA_ "GenSigSendType" SG_ 756 VFCVectorPCMVFCid53 1;
BA_ "GenSigSendType" SG_ 756 VFCVectorPCMVFCid54 1;
BA_ "GenSigSendType" SG_ 756 VFCVectorPCMVFCid55 1;
BA_ "GenSigSendType" SG_ 756 VFCVectorPCMVFCid56 1;
BA_ "GenSigSendType" SG_ 756 VFCVectorPCMVFCid57 1;
BA_ "GenSigSendType" SG_ 756 VFCVectorPCMVFCid58 1;
BA_ "GenSigSendType" SG_ 756 VFCVectorPCMVFCid59 1;
BA_ "GenSigSendType" SG_ 756 VFCVectorPCMVFCid6 1;
BA_ "GenSigSendType" SG_ 756 VFCVectorPCMVFCid60 1;
BA_ "GenSigSendType" SG_ 756 VFCVectorPCMVFCid61 1;
BA_ "GenSigSendType" SG_ 756 VFCVectorPCMVFCid7 1;
BA_ "GenSigSendType" SG_ 756 VFCVectorPCMVFCid8 1;
BA_ "GenSigSendType" SG_ 756 VFCVectorPCMVFCid9 1;
BA_ "GenSigSendType" SG_ 1365 VFCVectorVCUBlockID 1;
BA_ "GenSigSendType" SG_ 1365 VFCVectorVCUVFCid0 1;
BA_ "GenSigSendType" SG_ 1365 VFCVectorVCUVFCid1 1;
BA_ "GenSigSendType" SG_ 1365 VFCVectorVCUVFCid10 1;
BA_ "GenSigSendType" SG_ 1365 VFCVectorVCUVFCid11 1;
BA_ "GenSigSendType" SG_ 1365 VFCVectorVCUVFCid12 1;
BA_ "GenSigSendType" SG_ 1365 VFCVectorVCUVFCid13 1;
BA_ "GenSigSendType" SG_ 1365 VFCVectorVCUVFCid14 1;
BA_ "GenSigSendType" SG_ 1365 VFCVectorVCUVFCid15 1;
BA_ "GenSigSendType" SG_ 1365 VFCVectorVCUVFCid16 1;
BA_ "GenSigSendType" SG_ 1365 VFCVectorVCUVFCid17 1;
BA_ "GenSigSendType" SG_ 1365 VFCVectorVCUVFCid18 1;
BA_ "GenSigSendType" SG_ 1365 VFCVectorVCUVFCid19 1;
BA_ "GenSigSendType" SG_ 1365 VFCVectorVCUVFCid2 1;
BA_ "GenSigSendType" SG_ 1365 VFCVectorVCUVFCid20 1;
BA_ "GenSigSendType" SG_ 1365 VFCVectorVCUVFCid21 1;
BA_ "GenSigSendType" SG_ 1365 VFCVectorVCUVFCid22 1;
BA_ "GenSigSendType" SG_ 1365 VFCVectorVCUVFCid23 1;
BA_ "GenSigSendType" SG_ 1365 VFCVectorVCUVFCid24 1;
BA_ "GenSigSendType" SG_ 1365 VFCVectorVCUVFCid25 1;
BA_ "GenSigSendType" SG_ 1365 VFCVectorVCUVFCid26 1;
BA_ "GenSigSendType" SG_ 1365 VFCVectorVCUVFCid27 1;
BA_ "GenSigSendType" SG_ 1365 VFCVectorVCUVFCid28 1;
BA_ "GenSigSendType" SG_ 1365 VFCVectorVCUVFCid29 1;
BA_ "GenSigSendType" SG_ 1365 VFCVectorVCUVFCid3 1;
BA_ "GenSigSendType" SG_ 1365 VFCVectorVCUVFCid30 1;
BA_ "GenSigSendType" SG_ 1365 VFCVectorVCUVFCid31 1;
BA_ "GenSigSendType" SG_ 1365 VFCVectorVCUVFCid32 1;
BA_ "GenSigSendType" SG_ 1365 VFCVectorVCUVFCid33 1;
BA_ "GenSigSendType" SG_ 1365 VFCVectorVCUVFCid34 1;
BA_ "GenSigSendType" SG_ 1365 VFCVectorVCUVFCid35 1;
BA_ "GenSigSendType" SG_ 1365 VFCVectorVCUVFCid36 1;
BA_ "GenSigSendType" SG_ 1365 VFCVectorVCUVFCid37 1;
BA_ "GenSigSendType" SG_ 1365 VFCVectorVCUVFCid38 1;
BA_ "GenSigSendType" SG_ 1365 VFCVectorVCUVFCid39 1;
BA_ "GenSigSendType" SG_ 1365 VFCVectorVCUVFCid4 1;
BA_ "GenSigSendType" SG_ 1365 VFCVectorVCUVFCid40 1;
BA_ "GenSigSendType" SG_ 1365 VFCVectorVCUVFCid41 1;
BA_ "GenSigSendType" SG_ 1365 VFCVectorVCUVFCid42 1;
BA_ "GenSigSendType" SG_ 1365 VFCVectorVCUVFCid43 1;
BA_ "GenSigSendType" SG_ 1365 VFCVectorVCUVFCid44 1;
BA_ "GenSigSendType" SG_ 1365 VFCVectorVCUVFCid45 1;
BA_ "GenSigSendType" SG_ 1365 VFCVectorVCUVFCid46 1;
BA_ "GenSigSendType" SG_ 1365 VFCVectorVCUVFCid47 1;
BA_ "GenSigSendType" SG_ 1365 VFCVectorVCUVFCid48 1;
BA_ "GenSigSendType" SG_ 1365 VFCVectorVCUVFCid49 1;
BA_ "GenSigSendType" SG_ 1365 VFCVectorVCUVFCid5 1;
BA_ "GenSigSendType" SG_ 1365 VFCVectorVCUVFCid50 1;
BA_ "GenSigSendType" SG_ 1365 VFCVectorVCUVFCid51 1;
BA_ "GenSigSendType" SG_ 1365 VFCVectorVCUVFCid52 1;
BA_ "GenSigSendType" SG_ 1365 VFCVectorVCUVFCid53 1;
BA_ "GenSigSendType" SG_ 1365 VFCVectorVCUVFCid54 1;
BA_ "GenSigSendType" SG_ 1365 VFCVectorVCUVFCid55 1;
BA_ "GenSigSendType" SG_ 1365 VFCVectorVCUVFCid56 1;
BA_ "GenSigSendType" SG_ 1365 VFCVectorVCUVFCid57 1;
BA_ "GenSigSendType" SG_ 1365 VFCVectorVCUVFCid58 1;
BA_ "GenSigSendType" SG_ 1365 VFCVectorVCUVFCid59 1;
BA_ "GenSigSendType" SG_ 1365 VFCVectorVCUVFCid6 1;
BA_ "GenSigSendType" SG_ 1365 VFCVectorVCUVFCid60 1;
BA_ "GenSigSendType" SG_ 1365 VFCVectorVCUVFCid61 1;
BA_ "GenSigSendType" SG_ 1365 VFCVectorVCUVFCid7 1;
BA_ "GenSigSendType" SG_ 1365 VFCVectorVCUVFCid8 1;
BA_ "GenSigSendType" SG_ 1365 VFCVectorVCUVFCid9 1;
BA_ "GenSigSendType" SG_ 896 VehBattUSysU 0;
BA_ "GenSigSendType" SG_ 896 VehBattUSysUQf 0;
BA_ "GenSigStartValue" SG_ 896 VehBattUSysUQf 1;
BA_ "GenSigSendType" SG_ 592 VehCfgPrmBlkIDBytePosn1 1;
BA_ "GenSigSendType" SG_ 592 VehCfgPrmCCPBytePosn2 1;
BA_ "GenSigSendType" SG_ 592 VehCfgPrmCCPBytePosn3 1;
BA_ "GenSigSendType" SG_ 592 VehCfgPrmCCPBytePosn4 1;
BA_ "GenSigSendType" SG_ 592 VehCfgPrmCCPBytePosn5 1;
BA_ "GenSigSendType" SG_ 592 VehCfgPrmCCPBytePosn6 1;
BA_ "GenSigSendType" SG_ 592 VehCfgPrmCCPBytePosn7 1;
BA_ "GenSigSendType" SG_ 592 VehCfgPrmCCPBytePosn8 1;
BA_ "GenSigSendType" SG_ 1015 VehCfgPrmExtBlkIDBytePosn1 1;
BA_ "GenSigSendType" SG_ 1015 VehCfgPrmExtCCPBytePosn2 1;
BA_ "GenSigSendType" SG_ 1015 VehCfgPrmExtCCPBytePosn3 1;
BA_ "GenSigSendType" SG_ 1015 VehCfgPrmExtCCPBytePosn4 1;
BA_ "GenSigSendType" SG_ 1015 VehCfgPrmExtCCPBytePosn5 1;
BA_ "GenSigSendType" SG_ 1015 VehCfgPrmExtCCPBytePosn6 1;
BA_ "GenSigSendType" SG_ 1015 VehCfgPrmExtCCPBytePosn7 1;
BA_ "GenSigSendType" SG_ 1015 VehCfgPrmExtCCPBytePosn8 1;
BA_ "GenSigSendType" SG_ 736 VehModMngtGlbSafe1CarModSts1 0;
BA_ "GenSigSendType" SG_ 736 VehModMngtGlbSafe1CarModSubtypWdCarModSubtyp 0;
BA_ "GenSigDataID" SG_ 736 VehModMngtGlbSafe1Chks "0x74";
BA_ "GenSigFuncType" SG_ 736 VehModMngtGlbSafe1Chks 15;
BA_ "GenSigSendType" SG_ 736 VehModMngtGlbSafe1Chks 0;
BA_ "GenSigFuncType" SG_ 736 VehModMngtGlbSafe1Cntr 16;
BA_ "GenSigSendType" SG_ 736 VehModMngtGlbSafe1Cntr 0;
BA_ "GenSigSendType" SG_ 736 VehModMngtGlbSafe1EgyLvlElecMai 0;
BA_ "GenSigSendType" SG_ 736 VehModMngtGlbSafe1EgyLvlElecSubtyp 0;
BA_ "GenSigSendType" SG_ 736 VehModMngtGlbSafe1FltEgyCnsWdSts 0;
BA_ "GenSigSendType" SG_ 736 VehModMngtGlbSafe1PwrLvlElecMai 0;
BA_ "GenSigSendType" SG_ 736 VehModMngtGlbSafe1PwrLvlElecSubtyp 0;
BA_ "GenSigSendType" SG_ 736 VehModMngtGlbSafe1UsgModSts 0;
BA_ "GenSigStartValue" SG_ 736 VehModMngtGlbSafe1UsgModSts 1;
BA_ "GenSigDataID" SG_ 1159 VehMtnStChks "0x36";
BA_ "GenSigFuncType" SG_ 1159 VehMtnStChks 15;
BA_ "GenSigSendType" SG_ 1159 VehMtnStChks 0;
BA_ "GenSigFuncType" SG_ 1159 VehMtnStCntr 16;
BA_ "GenSigSendType" SG_ 1159 VehMtnStCntr 0;
BA_ "GenSigSendType" SG_ 1159 VehMtnStVehMtnSt 0;
BA_ "GenSigSendType" SG_ 224 VehSpdLgtA 0;
BA_ "GenSigDataID" SG_ 224 VehSpdLgtChks "0x37";
BA_ "GenSigFuncType" SG_ 224 VehSpdLgtChks 15;
BA_ "GenSigSendType" SG_ 224 VehSpdLgtChks 0;
BA_ "GenSigFuncType" SG_ 224 VehSpdLgtCntr 16;
BA_ "GenSigSendType" SG_ 224 VehSpdLgtCntr 0;
BA_ "GenSigSendType" SG_ 224 VehSpdLgtQf 0;
BA_ "GenSigStartValue" SG_ 224 VehSpdLgtQf 1;
BA_ "GenSigSendType" SG_ 928 WhlBrkWrm 0;
BA_ "GenSigSendType" SG_ 137 WhlFastSpdSafeA 0;
BA_ "GenSigDataID" SG_ 137 WhlFastSpdSafeChks "0x1972";
BA_ "GenSigFuncType" SG_ 137 WhlFastSpdSafeChks 15;
BA_ "GenSigSendType" SG_ 137 WhlFastSpdSafeChks 0;
BA_ "GenSigFuncType" SG_ 137 WhlFastSpdSafeCntr 16;
BA_ "GenSigSendType" SG_ 137 WhlFastSpdSafeCntr 0;
BA_ "GenSigSendType" SG_ 137 WhlFastSpdSafeQF 0;
BA_ "GenSigStartValue" SG_ 137 WhlFastSpdSafeQF 1;
BA_ "GenSigDataID" SG_ 1099 WhlRotToothCntrChks "0x19C8";
BA_ "GenSigFuncType" SG_ 1099 WhlRotToothCntrChks 15;
BA_ "GenSigSendType" SG_ 1099 WhlRotToothCntrChks 0;
BA_ "GenSigFuncType" SG_ 1099 WhlRotToothCntrCntr 16;
BA_ "GenSigSendType" SG_ 1099 WhlRotToothCntrCntr 0;
BA_ "GenSigSendType" SG_ 1099 WhlRotToothCntrFrntLe 0;
BA_ "GenSigSendType" SG_ 1099 WhlRotToothCntrFrntRi 0;
BA_ "GenSigSendType" SG_ 1099 WhlRotToothCntrReLe 0;
BA_ "GenSigSendType" SG_ 1099 WhlRotToothCntrReRi 0;
BA_ "GenSigDataID" SG_ 433 WhlSpdCircumlFrntChks "0x6F";
BA_ "GenSigFuncType" SG_ 433 WhlSpdCircumlFrntChks 15;
BA_ "GenSigSendType" SG_ 433 WhlSpdCircumlFrntChks 0;
BA_ "GenSigFuncType" SG_ 433 WhlSpdCircumlFrntCntr 16;
BA_ "GenSigSendType" SG_ 433 WhlSpdCircumlFrntCntr 0;
BA_ "GenSigSendType" SG_ 433 WhlSpdCircumlFrntLe 0;
BA_ "GenSigSendType" SG_ 433 WhlSpdCircumlFrntLeQf 0;
BA_ "GenSigStartValue" SG_ 433 WhlSpdCircumlFrntLeQf 1;
BA_ "GenSigSendType" SG_ 433 WhlSpdCircumlFrntRiQf 0;
BA_ "GenSigStartValue" SG_ 433 WhlSpdCircumlFrntRiQf 1;
BA_ "GenSigSendType" SG_ 433 WhlSpdCircumlFrntWhlSpdCircumlFrntRi 0;
BA_ "GenSigDataID" SG_ 439 WhlSpdCircumlReChks "0x7C";
BA_ "GenSigFuncType" SG_ 439 WhlSpdCircumlReChks 15;
BA_ "GenSigSendType" SG_ 439 WhlSpdCircumlReChks 0;
BA_ "GenSigFuncType" SG_ 439 WhlSpdCircumlReCntr 16;
BA_ "GenSigSendType" SG_ 439 WhlSpdCircumlReCntr 0;
BA_ "GenSigSendType" SG_ 439 WhlSpdCircumlReLe 0;
BA_ "GenSigSendType" SG_ 439 WhlSpdCircumlReLeQf 0;
BA_ "GenSigStartValue" SG_ 439 WhlSpdCircumlReLeQf 1;
BA_ "GenSigSendType" SG_ 439 WhlSpdCircumlReRi 0;
BA_ "GenSigSendType" SG_ 439 WhlSpdCircumlReRiQf 0;
BA_ "GenSigStartValue" SG_ 439 WhlSpdCircumlReRiQf 1;
VAL_ 263 TrsmFltIndcn 0 "TrsmFltIndcn1_TrsmFltIndcnNoReq" 1 "TrsmFltIndcn1_TrsmFltIndcn1" 2 "TrsmFltIndcn1_TrsmFltIndcn2" 3 "TrsmFltIndcn1_TrsmFltIndcn3" 4 "TrsmFltIndcn1_TrsmFltIndcn4" 5 "TrsmFltIndcn1_TrsmFltIndcn5" 6 "TrsmFltIndcn1_TrsmFltIndcn6" 7 "TrsmFltIndcn1_TrsmFltIndcn7" 8 "TrsmFltIndcn1_TrsmFltIndcn8" 9 "TrsmFltIndcn1_TrsmFltIndcn9" 10 "TrsmFltIndcn1_TrsmFltIndcn10" 11 "TrsmFltIndcn1_TrsmFltIndcn11" 12 "TrsmFltIndcn1_TrsmFltIndcn12" 13 "TrsmFltIndcn1_TrsmFltIndcn13" 14 "TrsmFltIndcn1_TrsmFltIndcn14" 15 "TrsmFltIndcn1_TrsmFltIndcn15" 16 "TrsmFltIndcn1_TrsmFltIndcn16" 17 "TrsmFltIndcn1_TrsmFltIndcn17" 18 "TrsmFltIndcn1_TrsmFltIndcn18" 19 "TrsmFltIndcn1_TrsmFltIndcn19" 20 "TrsmFltIndcn1_TrsmFltIndcn20" 21 "TrsmFltIndcn1_TrsmFltIndcn21" 22 "TrsmFltIndcn1_TrsmFltIndcn22" 23 "TrsmFltIndcn1_TrsmFltIndcn23" 24 "TrsmFltIndcn1_TrsmFltIndcn24" 25 "TrsmFltIndcn1_TrsmFltIndcn25" 26 "TrsmFltIndcn1_TrsmFltIndcn26" 27 "TrsmFltIndcn1_TrsmFltIndcn27" 28 "TrsmFltIndcn1_TrsmFltIndcn28" 29 "TrsmFltIndcn1_TrsmFltIndcn29" 30 "TrsmFltIndcn1_TrsmFltIndcn30" 31 "TrsmFltIndcn1_TrsmFltIndcn31";
VAL_ 756 VFCVectorPCMVFCid0 0 "VFCOnOff_Off" 1 "VFCOnOff_On";
VAL_ 756 VFCVectorPCMVFCid1 0 "VFCOnOff_Off" 1 "VFCOnOff_On";
VAL_ 756 VFCVectorPCMVFCid10 0 "VFCOnOff_Off" 1 "VFCOnOff_On";
VAL_ 756 VFCVectorPCMVFCid11 0 "VFCOnOff_Off" 1 "VFCOnOff_On";
VAL_ 756 VFCVectorPCMVFCid12 0 "VFCOnOff_Off" 1 "VFCOnOff_On";
VAL_ 756 VFCVectorPCMVFCid13 0 "VFCOnOff_Off" 1 "VFCOnOff_On";
VAL_ 756 VFCVectorPCMVFCid14 0 "VFCOnOff_Off" 1 "VFCOnOff_On";
VAL_ 756 VFCVectorPCMVFCid15 0 "VFCOnOff_Off" 1 "VFCOnOff_On";
VAL_ 756 VFCVectorPCMVFCid16 0 "VFCOnOff_Off" 1 "VFCOnOff_On";
VAL_ 756 VFCVectorPCMVFCid17 0 "VFCOnOff_Off" 1 "VFCOnOff_On";
VAL_ 756 VFCVectorPCMVFCid18 0 "VFCOnOff_Off" 1 "VFCOnOff_On";
VAL_ 756 VFCVectorPCMVFCid19 0 "VFCOnOff_Off" 1 "VFCOnOff_On";
VAL_ 756 VFCVectorPCMVFCid2 0 "VFCOnOff_Off" 1 "VFCOnOff_On";
VAL_ 756 VFCVectorPCMVFCid20 0 "VFCOnOff_Off" 1 "VFCOnOff_On";
VAL_ 756 VFCVectorPCMVFCid21 0 "VFCOnOff_Off" 1 "VFCOnOff_On";
VAL_ 756 VFCVectorPCMVFCid22 0 "VFCOnOff_Off" 1 "VFCOnOff_On";
VAL_ 756 VFCVectorPCMVFCid23 0 "VFCOnOff_Off" 1 "VFCOnOff_On";
VAL_ 756 VFCVectorPCMVFCid24 0 "VFCOnOff_Off" 1 "VFCOnOff_On";
VAL_ 756 VFCVectorPCMVFCid25 0 "VFCOnOff_Off" 1 "VFCOnOff_On";
VAL_ 756 VFCVectorPCMVFCid26 0 "VFCOnOff_Off" 1 "VFCOnOff_On";
VAL_ 756 VFCVectorPCMVFCid27 0 "VFCOnOff_Off" 1 "VFCOnOff_On";
VAL_ 756 VFCVectorPCMVFCid28 0 "VFCOnOff_Off" 1 "VFCOnOff_On";
VAL_ 756 VFCVectorPCMVFCid29 0 "VFCOnOff_Off" 1 "VFCOnOff_On";
VAL_ 756 VFCVectorPCMVFCid3 0 "VFCOnOff_Off" 1 "VFCOnOff_On";
VAL_ 756 VFCVectorPCMVFCid30 0 "VFCOnOff_Off" 1 "VFCOnOff_On";
VAL_ 756 VFCVectorPCMVFCid31 0 "VFCOnOff_Off" 1 "VFCOnOff_On";
VAL_ 756 VFCVectorPCMVFCid32 0 "VFCOnOff_Off" 1 "VFCOnOff_On";
VAL_ 756 VFCVectorPCMVFCid33 0 "VFCOnOff_Off" 1 "VFCOnOff_On";
VAL_ 756 VFCVectorPCMVFCid34 0 "VFCOnOff_Off" 1 "VFCOnOff_On";
VAL_ 756 VFCVectorPCMVFCid35 0 "VFCOnOff_Off" 1 "VFCOnOff_On";
VAL_ 756 VFCVectorPCMVFCid36 0 "VFCOnOff_Off" 1 "VFCOnOff_On";
VAL_ 756 VFCVectorPCMVFCid37 0 "VFCOnOff_Off" 1 "VFCOnOff_On";
VAL_ 756 VFCVectorPCMVFCid38 0 "VFCOnOff_Off" 1 "VFCOnOff_On";
VAL_ 756 VFCVectorPCMVFCid39 0 "VFCOnOff_Off" 1 "VFCOnOff_On";
VAL_ 756 VFCVectorPCMVFCid4 0 "VFCOnOff_Off" 1 "VFCOnOff_On";
VAL_ 756 VFCVectorPCMVFCid40 0 "VFCOnOff_Off" 1 "VFCOnOff_On";
VAL_ 756 VFCVectorPCMVFCid41 0 "VFCOnOff_Off" 1 "VFCOnOff_On";
VAL_ 756 VFCVectorPCMVFCid42 0 "VFCOnOff_Off" 1 "VFCOnOff_On";
VAL_ 756 VFCVectorPCMVFCid43 0 "VFCOnOff_Off" 1 "VFCOnOff_On";
VAL_ 756 VFCVectorPCMVFCid44 0 "VFCOnOff_Off" 1 "VFCOnOff_On";
VAL_ 756 VFCVectorPCMVFCid45 0 "VFCOnOff_Off" 1 "VFCOnOff_On";
VAL_ 756 VFCVectorPCMVFCid46 0 "VFCOnOff_Off" 1 "VFCOnOff_On";
VAL_ 756 VFCVectorPCMVFCid47 0 "VFCOnOff_Off" 1 "VFCOnOff_On";
VAL_ 756 VFCVectorPCMVFCid48 0 "VFCOnOff_Off" 1 "VFCOnOff_On";
VAL_ 756 VFCVectorPCMVFCid49 0 "VFCOnOff_Off" 1 "VFCOnOff_On";
VAL_ 756 VFCVectorPCMVFCid5 0 "VFCOnOff_Off" 1 "VFCOnOff_On";
VAL_ 756 VFCVectorPCMVFCid50 0 "VFCOnOff_Off" 1 "VFCOnOff_On";
VAL_ 756 VFCVectorPCMVFCid51 0 "VFCOnOff_Off" 1 "VFCOnOff_On";
VAL_ 756 VFCVectorPCMVFCid52 0 "VFCOnOff_Off" 1 "VFCOnOff_On";
VAL_ 756 VFCVectorPCMVFCid53 0 "VFCOnOff_Off" 1 "VFCOnOff_On";
VAL_ 756 VFCVectorPCMVFCid54 0 "VFCOnOff_Off" 1 "VFCOnOff_On";
VAL_ 756 VFCVectorPCMVFCid55 0 "VFCOnOff_Off" 1 "VFCOnOff_On";
VAL_ 756 VFCVectorPCMVFCid56 0 "VFCOnOff_Off" 1 "VFCOnOff_On";
VAL_ 756 VFCVectorPCMVFCid57 0 "VFCOnOff_Off" 1 "VFCOnOff_On";
VAL_ 756 VFCVectorPCMVFCid58 0 "VFCOnOff_Off" 1 "VFCOnOff_On";
VAL_ 756 VFCVectorPCMVFCid59 0 "VFCOnOff_Off" 1 "VFCOnOff_On";
VAL_ 756 VFCVectorPCMVFCid6 0 "VFCOnOff_Off" 1 "VFCOnOff_On";
VAL_ 756 VFCVectorPCMVFCid60 0 "VFCOnOff_Off" 1 "VFCOnOff_On";
VAL_ 756 VFCVectorPCMVFCid61 0 "VFCOnOff_Off" 1 "VFCOnOff_On";
VAL_ 756 VFCVectorPCMVFCid7 0 "VFCOnOff_Off" 1 "VFCOnOff_On";
VAL_ 756 VFCVectorPCMVFCid8 0 "VFCOnOff_Off" 1 "VFCOnOff_On";
VAL_ 756 VFCVectorPCMVFCid9 0 "VFCOnOff_Off" 1 "VFCOnOff_On";
VAL_ 274 SecParkBrkSysSt2BrkSysSt 0 "NotAvailable_Temporary" 1 "NotAvailable_NotReleased" 2 "NotAvailable_Permanent" 3 "NotActivated_FullAvailable" 4 "Activation_Preparation" 5 "Activation_Pending" 6 "Activation_PendingRedundancyLost" 7 "Activation_PendingFailOperation" 8 "Activated_FullAvailable" 9 "Activated_FailOperation" 10 "Activated_RedundancyLost" 11 "Deactivation_Pending";
VAL_ 85 AgDataRaw2SafePitchRateQf 0 "Qf1_DevOfDataUndefd" 1 "Qf1_DataTmpUndefdAndEvlnInProgs" 2 "Qf1_DevOfDataNotWithinRngAllwd" 3 "Qf1_DataCalcdWithDevDefd";
VAL_ 375 HvSysRlyStsHvSysRlySts 0 "HvActvnSts_Open" 1 "HvActvnSts_Clsd" 2 "HvActvnSts_KeepSt" 3 "HvActvnSts_OpenAndReqActvDcha";
VAL_ 375 RlyPwrDistbnCmd1WdIgnRlyCmd 0 "OnOff1_Off" 1 "OnOff1_On";
VAL_ 342 TiAndDateIndcnDataValid 0 "NoYes1_No" 1 "NoYes1_Yes";
VAL_ 1365 VFCVectorVCUVFCid0 0 "VFCOnOff_Off" 1 "VFCOnOff_On";
VAL_ 1365 VFCVectorVCUVFCid1 0 "VFCOnOff_Off" 1 "VFCOnOff_On";
VAL_ 1365 VFCVectorVCUVFCid10 0 "VFCOnOff_Off" 1 "VFCOnOff_On";
VAL_ 1365 VFCVectorVCUVFCid11 0 "VFCOnOff_Off" 1 "VFCOnOff_On";
VAL_ 1365 VFCVectorVCUVFCid12 0 "VFCOnOff_Off" 1 "VFCOnOff_On";
VAL_ 1365 VFCVectorVCUVFCid13 0 "VFCOnOff_Off" 1 "VFCOnOff_On";
VAL_ 1365 VFCVectorVCUVFCid14 0 "VFCOnOff_Off" 1 "VFCOnOff_On";
VAL_ 1365 VFCVectorVCUVFCid15 0 "VFCOnOff_Off" 1 "VFCOnOff_On";
VAL_ 1365 VFCVectorVCUVFCid16 0 "VFCOnOff_Off" 1 "VFCOnOff_On";
VAL_ 1365 VFCVectorVCUVFCid17 0 "VFCOnOff_Off" 1 "VFCOnOff_On";
VAL_ 1365 VFCVectorVCUVFCid18 0 "VFCOnOff_Off" 1 "VFCOnOff_On";
VAL_ 1365 VFCVectorVCUVFCid19 0 "VFCOnOff_Off" 1 "VFCOnOff_On";
VAL_ 1365 VFCVectorVCUVFCid2 0 "VFCOnOff_Off" 1 "VFCOnOff_On";
VAL_ 1365 VFCVectorVCUVFCid20 0 "VFCOnOff_Off" 1 "VFCOnOff_On";
VAL_ 1365 VFCVectorVCUVFCid21 0 "VFCOnOff_Off" 1 "VFCOnOff_On";
VAL_ 1365 VFCVectorVCUVFCid22 0 "VFCOnOff_Off" 1 "VFCOnOff_On";
VAL_ 1365 VFCVectorVCUVFCid23 0 "VFCOnOff_Off" 1 "VFCOnOff_On";
VAL_ 1365 VFCVectorVCUVFCid24 0 "VFCOnOff_Off" 1 "VFCOnOff_On";
VAL_ 1365 VFCVectorVCUVFCid25 0 "VFCOnOff_Off" 1 "VFCOnOff_On";
VAL_ 1365 VFCVectorVCUVFCid26 0 "VFCOnOff_Off" 1 "VFCOnOff_On";
VAL_ 1365 VFCVectorVCUVFCid27 0 "VFCOnOff_Off" 1 "VFCOnOff_On";
VAL_ 1365 VFCVectorVCUVFCid28 0 "VFCOnOff_Off" 1 "VFCOnOff_On";
VAL_ 1365 VFCVectorVCUVFCid29 0 "VFCOnOff_Off" 1 "VFCOnOff_On";
VAL_ 1365 VFCVectorVCUVFCid3 0 "VFCOnOff_Off" 1 "VFCOnOff_On";
VAL_ 1365 VFCVectorVCUVFCid30 0 "VFCOnOff_Off" 1 "VFCOnOff_On";
VAL_ 1365 VFCVectorVCUVFCid31 0 "VFCOnOff_Off" 1 "VFCOnOff_On";
VAL_ 1365 VFCVectorVCUVFCid32 0 "VFCOnOff_Off" 1 "VFCOnOff_On";
VAL_ 1365 VFCVectorVCUVFCid33 0 "VFCOnOff_Off" 1 "VFCOnOff_On";
VAL_ 1365 VFCVectorVCUVFCid34 0 "VFCOnOff_Off" 1 "VFCOnOff_On";
VAL_ 1365 VFCVectorVCUVFCid35 0 "VFCOnOff_Off" 1 "VFCOnOff_On";
VAL_ 1365 VFCVectorVCUVFCid36 0 "VFCOnOff_Off" 1 "VFCOnOff_On";
VAL_ 1365 VFCVectorVCUVFCid37 0 "VFCOnOff_Off" 1 "VFCOnOff_On";
VAL_ 1365 VFCVectorVCUVFCid38 0 "VFCOnOff_Off" 1 "VFCOnOff_On";
VAL_ 1365 VFCVectorVCUVFCid39 0 "VFCOnOff_Off" 1 "VFCOnOff_On";
VAL_ 1365 VFCVectorVCUVFCid4 0 "VFCOnOff_Off" 1 "VFCOnOff_On";
VAL_ 1365 VFCVectorVCUVFCid40 0 "VFCOnOff_Off" 1 "VFCOnOff_On";
VAL_ 1365 VFCVectorVCUVFCid41 0 "VFCOnOff_Off" 1 "VFCOnOff_On";
VAL_ 1365 VFCVectorVCUVFCid42 0 "VFCOnOff_Off" 1 "VFCOnOff_On";
VAL_ 1365 VFCVectorVCUVFCid43 0 "VFCOnOff_Off" 1 "VFCOnOff_On";
VAL_ 1365 VFCVectorVCUVFCid44 0 "VFCOnOff_Off" 1 "VFCOnOff_On";
VAL_ 1365 VFCVectorVCUVFCid45 0 "VFCOnOff_Off" 1 "VFCOnOff_On";
VAL_ 1365 VFCVectorVCUVFCid46 0 "VFCOnOff_Off" 1 "VFCOnOff_On";
VAL_ 1365 VFCVectorVCUVFCid47 0 "VFCOnOff_Off" 1 "VFCOnOff_On";
VAL_ 1365 VFCVectorVCUVFCid48 0 "VFCOnOff_Off" 1 "VFCOnOff_On";
VAL_ 1365 VFCVectorVCUVFCid49 0 "VFCOnOff_Off" 1 "VFCOnOff_On";
VAL_ 1365 VFCVectorVCUVFCid5 0 "VFCOnOff_Off" 1 "VFCOnOff_On";
VAL_ 1365 VFCVectorVCUVFCid50 0 "VFCOnOff_Off" 1 "VFCOnOff_On";
VAL_ 1365 VFCVectorVCUVFCid51 0 "VFCOnOff_Off" 1 "VFCOnOff_On";
VAL_ 1365 VFCVectorVCUVFCid52 0 "VFCOnOff_Off" 1 "VFCOnOff_On";
VAL_ 1365 VFCVectorVCUVFCid53 0 "VFCOnOff_Off" 1 "VFCOnOff_On";
VAL_ 1365 VFCVectorVCUVFCid54 0 "VFCOnOff_Off" 1 "VFCOnOff_On";
VAL_ 1365 VFCVectorVCUVFCid55 0 "VFCOnOff_Off" 1 "VFCOnOff_On";
VAL_ 1365 VFCVectorVCUVFCid56 0 "VFCOnOff_Off" 1 "VFCOnOff_On";
VAL_ 1365 VFCVectorVCUVFCid57 0 "VFCOnOff_Off" 1 "VFCOnOff_On";
VAL_ 1365 VFCVectorVCUVFCid58 0 "VFCOnOff_Off" 1 "VFCOnOff_On";
VAL_ 1365 VFCVectorVCUVFCid59 0 "VFCOnOff_Off" 1 "VFCOnOff_On";
VAL_ 1365 VFCVectorVCUVFCid6 0 "VFCOnOff_Off" 1 "VFCOnOff_On";
VAL_ 1365 VFCVectorVCUVFCid60 0 "VFCOnOff_Off" 1 "VFCOnOff_On";
VAL_ 1365 VFCVectorVCUVFCid61 0 "VFCOnOff_Off" 1 "VFCOnOff_On";
VAL_ 1365 VFCVectorVCUVFCid7 0 "VFCOnOff_Off" 1 "VFCOnOff_On";
VAL_ 1365 VFCVectorVCUVFCid8 0 "VFCOnOff_Off" 1 "VFCOnOff_On";
VAL_ 1365 VFCVectorVCUVFCid9 0 "VFCOnOff_Off" 1 "VFCOnOff_On";
VAL_ 81 AsyDataWithCmpSafeALat1Qf 0 "Qf1_DevOfDataUndefd" 1 "Qf1_DataTmpUndefdAndEvlnInProgs" 2 "Qf1_DevOfDataNotWithinRngAllwd" 3 "Qf1_DataCalcdWithDevDefd";
VAL_ 81 AsyDataWithCmpSafeALgt1Qf 0 "Qf1_DevOfDataUndefd" 1 "Qf1_DataTmpUndefdAndEvlnInProgs" 2 "Qf1_DevOfDataNotWithinRngAllwd" 3 "Qf1_DataCalcdWithDevDefd";
VAL_ 81 AsyDataWithCmpSafeYawRateQf 0 "Qf1_DevOfDataUndefd" 1 "Qf1_DataTmpUndefdAndEvlnInProgs" 2 "Qf1_DevOfDataNotWithinRngAllwd" 3 "Qf1_DataCalcdWithDevDefd";
VAL_ 160 ADataRawSafeALat1Qf 0 "Qf1_DevOfDataUndefd" 1 "Qf1_DataTmpUndefdAndEvlnInProgs" 2 "Qf1_DevOfDataNotWithinRngAllwd" 3 "Qf1_DataCalcdWithDevDefd";
VAL_ 160 ADataRawSafeALgt1Qf 0 "Qf1_DevOfDataUndefd" 1 "Qf1_DataTmpUndefdAndEvlnInProgs" 2 "Qf1_DevOfDataNotWithinRngAllwd" 3 "Qf1_DataCalcdWithDevDefd";
VAL_ 160 ADataRawSafeAVertQf 0 "Qf1_DevOfDataUndefd" 1 "Qf1_DataTmpUndefdAndEvlnInProgs" 2 "Qf1_DevOfDataNotWithinRngAllwd" 3 "Qf1_DataCalcdWithDevDefd";
VAL_ 400 AbsCtrlActvCtrlSts1 0 "CtrlSts1_NoCtrl" 1 "CtrlSts1_InCtrl";
VAL_ 400 AmbTRawQly 0 "GenQf1_UndefindDataAccur" 1 "GenQf1_TmpUndefdData" 2 "GenQf1_DataAccurNotWithinSpcn" 3 "GenQf1_AccurData";
VAL_ 400 LatCtrlReqSafeLatCtrlModReq 0 "LatCtrlMod1_NoReq" 1 "LatCtrlMod1_HighWayAssist" 2 "LatCtrlMod1_EmgyLaneKeepAidForObjRe" 3 "LatCtrlMod1_EmgyLaneKeepAidForStat" 4 "LatCtrlMod1_SftyLaneKeepAid" 5 "LatCtrlMod1_SteerAssc" 6 "LatCtrlMod1_DsrOversteer" 7 "LatCtrlMod1_DsrMueSplit" 8 "LatCtrlMod1_DsrTrlrStaby" 9 "LatCtrlMod1_EmgyManvAssi" 10 "LatCtrlMod1_Reserved1" 11 "LatCtrlMod1_Reserved2" 12 "LatCtrlMod1_SHWA" 13 "LatCtrlMod1_APA" 14 "LatCtrlMod1_RPA" 15 "LatCtrlMod1_HPA";
VAL_ 400 LatCtrlReqSafeSteerWhlHptcWarnReq 0 "OnOff1_Off" 1 "OnOff1_On";
VAL_ 224 CnvnReq 0 "CnvnReq_NotReqd" 1 "CnvnReq_Chrgn" 2 "CnvnReq_Resd1" 3 "CnvnReq_Resd2" 4 "CnvnReq_Resd3" 5 "CnvnReq_Resd4" 6 "CnvnReq_Resd5" 7 "CnvnReq_Resd6";
VAL_ 224 DrvrCrsCtrlFctSeld 0 "DrvrCrsCtrlFctSeldTyp_Off" 1 "DrvrCrsCtrlFctSeldTyp_SpdLimFct_Main_Swt" 2 "DrvrCrsCtrlFctSeldTyp_SpdLimFct_Resu" 3 "DrvrCrsCtrlFctSeldTyp_CrsCtrlFct_Main_Swt" 4 "DrvrCrsCtrlFctSeldTyp_CrsCtrlFct_Resu" 5 "DrvrCrsCtrlFctSeldTyp_AccFct_Main_Swt" 6 "DrvrCrsCtrlFctSeldTyp_AccFct_Resu" 7 "DrvrCrsCtrlFctSeldTyp_OffRoadCrsCtrlFc";
VAL_ 224 EngRunngReqByParkAssi1 0 "EngRunngReqByParkAssi1_Default" 1 "EngRunngReqByParkAssi1_StopInhibited" 2 "EngRunngReqByParkAssi1_RequestToKeepTheEngineRunning" 3 "EngRunngReqByParkAssi1_Reserved";
VAL_ 224 VehSpdLgtQf 0 "GenQf1_UndefindDataAccur" 1 "GenQf1_TmpUndefdData" 2 "GenQf1_DataAccurNotWithinSpcn" 3 "GenQf1_AccurData";
VAL_ 928 AmbTIndcdWithUnitAmbTIndcdUnit 0 "AmbTIndcdUnit_Celsius" 1 "AmbTIndcdUnit_Fahrenheit" 2 "AmbTIndcdUnit_UkwnUnit";
VAL_ 928 AmbTIndcdWithUnitQF 0 "GenQf1_UndefindDataAccur" 1 "GenQf1_TmpUndefdData" 2 "GenQf1_DataAccurNotWithinSpcn" 3 "GenQf1_AccurData";
VAL_ 928 WhlBrkWrm 0 "NoYes1_No" 1 "NoYes1_Yes";
VAL_ 433 BrkPedlPsdBrkPedlNotPsdSafe 0 "NoYes1_No" 1 "NoYes1_Yes";
VAL_ 433 BrkPedlPsdBrkPedlPsd 0 "NoYes1_No" 1 "NoYes1_Yes";
VAL_ 433 BrkPedlPsdQf 0 "GenQf1_UndefindDataAccur" 1 "GenQf1_TmpUndefdData" 2 "GenQf1_DataAccurNotWithinSpcn" 3 "GenQf1_AccurData";
VAL_ 433 WhlSpdCircumlFrntLeQf 0 "GenQf1_UndefindDataAccur" 1 "GenQf1_TmpUndefdData" 2 "GenQf1_DataAccurNotWithinSpcn" 3 "GenQf1_AccurData";
VAL_ 433 WhlSpdCircumlFrntRiQf 0 "GenQf1_UndefindDataAccur" 1 "GenQf1_TmpUndefdData" 2 "GenQf1_DataAccurNotWithinSpcn" 3 "GenQf1_AccurData";
VAL_ 432 AgDataRawSafeRollRateQf 0 "Qf1_DevOfDataUndefd" 1 "Qf1_DataTmpUndefdAndEvlnInProgs" 2 "Qf1_DevOfDataNotWithinRngAllwd" 3 "Qf1_DataCalcdWithDevDefd";
VAL_ 432 AgDataRawSafeYawRateQf 0 "Qf1_DevOfDataUndefd" 1 "Qf1_DataTmpUndefdAndEvlnInProgs" 2 "Qf1_DevOfDataNotWithinRngAllwd" 3 "Qf1_DataCalcdWithDevDefd";
VAL_ 367 TrsmLockMgrReqCmd 0 "TrsmLockMgrCmd_Undefd" 1 "TrsmLockMgrCmd_Unlck" 2 "TrsmLockMgrCmd_Lock" 3 "TrsmLockMgrCmd_Resd";
VAL_ 736 AutEgyRgnLvlSet 0 "EgyRgnLvlAct_Low" 1 "EgyRgnLvlAct_Mid" 2 "EgyRgnLvlAct_High" 3 "EgyRgnLvlAct_Reserved1" 4 "EgyRgnLvlAct_Reserved2" 5 "EgyRgnLvlAct_Auto" 6 "EgyRgnLvlAct_Off" 7 "EgyRgnLvlAct_NoReq";
VAL_ 736 ChrgNowReq 0 "Boolean_FALSE" 1 "Boolean_TRUE";
VAL_ 736 VehModMngtGlbSafe1CarModSts1 0 "CarModSts1_CarModNorm" 1 "CarModSts1_CarModTrnsp" 2 "CarModSts1_CarModFcy" 3 "CarModSts1_CarModCrash" 5 "CarModSts1_CarModDyno";
VAL_ 736 VehModMngtGlbSafe1FltEgyCnsWdSts 0 "FltEgyCns1_NoFlt" 1 "FltEgyCns1_Flt";
VAL_ 736 VehModMngtGlbSafe1UsgModSts 0 "UsgModSts1_UsgModAbdnd" 1 "UsgModSts1_UsgModInActv" 2 "UsgModSts1_UsgModCnvinc" 11 "UsgModSts1_UsgModActv" 13 "UsgModSts1_UsgModDrvg";
VAL_ 38 ChrgSoftSwCtrlSt 0 "OnOffNoReq_NoReq" 1 "OnOffNoReq_On" 2 "OnOffNoReq_Off";
VAL_ 38 IntelliClimaReq 0 "CmptSts_NoRequest" 1 "CmptSts_CoolingRequest" 2 "CmptSts_HeatingRequest" 3 "CmptSts_CoolingAndHeatingRequest" 4 "CmptSts_PostHeating";
VAL_ 38 VFCInfoEna 0 "EnableDisableCoding_Disabled" 1 "EnableDisableCoding_Enabled";
VAL_ 1123 EvaprTReEvaprTQf 0 "HvacTIfQf_SnsrDataNotOk" 1 "HvacTIfQf_SnsrDataOk";
VAL_ 1123 SteerSetgPen 0 "IdPen_ProfUkwn" 1 "IdPen_Prof1" 2 "IdPen_Prof2" 3 "IdPen_Prof3" 4 "IdPen_Prof4" 5 "IdPen_Prof5" 6 "IdPen_Prof6" 7 "IdPen_Prof7" 8 "IdPen_Prof8" 9 "IdPen_Prof9" 10 "IdPen_Prof10" 11 "IdPen_Prof11" 12 "IdPen_Prof12" 13 "IdPen_Prof13" 14 "IdPen_Resd14" 15 "IdPen_ProfAll";
VAL_ 1123 SteerSetgSteerAsscLvl 0 "SteerAsscLvl_Ukwn" 1 "SteerAsscLvl_Lvl1" 2 "SteerAsscLvl_Lvl2" 3 "SteerAsscLvl_Lvl3" 4 "SteerAsscLvl_Lvl4" 5 "SteerAsscLvl_Resd5" 6 "SteerAsscLvl_Resd6" 7 "SteerAsscLvl_Resd7";
VAL_ 1123 SteerSetgSteerMod 0 "SteerMod_Ukwn" 1 "SteerMod_Mod1" 2 "SteerMod_Mod2" 3 "SteerMod_Mod3" 4 "SteerMod_Mod4" 5 "SteerMod_Resd5" 6 "SteerMod_Resd6" 7 "SteerMod_Resd7";
VAL_ 784 CmptmtTFrntFanForCmptmtTRunng 0 "Flg1_Rst" 1 "Flg1_Set";
VAL_ 784 CmptmtTFrntQf 0 "CmptmtTFrntQf_SnsrDataUndefd" 1 "CmptmtTFrntQf_FanNotRunning" 2 "CmptmtTFrntQf_SnsrDataNotOk" 3 "CmptmtTFrntQf_SnsrDataOk";
VAL_ 137 HsaSt 0 "YesNo2_No" 1 "YesNo2_Yes";
VAL_ 137 LVPwrSplyErrSts 0 "PwrSplyErrSts_SysOk" 1 "PwrSplyErrSts_UhiDurgDrvg" 2 "PwrSplyErrSts_UloDurgdrvg" 3 "PwrSplyErrSts_BattRlyFlt" 4 "PwrSplyErrSts_BattSnsrComFlt" 5 "PwrSplyErrSts_BattSnsrHwFlt" 6 "PwrSplyErrSts_FltComDcDc" 7 "PwrSplyErrSts_FltElecDcDc" 8 "PwrSplyErrSts_FltDcDc" 9 "PwrSplyErrSts_SupCptrHwFlt" 10 "PwrSplyErrSts_AltFltMecl" 11 "PwrSplyErrSts_AltFltElec" 12 "PwrSplyErrSts_AltFltT" 13 "PwrSplyErrSts_AltFltCom" 14 "PwrSplyErrSts_SpprtBattFltChrgn" 15 "PwrSplyErrSts_Spare6";
VAL_ 137 WhlFastSpdSafeQF 0 "GenQf1_UndefindDataAccur" 1 "GenQf1_TmpUndefdData" 2 "GenQf1_DataAccurNotWithinSpcn" 3 "GenQf1_AccurData";
VAL_ 775 BookChrgnActvdReq 0 "Boolean_FALSE" 1 "Boolean_TRUE";
VAL_ 775 BookChrgSetReq 0 "Boolean_FALSE" 1 "Boolean_TRUE";
VAL_ 775 BookStopTiAchieved 0 "Boolean_FALSE" 1 "Boolean_TRUE";
VAL_ 823 ClimaCmptSts 0 "CmptSts_NoRequest" 1 "CmptSts_CoolingRequest" 2 "CmptSts_HeatingRequest" 3 "CmptSts_CoolingAndHeatingRequest" 4 "CmptSts_PostHeating";
VAL_ 823 ClimaDefrstSts 0 "OnOff1_Off" 1 "OnOff1_On";
VAL_ 686 AbsSts 0 "DevErrSts2_NoFlt" 1 "DevErrSts2_Flt";
VAL_ 686 DrvModReq 0 "DrvModReqType1_Undefd" 1 "DrvModReqType1_ECO" 2 "DrvModReqType1_Comfort_Normal" 3 "DrvModReqType1_Dynamic_Sport" 4 "DrvModReqType1_Individual" 5 "DrvModReqType1_Offroad_CrossTerrain" 6 "DrvModReqType1_Adaptive" 7 "DrvModReqType1_Race" 8 "DrvModReqType1_Pure_EV" 9 "DrvModReqType1_Hybrid" 10 "DrvModReqType1_Power" 11 "DrvModReqType1_Snow" 12 "DrvModReqType1_Sand" 13 "DrvModReqType1_Mud" 14 "DrvModReqType1_Rock" 15 "DrvModReqType1_Err";
VAL_ 686 HvacHexAirTHvacAirTForHeatrFrntQf 0 "OkNotOk_NotOk" 1 "OkNotOk_Ok";
VAL_ 686 TelmBookChrgnReq 0 "OnOffNoReq_NoReq" 1 "OnOffNoReq_On" 2 "OnOffNoReq_Off";
VAL_ 686 TelmBookChrgnTyp 0 "TelmBookChrgnTyp_Idle" 1 "TelmBookChrgnTyp_Off" 2 "TelmBookChrgnTyp_SingleBooking" 3 "TelmBookChrgnTyp_CyclicBooking" 4 "TelmBookChrgnTyp_PlugInBooking";
VAL_ 686 ULoWarnULoWarn 0 "ULoWarn_UOk" 1 "ULoWarn_ULoTmp" 2 "ULoWarn_ULoPrmnt";
VAL_ 1267 EscStEscSt 0 "EscSt1_Inin" 1 "EscSt1_Ok" 2 "EscSt1_TmpErr" 3 "EscSt1_PrmntErr" 4 "EscSt1_UsrOff";
VAL_ 1099 BrkTracCtrlActv 0 "CtrlSts1_NoCtrl" 1 "CtrlSts1_InCtrl";
VAL_ 1099 HvacHeatgReq 0 "OnOff1_Off" 1 "OnOff1_On";
VAL_ 26 EgyRgnLvlSet 0 "EgyRgnLvlSet_Level1" 1 "EgyRgnLvlSet_Level2" 2 "EgyRgnLvlSet_Level3" 3 "EgyRgnLvlSet_Level4";
VAL_ 1159 VehMtnStVehMtnSt 0 "VehMtnSt2_Ukwn" 1 "VehMtnSt2_StandStillVal1" 2 "VehMtnSt2_StandStillVal2" 3 "VehMtnSt2_StandStillVal3" 4 "VehMtnSt2_RollgFwdVal1" 5 "VehMtnSt2_RollgFwdVal2" 6 "VehMtnSt2_RollgBackwVal1" 7 "VehMtnSt2_RollgBackwVal2";
VAL_ 864 HvacHeatrInletTempReqEvaprTQf 0 "HvacTIfQf_SnsrDataNotOk" 1 "HvacTIfQf_SnsrDataOk";
VAL_ 864 ProfPenSts1 0 "IdPen_ProfUkwn" 1 "IdPen_Prof1" 2 "IdPen_Prof2" 3 "IdPen_Prof3" 4 "IdPen_Prof4" 5 "IdPen_Prof5" 6 "IdPen_Prof6" 7 "IdPen_Prof7" 8 "IdPen_Prof8" 9 "IdPen_Prof9" 10 "IdPen_Prof10" 11 "IdPen_Prof11" 12 "IdPen_Prof12" 13 "IdPen_Prof13" 14 "IdPen_Resd14" 15 "IdPen_ProfAll";
VAL_ 864 SaveSetgToMemPrmnt 0 "OffOnAut1_Off" 1 "OffOnAut1_On" 2 "OffOnAut1_Aut";
VAL_ 896 HMIAutoShowModSet 0 "OnOff1_Off" 1 "OnOff1_On";
VAL_ 896 TotDstToEmptyDstUnit 0 "DstUnit_km" 1 "DstUnit_miles";
VAL_ 896 VehBattUSysUQf 0 "GenQf1_UndefindDataAccur" 1 "GenQf1_TmpUndefdData" 2 "GenQf1_DataAccurNotWithinSpcn" 3 "GenQf1_AccurData";
VAL_ 513 ImobEngMgrReq3ImobEngMgrCmdTar1 0 "ImobEngMgrReqCmd_ImobEngCmdTarIdle" 1 "ImobEngMgrReqCmd_ImobEngMtnStrtReqCmd" 2 "ImobEngMgrReqCmd_ImobEngNoMtnStrtReqCmd" 3 "ImobEngMgrReqCmd_ImobEngTurnOffCmd";
VAL_ 17 GearPrkgAssiReqGroupGearPrkgAssiReq1 0 "GearPrkgAssiReq1_NoRequest" 1 "GearPrkgAssiReq1_TargetgearP" 2 "GearPrkgAssiReq1_TargetgearR" 3 "GearPrkgAssiReq1_TargetgearD";
VAL_ 17 LgtCtrlModReqSafeLgtCtrlModReqSafe 0 "ModCfmd_NoReq" 1 "ModCfmd_E2E" 2 "ModCfmd_Reserved2" 3 "ModCfmd_Reserved3" 4 "ModCfmd_Reserved4" 5 "ModCfmd_Reserved5" 6 "ModCfmd_Reserved6" 7 "ModCfmd_Reserved7" 8 "ModCfmd_Reserved8" 9 "ModCfmd_ACC_HWA" 10 "ModCfmd_PEB" 11 "ModCfmd_APA" 12 "ModCfmd_RPA" 13 "ModCfmd_HPA" 14 "ModCfmd_TJP_HWC" 15 "ModCfmd_NOP";
VAL_ 17 LgtCtrlModReqSafeLgtFctFailr 0 "LgtFctFail_NoFailure" 1 "LgtFctFail_TJP_HWCFailure" 2 "LgtFctFail_APAFailure" 3 "LgtFctFail_RPAFailure" 4 "LgtFctFail_HPAFailure" 5 "LgtFctFail_HWAFailure" 6 "LgtFctFail_NOPFailure" 7 "LgtFctFail_E2EFailure";
VAL_ 17 OffroadCoolgSwtSts 0 "OnOff1_Off" 1 "OnOff1_On";
VAL_ 17 PrpsnHvBattUsgModReq 0 "HvBattUsgType_NoReq" 1 "HvBattUsgType_Norm" 2 "HvBattUsgType_Hld" 3 "HvBattUsgType_HldSmt" 4 "HvBattUsgType_Chrg" 5 "HvBattUsgType_NotOfUse1" 6 "HvBattUsgType_NotOfUse2" 7 "HvBattUsgType_NotOfUse3";
VAL_ 496 DrvModReqForChampnMod 0 "SteerMod_Ukwn" 1 "SteerMod_Mod1" 2 "SteerMod_Mod2" 3 "SteerMod_Mod3" 4 "SteerMod_Mod4" 5 "SteerMod_Resd5" 6 "SteerMod_Resd6" 7 "SteerMod_Resd7";
VAL_ 496 ESCLvlSwt 0 "DrvrPfmncLvl2_Ukwn" 1 "DrvrPfmncLvl2_DrvrLvl1" 2 "DrvrPfmncLvl2_DrvrLvl2" 3 "DrvrPfmncLvl2_DrvrLvl3" 4 "DrvrPfmncLvl2_DrvrLvl4" 5 "DrvrPfmncLvl2_DrvrLvl5";
VAL_ 496 StandStillMgrStsForHld1 0 "StandStillMgrStsForHld1_StandStillMgrStsForHldVal0" 1 "StandStillMgrStsForHld1_StandStillMgrStsForHldVal1" 2 "StandStillMgrStsForHld1_StandStillMgrStsForHldVal2" 3 "StandStillMgrStsForHld1_StandStillMgrStsForHldVal3" 4 "StandStillMgrStsForHld1_StandStillMgrStsForHldVal4" 5 "StandStillMgrStsForHld1_StandStillMgrStsForHldVal5" 6 "StandStillMgrStsForHld1_StandStillMgrStsForHldVal6" 7 "StandStillMgrStsForHld1_StandStillMgrStsForHldVal7";
VAL_ 439 WhlSpdCircumlReLeQf 0 "GenQf1_UndefindDataAccur" 1 "GenQf1_TmpUndefdData" 2 "GenQf1_DataAccurNotWithinSpcn" 3 "GenQf1_AccurData";
VAL_ 439 WhlSpdCircumlReRiQf 0 "GenQf1_UndefindDataAccur" 1 "GenQf1_TmpUndefdData" 2 "GenQf1_DataAccurNotWithinSpcn" 3 "GenQf1_AccurData";
VAL_ 52 CrashStsSafeSts 0 "CrashSts2_NoCrash" 1 "CrashSts2_Crash";
VAL_ 614 CmptmtAirDistbnRspAirDistbnDrvr 0 "HmiCmptmtAirDistbnFrnt_Flr" 1 "HmiCmptmtAirDistbnFrnt_Vent" 2 "HmiCmptmtAirDistbnFrnt_Defrst" 3 "HmiCmptmtAirDistbnFrnt_FlrDefrst" 4 "HmiCmptmtAirDistbnFrnt_FlrVent" 5 "HmiCmptmtAirDistbnFrnt_VentDefrst" 6 "HmiCmptmtAirDistbnFrnt_FlrVentDefrst" 7 "HmiCmptmtAirDistbnFrnt_Aut";
VAL_ 614 CmptmtAirDistbnRspAirDistbnPass 0 "HmiCmptmtAirDistbnFrnt_Flr" 1 "HmiCmptmtAirDistbnFrnt_Vent" 2 "HmiCmptmtAirDistbnFrnt_Defrst" 3 "HmiCmptmtAirDistbnFrnt_FlrDefrst" 4 "HmiCmptmtAirDistbnFrnt_FlrVent" 5 "HmiCmptmtAirDistbnFrnt_VentDefrst" 6 "HmiCmptmtAirDistbnFrnt_FlrVentDefrst" 7 "HmiCmptmtAirDistbnFrnt_Aut";
VAL_ 614 CmptmtAirDistbnRspAirDistbnSecLe 0 "HmiCmptmtAirDistbnFrnt_Flr" 1 "HmiCmptmtAirDistbnFrnt_Vent" 2 "HmiCmptmtAirDistbnFrnt_Defrst" 3 "HmiCmptmtAirDistbnFrnt_FlrDefrst" 4 "HmiCmptmtAirDistbnFrnt_FlrVent" 5 "HmiCmptmtAirDistbnFrnt_VentDefrst" 6 "HmiCmptmtAirDistbnFrnt_FlrVentDefrst" 7 "HmiCmptmtAirDistbnFrnt_Aut";
VAL_ 614 CmptmtAirDistbnRspAirDistbnSecRi 0 "HmiCmptmtAirDistbnFrnt_Flr" 1 "HmiCmptmtAirDistbnFrnt_Vent" 2 "HmiCmptmtAirDistbnFrnt_Defrst" 3 "HmiCmptmtAirDistbnFrnt_FlrDefrst" 4 "HmiCmptmtAirDistbnFrnt_FlrVent" 5 "HmiCmptmtAirDistbnFrnt_VentDefrst" 6 "HmiCmptmtAirDistbnFrnt_FlrVentDefrst" 7 "HmiCmptmtAirDistbnFrnt_Aut";
VAL_ 614 CmptmtAirDistbnRspAirDistbnThrd 0 "HmiCmptmtAirDistbnFrnt_Flr" 1 "HmiCmptmtAirDistbnFrnt_Vent" 2 "HmiCmptmtAirDistbnFrnt_Defrst" 3 "HmiCmptmtAirDistbnFrnt_FlrDefrst" 4 "HmiCmptmtAirDistbnFrnt_FlrVent" 5 "HmiCmptmtAirDistbnFrnt_VentDefrst" 6 "HmiCmptmtAirDistbnFrnt_FlrVentDefrst" 7 "HmiCmptmtAirDistbnFrnt_Aut";
VAL_ 194 HvahAirTEstmdEvaprTQf 0 "HvacTIfQf_SnsrDataNotOk" 1 "HvacTIfQf_SnsrDataOk";
VAL_ 194 ShowTypOfDTESet 0 "ShowTyp1_NoReq" 1 "ShowTyp1_NormalType" 2 "ShowTyp1_DynamicType";
SIG_GROUP_ 400 AbsCtrlActv 1 : AbsCtrlActvChks AbsCtrlActvCntr AbsCtrlActvCtrlSts1;
SIG_GROUP_ 160 ADataRawSafe 1 : ADataRawSafeALat ADataRawSafeALat1Qf ADataRawSafeALgt ADataRawSafeALgt1Qf ADataRawSafeAVert ADataRawSafeAVertQf ADataRawSafeChks ADataRawSafeCntr;
SIG_GROUP_ 26 AgDataCmpQuality 1 : AgDataCmpQualityPitchRateCmpQuality AgDataCmpQualityRollRateCmpQuality AgDataCmpQualityYawRateCmpQuality;
SIG_GROUP_ 85 AgDataRaw2Safe 1 : AgDataRaw2SafeChks AgDataRaw2SafeCntr AgDataRaw2SafePitchRate AgDataRaw2SafePitchRateQf;
SIG_GROUP_ 432 AgDataRawSafe 1 : AgDataRawSafeChks AgDataRawSafeCntr AgDataRawSafeRollRate AgDataRawSafeRollRateQf AgDataRawSafeYawRate AgDataRawSafeYawRateQf;
SIG_GROUP_ 928 AmbTIndcdWithUnit 1 : AmbTIndcdWithUnitAmbTIndcd AmbTIndcdWithUnitAmbTIndcdUnit AmbTIndcdWithUnitQF;
SIG_GROUP_ 400 AmbTRaw 1 : AmbTRawAmbTVal AmbTRawQly;
SIG_GROUP_ 81 AsyDataWithCmpSafe 1 : AsyDataWithCmpSafeALat1Qf AsyDataWithCmpSafeALatWithCmp AsyDataWithCmpSafeALgt1Qf AsyDataWithCmpSafeChks AsyDataWithCmpSafeCntr AsyDataWithCmpSafeGrdtOfALgt AsyDataWithCmpSafeYawRateQf AsyDataWithCmpSafeYawRateWithCmp;
SIG_GROUP_ 433 BrkPedlPsd 1 : BrkPedlPsdBrkPedlNotPsdSafe BrkPedlPsdBrkPedlPsd BrkPedlPsdChks BrkPedlPsdCntr BrkPedlPsdQf;
SIG_GROUP_ 614 CmptmtAirDistbnRsp 1 : CmptmtAirDistbnRspAirDistbnDrvr CmptmtAirDistbnRspAirDistbnPass CmptmtAirDistbnRspAirDistbnSecLe CmptmtAirDistbnRspAirDistbnSecRi CmptmtAirDistbnRspAirDistbnThrd;
SIG_GROUP_ 784 CmptmtTFrnt 1 : CmptmtTFrntCmptmtTFrnt CmptmtTFrntFanForCmptmtTRunng CmptmtTFrntQf;
SIG_GROUP_ 52 CrashStsSafe 1 : CrashStsSafeChks CrashStsSafeCntr CrashStsSafeSts;
SIG_GROUP_ 224 EngRunngReqByParkAssi 1 : EngRunngReqByParkAssi1 EngRunngReqByParkAssiChks EngRunngReqByParkAssiCntr;
SIG_GROUP_ 1267 EscSt 1 : EscStChks EscStCntr EscStEscSt;
SIG_GROUP_ 1123 EvaprTRe 1 : EvaprTReEvaprTFrnt EvaprTReEvaprTQf;
SIG_GROUP_ 17 GearPrkgAssiReqGroup 1 : GearPrkgAssiReqGroupChks GearPrkgAssiReqGroupCntr GearPrkgAssiReqGroupGearPrkgAssiReq1;
SIG_GROUP_ 864 HvacHeatrInletTempReq 1 : HvacHeatrInletTempReqEvaprTFrnt HvacHeatrInletTempReqEvaprTQf;
SIG_GROUP_ 686 HvacHexAirT 1 : HvacHexAirTHvacAirTForHeatrFrnt HvacHexAirTHvacAirTForHeatrFrntQf;
SIG_GROUP_ 194 HvahAirTEstmd 1 : HvahAirTEstmdEvaprTFrnt HvahAirTEstmdEvaprTQf;
SIG_GROUP_ 375 HvSysRlySts 1 : HvSysRlyStsChks HvSysRlyStsCntr HvSysRlyStsHvSysRlySts;
SIG_GROUP_ 580 IDcDcActLoSide 1 : IDcDcActLoSideChks IDcDcActLoSideCntr IDcDcActLoSideIDcDcActLoSide;
SIG_GROUP_ 513 ImobEngMgrReq3 1 : ImobEngMgrReq3ImobEngDataMgrReq0 ImobEngMgrReq3ImobEngDataMgrReq1 ImobEngMgrReq3ImobEngDataMgrReq2 ImobEngMgrReq3ImobEngDataMgrReq3 ImobEngMgrReq3ImobEngDataMgrReq4 ImobEngMgrReq3ImobEngDataMgrReq5 ImobEngMgrReq3ImobEngDataMgrReq6 ImobEngMgrReq3ImobEngMgrCmdTar1;
SIG_GROUP_ 400 LatCtrlReqSafe 1 : LatCtrlReqSafeChks LatCtrlReqSafeCntr LatCtrlReqSafeLatCtrlModReq LatCtrlReqSafeSteerTqReq LatCtrlReqSafeSteerWhlHptcWarnReq;
SIG_GROUP_ 17 LgtCtrlModReqSafe 1 : LgtCtrlModReqSafeChks LgtCtrlModReqSafeCntr LgtCtrlModReqSafeLgtCtrlModReqSafe LgtCtrlModReqSafeLgtFctFailr;
SIG_GROUP_ 274 SecParkBrkSysSt2 1 : SecParkBrkSysSt2BrkSysSt SecParkBrkSysSt2Chks SecParkBrkSysSt2Cntr;
SIG_GROUP_ 496 StandStillMgrStsForHld 1 : StandStillMgrStsForHld1 StandStillMgrStsForHldChks StandStillMgrStsForHldCntr;
SIG_GROUP_ 1123 SteerSetg 1 : SteerSetgPen SteerSetgSteerAsscLvl SteerSetgSteerMod;
SIG_GROUP_ 342 TiAndDateIndcn 1 : TiAndDateIndcnDataValid TiAndDateIndcnDay TiAndDateIndcnHr1 TiAndDateIndcnMins1 TiAndDateIndcnMth1 TiAndDateIndcnSec1 TiAndDateIndcnYr1;
SIG_GROUP_ 896 TotDstToEmpty 1 : TotDstToEmptyDstToEmpty TotDstToEmptyDstUnit;
SIG_GROUP_ 326 TrsmEngNTqMax 1 : TrsmEngNTqMaxChks TrsmEngNTqMaxCntr TrsmEngNTqMaxTrsmEngNTqMax;
SIG_GROUP_ 367 TrsmLockMgrReq 1 : TrsmLockMgrReqCmd TrsmLockMgrReqData0 TrsmLockMgrReqData1 TrsmLockMgrReqData2 TrsmLockMgrReqData3 TrsmLockMgrReqData4 TrsmLockMgrReqData5 TrsmLockMgrReqData6;
SIG_GROUP_ 686 ULoWarn 1 : ULoWarnChks ULoWarnCntr ULoWarnULoWarn;
SIG_GROUP_ 1434 VDDMdevelpsignalgroupresp1 1 : VDDMdevelpsignalgroupresp1Functiondevpsignalgroup1 VDDMdevelpsignalgroupresp1Functiondevpsignalgroup2 VDDMdevelpsignalgroupresp1Functiondevpsignalgroup3 VDDMdevelpsignalgroupresp1Functiondevpsignalgroup4 VDDMdevelpsignalgroupresp1Functiondevpsignalgroup5 VDDMdevelpsignalgroupresp1Functiondevpsignalgroup6 VDDMdevelpsignalgroupresp1Functiondevpsignalgroup7 VDDMdevelpsignalgroupresp1Functiondevpsignalgroup8;
SIG_GROUP_ 1435 VDDMdevelpsignalgroupresp2 1 : VDDMdevelpsignalgroupresp2Functiondevpsignalgroup1 VDDMdevelpsignalgroupresp2Functiondevpsignalgroup2 VDDMdevelpsignalgroupresp2Functiondevpsignalgroup3 VDDMdevelpsignalgroupresp2Functiondevpsignalgroup4 VDDMdevelpsignalgroupresp2Functiondevpsignalgroup5 VDDMdevelpsignalgroupresp2Functiondevpsignalgroup6 VDDMdevelpsignalgroupresp2Functiondevpsignalgroup7 VDDMdevelpsignalgroupresp2Functiondevpsignalgroup8;
SIG_GROUP_ 896 VehBattU 1 : VehBattUSysU VehBattUSysUQf;
SIG_GROUP_ 592 VehCfgPrm 1 : VehCfgPrmBlkIDBytePosn1 VehCfgPrmCCPBytePosn2 VehCfgPrmCCPBytePosn3 VehCfgPrmCCPBytePosn4 VehCfgPrmCCPBytePosn5 VehCfgPrmCCPBytePosn6 VehCfgPrmCCPBytePosn7 VehCfgPrmCCPBytePosn8;
SIG_GROUP_ 1015 VehCfgPrmExt 1 : VehCfgPrmExtBlkIDBytePosn1 VehCfgPrmExtCCPBytePosn2 VehCfgPrmExtCCPBytePosn3 VehCfgPrmExtCCPBytePosn4 VehCfgPrmExtCCPBytePosn5 VehCfgPrmExtCCPBytePosn6 VehCfgPrmExtCCPBytePosn7 VehCfgPrmExtCCPBytePosn8;
SIG_GROUP_ 736 VehModMngtGlbSafe1 1 : VehModMngtGlbSafe1CarModSts1 VehModMngtGlbSafe1CarModSubtypWdCarModSubtyp VehModMngtGlbSafe1Chks VehModMngtGlbSafe1Cntr VehModMngtGlbSafe1EgyLvlElecMai VehModMngtGlbSafe1EgyLvlElecSubtyp VehModMngtGlbSafe1FltEgyCnsWdSts VehModMngtGlbSafe1PwrLvlElecMai VehModMngtGlbSafe1PwrLvlElecSubtyp VehModMngtGlbSafe1UsgModSts;
SIG_GROUP_ 1159 VehMtnSt 1 : VehMtnStChks VehMtnStCntr VehMtnStVehMtnSt;
SIG_GROUP_ 224 VehSpdLgt 1 : VehSpdLgtA VehSpdLgtChks VehSpdLgtCntr VehSpdLgtQf;
SIG_GROUP_ 756 VFCVectorPCM 1 : VFCVectorPCMBlockID VFCVectorPCMVFCid0 VFCVectorPCMVFCid1 VFCVectorPCMVFCid10 VFCVectorPCMVFCid11 VFCVectorPCMVFCid12 VFCVectorPCMVFCid13 VFCVectorPCMVFCid14 VFCVectorPCMVFCid15 VFCVectorPCMVFCid16 VFCVectorPCMVFCid17 VFCVectorPCMVFCid18 VFCVectorPCMVFCid19 VFCVectorPCMVFCid2 VFCVectorPCMVFCid20 VFCVectorPCMVFCid21 VFCVectorPCMVFCid22 VFCVectorPCMVFCid23 VFCVectorPCMVFCid24 VFCVectorPCMVFCid25 VFCVectorPCMVFCid26 VFCVectorPCMVFCid27 VFCVectorPCMVFCid28 VFCVectorPCMVFCid29 VFCVectorPCMVFCid3 VFCVectorPCMVFCid30 VFCVectorPCMVFCid31 VFCVectorPCMVFCid32 VFCVectorPCMVFCid33 VFCVectorPCMVFCid34 VFCVectorPCMVFCid35 VFCVectorPCMVFCid36 VFCVectorPCMVFCid37 VFCVectorPCMVFCid38 VFCVectorPCMVFCid39 VFCVectorPCMVFCid4 VFCVectorPCMVFCid40 VFCVectorPCMVFCid41 VFCVectorPCMVFCid42 VFCVectorPCMVFCid43 VFCVectorPCMVFCid44 VFCVectorPCMVFCid45 VFCVectorPCMVFCid46 VFCVectorPCMVFCid47 VFCVectorPCMVFCid48 VFCVectorPCMVFCid49 VFCVectorPCMVFCid5 VFCVectorPCMVFCid50 VFCVectorPCMVFCid51 VFCVectorPCMVFCid52 VFCVectorPCMVFCid53 VFCVectorPCMVFCid54 VFCVectorPCMVFCid55 VFCVectorPCMVFCid56 VFCVectorPCMVFCid57 VFCVectorPCMVFCid58 VFCVectorPCMVFCid59 VFCVectorPCMVFCid6 VFCVectorPCMVFCid60 VFCVectorPCMVFCid61 VFCVectorPCMVFCid7 VFCVectorPCMVFCid8 VFCVectorPCMVFCid9;
SIG_GROUP_ 1365 VFCVectorVCU 1 : VFCVectorVCUBlockID VFCVectorVCUVFCid0 VFCVectorVCUVFCid1 VFCVectorVCUVFCid10 VFCVectorVCUVFCid11 VFCVectorVCUVFCid12 VFCVectorVCUVFCid13 VFCVectorVCUVFCid14 VFCVectorVCUVFCid15 VFCVectorVCUVFCid16 VFCVectorVCUVFCid17 VFCVectorVCUVFCid18 VFCVectorVCUVFCid19 VFCVectorVCUVFCid2 VFCVectorVCUVFCid20 VFCVectorVCUVFCid21 VFCVectorVCUVFCid22 VFCVectorVCUVFCid23 VFCVectorVCUVFCid24 VFCVectorVCUVFCid25 VFCVectorVCUVFCid26 VFCVectorVCUVFCid27 VFCVectorVCUVFCid28 VFCVectorVCUVFCid29 VFCVectorVCUVFCid3 VFCVectorVCUVFCid30 VFCVectorVCUVFCid31 VFCVectorVCUVFCid32 VFCVectorVCUVFCid33 VFCVectorVCUVFCid34 VFCVectorVCUVFCid35 VFCVectorVCUVFCid36 VFCVectorVCUVFCid37 VFCVectorVCUVFCid38 VFCVectorVCUVFCid39 VFCVectorVCUVFCid4 VFCVectorVCUVFCid40 VFCVectorVCUVFCid41 VFCVectorVCUVFCid42 VFCVectorVCUVFCid43 VFCVectorVCUVFCid44 VFCVectorVCUVFCid45 VFCVectorVCUVFCid46 VFCVectorVCUVFCid47 VFCVectorVCUVFCid48 VFCVectorVCUVFCid49 VFCVectorVCUVFCid5 VFCVectorVCUVFCid50 VFCVectorVCUVFCid51 VFCVectorVCUVFCid52 VFCVectorVCUVFCid53 VFCVectorVCUVFCid54 VFCVectorVCUVFCid55 VFCVectorVCUVFCid56 VFCVectorVCUVFCid57 VFCVectorVCUVFCid58 VFCVectorVCUVFCid59 VFCVectorVCUVFCid6 VFCVectorVCUVFCid60 VFCVectorVCUVFCid61 VFCVectorVCUVFCid7 VFCVectorVCUVFCid8 VFCVectorVCUVFCid9;
SIG_GROUP_ 137 WhlFastSpdSafe 1 : WhlFastSpdSafeA WhlFastSpdSafeChks WhlFastSpdSafeCntr WhlFastSpdSafeQF;
SIG_GROUP_ 1099 WhlRotToothCntr 1 : WhlRotToothCntrChks WhlRotToothCntrCntr WhlRotToothCntrFrntLe WhlRotToothCntrFrntRi WhlRotToothCntrReLe WhlRotToothCntrReRi;
SIG_GROUP_ 433 WhlSpdCircumlFrnt 1 : WhlSpdCircumlFrntChks WhlSpdCircumlFrntCntr WhlSpdCircumlFrntLe WhlSpdCircumlFrntLeQf WhlSpdCircumlFrntRiQf WhlSpdCircumlFrntWhlSpdCircumlFrntRi;
SIG_GROUP_ 439 WhlSpdCircumlRe 1 : WhlSpdCircumlReChks WhlSpdCircumlReCntr WhlSpdCircumlReLe WhlSpdCircumlReLeQf WhlSpdCircumlReRi WhlSpdCircumlReRiQf;
